VERSION ""

NS_ :

BS_:

BU_: ILC4 ILC3 ILC2 ILC1 C1 C0 ACU ECAS2 CCU TPMS ACC AEBS Door4 Door3 Door2 Door1 WWCU HVAC HVAC_HMI EPHS LDWS SCSM EVCC ECAS1 BMS SWS EBS VCU2 PCi_ECM DCU EPH VFC VCU1 Tachograph EPIC

BO_ 2566834735 DM1_ECAS1: 22 ECAS1
 SG_ FailureModeIdentifier5 : 160|5@1+ (1,0) [0|0] "" Vector__XXX
 SG_ FailureModeIdentifier4 : 128|5@1+ (1,0) [0|0] "" Vector__XXX
 SG_ FailureModeIdentifier3 : 96|5@1+ (1,0) [0|0] "" Vector__XXX
 SG_ FailureModeIdentifier2 : 64|5@1+ (1,0) [0|0] "" Vector__XXX
 SG_ OccurenceCount5 : 168|7@1+ (1,0) [0|126] "" Vector__XXX
 SG_ OccurenceCount4 : 136|7@1+ (1,0) [0|126] "" Vector__XXX
 SG_ OccurenceCount3 : 104|7@1+ (1,0) [0|126] "" Vector__XXX
 SG_ OccurenceCount2 : 72|7@1+ (1,0) [0|126] "" Vector__XXX
 SG_ SPNConversionMethod5 : 175|1@1+ (1,0) [0|1] "" Vector__XXX
 SG_ SPNConversionMethod4 : 143|1@1+ (1,0) [0|1] "" Vector__XXX
 SG_ SPNConversionMethod3 : 111|1@1+ (1,0) [0|1] "" Vector__XXX
 SG_ SPNConversionMethod2 : 79|1@1+ (1,0) [0|1] "" Vector__XXX
 SG_ SPN5High : 165|3@1+ (1,0) [0|7] "" Vector__XXX
 SG_ SPN5 : 144|16@1+ (1,0) [0|65536] "" Vector__XXX
 SG_ SPN4High : 133|3@1+ (1,0) [0|7] "" Vector__XXX
 SG_ SPN4 : 112|16@1+ (1,0) [0|65536] "" Vector__XXX
 SG_ SPN3High : 101|3@1+ (1,0) [0|7] "" Vector__XXX
 SG_ SPN3 : 80|16@1+ (1,0) [0|65536] "" Vector__XXX
 SG_ SPN2High : 69|3@1+ (1,0) [0|7] "" Vector__XXX
 SG_ SPN2 : 48|16@1+ (1,0) [0|65536] "" Vector__XXX
 SG_ SPN1 : 16|16@1+ (1,0) [0|65536] "" Vector__XXX
 SG_ SPNConversionMethod1 : 47|1@1+ (1,0) [0|1] "" Vector__XXX
 SG_ OccurenceCount1 : 40|7@1+ (1,0) [0|126] "" Vector__XXX
 SG_ SPN1High : 37|3@1+ (1,0) [0|7] "" Vector__XXX
 SG_ FailureModeIdentifier1 : 32|5@1+ (1,0) [0|0] "" Vector__XXX
 SG_ FlashMalfuncIndicatorLamp : 14|2@1+ (1,0) [0|3] "" Vector__XXX
 SG_ FlashRedStopLamp : 12|2@1+ (1,0) [0|3] "" Vector__XXX
 SG_ FlashAmberWarningLamp : 10|2@1+ (1,0) [0|3] "" Vector__XXX
 SG_ FlashProtectLamp : 8|2@1+ (1,0) [0|3] "" Vector__XXX
 SG_ MalfunctionIndicatorLampStatus : 6|2@1+ (1,0) [0|3] "" Vector__XXX
 SG_ RedStopLampState : 4|2@1+ (1,0) [0|3] "" Vector__XXX
 SG_ AmberWarningLampStatus : 2|2@1+ (1,0) [0|3] "" Vector__XXX
 SG_ ProtectLampStatus : 0|2@1+ (1,0) [0|3] "" Vector__XXX

BO_ 2566834699 DM1_EBS: 22 EBS
 SG_ FailureModeIdentifier5 : 160|5@1+ (1,0) [0|0] "" Vector__XXX
 SG_ FailureModeIdentifier4 : 128|5@1+ (1,0) [0|0] "" Vector__XXX
 SG_ FailureModeIdentifier3 : 96|5@1+ (1,0) [0|0] "" Vector__XXX
 SG_ FailureModeIdentifier2 : 64|5@1+ (1,0) [0|0] "" Vector__XXX
 SG_ OccurenceCount5 : 168|7@1+ (1,0) [0|126] "" Vector__XXX
 SG_ OccurenceCount4 : 136|7@1+ (1,0) [0|126] "" Vector__XXX
 SG_ OccurenceCount3 : 104|7@1+ (1,0) [0|126] "" Vector__XXX
 SG_ OccurenceCount2 : 72|7@1+ (1,0) [0|126] "" Vector__XXX
 SG_ SPNConversionMethod5 : 175|1@1+ (1,0) [0|1] "" Vector__XXX
 SG_ SPNConversionMethod4 : 143|1@1+ (1,0) [0|1] "" Vector__XXX
 SG_ SPNConversionMethod3 : 111|1@1+ (1,0) [0|1] "" Vector__XXX
 SG_ SPNConversionMethod2 : 79|1@1+ (1,0) [0|1] "" Vector__XXX
 SG_ SPN5High : 165|3@1+ (1,0) [0|7] "" Vector__XXX
 SG_ SPN5 : 144|16@1+ (1,0) [0|65536] "" Vector__XXX
 SG_ SPN4High : 133|3@1+ (1,0) [0|7] "" Vector__XXX
 SG_ SPN4 : 112|16@1+ (1,0) [0|65536] "" Vector__XXX
 SG_ SPN3High : 101|3@1+ (1,0) [0|7] "" Vector__XXX
 SG_ SPN3 : 80|16@1+ (1,0) [0|65536] "" Vector__XXX
 SG_ SPN2High : 69|3@1+ (1,0) [0|7] "" Vector__XXX
 SG_ SPN2 : 48|16@1+ (1,0) [0|65536] "" Vector__XXX
 SG_ SPN1 : 16|16@1+ (1,0) [0|65536] "" Vector__XXX
 SG_ SPNConversionMethod1 : 47|1@1+ (1,0) [0|1] "" Vector__XXX
 SG_ OccurenceCount1 : 40|7@1+ (1,0) [0|126] "" Vector__XXX
 SG_ SPN1High : 37|3@1+ (1,0) [0|7] "" Vector__XXX
 SG_ FailureModeIdentifier1 : 32|5@1+ (1,0) [0|0] "" Vector__XXX
 SG_ FlashMalfuncIndicatorLamp : 14|2@1+ (1,0) [0|3] "" Vector__XXX
 SG_ FlashRedStopLamp : 12|2@1+ (1,0) [0|3] "" Vector__XXX
 SG_ FlashAmberWarningLamp : 10|2@1+ (1,0) [0|3] "" Vector__XXX
 SG_ FlashProtectLamp : 8|2@1+ (1,0) [0|3] "" Vector__XXX
 SG_ MalfunctionIndicatorLampStatus : 6|2@1+ (1,0) [0|3] "" Vector__XXX
 SG_ RedStopLampState : 4|2@1+ (1,0) [0|3] "" Vector__XXX
 SG_ AmberWarningLampStatus : 2|2@1+ (1,0) [0|3] "" Vector__XXX
 SG_ ProtectLampStatus : 0|2@1+ (1,0) [0|3] "" Vector__XXX

BO_ 2566834816 DM1_EVCC: 22 EVCC
 SG_ FailureModeIdentifier5 : 160|5@1+ (1,0) [0|0] "" Vector__XXX
 SG_ FailureModeIdentifier4 : 128|5@1+ (1,0) [0|0] "" Vector__XXX
 SG_ FailureModeIdentifier3 : 96|5@1+ (1,0) [0|0] "" Vector__XXX
 SG_ FailureModeIdentifier2 : 64|5@1+ (1,0) [0|0] "" Vector__XXX
 SG_ OccurenceCount5 : 168|7@1+ (1,0) [0|126] "" Vector__XXX
 SG_ OccurenceCount4 : 136|7@1+ (1,0) [0|126] "" Vector__XXX
 SG_ OccurenceCount3 : 104|7@1+ (1,0) [0|126] "" Vector__XXX
 SG_ OccurenceCount2 : 72|7@1+ (1,0) [0|126] "" Vector__XXX
 SG_ SPNConversionMethod5 : 175|1@1+ (1,0) [0|1] "" Vector__XXX
 SG_ SPNConversionMethod4 : 143|1@1+ (1,0) [0|1] "" Vector__XXX
 SG_ SPNConversionMethod3 : 111|1@1+ (1,0) [0|1] "" Vector__XXX
 SG_ SPNConversionMethod2 : 79|1@1+ (1,0) [0|1] "" Vector__XXX
 SG_ SPN5High : 165|3@1+ (1,0) [0|7] "" Vector__XXX
 SG_ SPN5 : 144|16@1+ (1,0) [0|65536] "" Vector__XXX
 SG_ SPN4High : 133|3@1+ (1,0) [0|7] "" Vector__XXX
 SG_ SPN4 : 112|16@1+ (1,0) [0|65536] "" Vector__XXX
 SG_ SPN3High : 101|3@1+ (1,0) [0|7] "" Vector__XXX
 SG_ SPN3 : 80|16@1+ (1,0) [0|65536] "" Vector__XXX
 SG_ SPN2High : 69|3@1+ (1,0) [0|7] "" Vector__XXX
 SG_ SPN2 : 48|16@1+ (1,0) [0|65536] "" Vector__XXX
 SG_ SPN1 : 16|16@1+ (1,0) [0|65536] "" Vector__XXX
 SG_ SPNConversionMethod1 : 47|1@1+ (1,0) [0|1] "" Vector__XXX
 SG_ OccurenceCount1 : 40|7@1+ (1,0) [0|126] "" Vector__XXX
 SG_ SPN1High : 37|3@1+ (1,0) [0|7] "" Vector__XXX
 SG_ FailureModeIdentifier1 : 32|5@1+ (1,0) [0|0] "" Vector__XXX
 SG_ FlashMalfuncIndicatorLamp : 14|2@1+ (1,0) [0|3] "" Vector__XXX
 SG_ FlashRedStopLamp : 12|2@1+ (1,0) [0|3] "" Vector__XXX
 SG_ FlashAmberWarningLamp : 10|2@1+ (1,0) [0|3] "" Vector__XXX
 SG_ FlashProtectLamp : 8|2@1+ (1,0) [0|3] "" Vector__XXX
 SG_ MalfunctionIndicatorLampStatus : 6|2@1+ (1,0) [0|3] "" Vector__XXX
 SG_ RedStopLampState : 4|2@1+ (1,0) [0|3] "" Vector__XXX
 SG_ AmberWarningLampStatus : 2|2@1+ (1,0) [0|3] "" Vector__XXX
 SG_ ProtectLampStatus : 0|2@1+ (1,0) [0|3] "" Vector__XXX

BO_ 2566834688 DM1_ECM: 22 PCi_ECM
 SG_ FailureModeIdentifier5 : 160|5@1+ (1,0) [0|0] "" Vector__XXX
 SG_ FailureModeIdentifier4 : 128|5@1+ (1,0) [0|0] "" Vector__XXX
 SG_ FailureModeIdentifier3 : 96|5@1+ (1,0) [0|0] "" Vector__XXX
 SG_ FailureModeIdentifier2 : 64|5@1+ (1,0) [0|0] "" Vector__XXX
 SG_ OccurenceCount5 : 168|7@1+ (1,0) [0|126] "" Vector__XXX
 SG_ OccurenceCount4 : 136|7@1+ (1,0) [0|126] "" Vector__XXX
 SG_ OccurenceCount3 : 104|7@1+ (1,0) [0|126] "" Vector__XXX
 SG_ OccurenceCount2 : 72|7@1+ (1,0) [0|126] "" Vector__XXX
 SG_ SPNConversionMethod5 : 175|1@1+ (1,0) [0|1] "" Vector__XXX
 SG_ SPNConversionMethod4 : 143|1@1+ (1,0) [0|1] "" Vector__XXX
 SG_ SPNConversionMethod3 : 111|1@1+ (1,0) [0|1] "" Vector__XXX
 SG_ SPNConversionMethod2 : 79|1@1+ (1,0) [0|1] "" Vector__XXX
 SG_ SPN5High : 165|3@1+ (1,0) [0|7] "" Vector__XXX
 SG_ SPN5 : 144|16@1+ (1,0) [0|65536] "" Vector__XXX
 SG_ SPN4High : 133|3@1+ (1,0) [0|7] "" Vector__XXX
 SG_ SPN4 : 112|16@1+ (1,0) [0|65536] "" Vector__XXX
 SG_ SPN3High : 101|3@1+ (1,0) [0|7] "" Vector__XXX
 SG_ SPN3 : 80|16@1+ (1,0) [0|65536] "" Vector__XXX
 SG_ SPN2High : 69|3@1+ (1,0) [0|7] "" Vector__XXX
 SG_ SPN2 : 48|16@1+ (1,0) [0|65536] "" Vector__XXX
 SG_ SPN1 : 16|16@1+ (1,0) [0|65536] "" Vector__XXX
 SG_ SPNConversionMethod1 : 47|1@1+ (1,0) [0|1] "" Vector__XXX
 SG_ OccurenceCount1 : 40|7@1+ (1,0) [0|126] "" Vector__XXX
 SG_ SPN1High : 37|3@1+ (1,0) [0|7] "" Vector__XXX
 SG_ FailureModeIdentifier1 : 32|5@1+ (1,0) [0|0] "" Vector__XXX
 SG_ FlashMalfuncIndicatorLamp : 14|2@1+ (1,0) [0|3] "" Vector__XXX
 SG_ FlashRedStopLamp : 12|2@1+ (1,0) [0|3] "" Vector__XXX
 SG_ FlashAmberWarningLamp : 10|2@1+ (1,0) [0|3] "" Vector__XXX
 SG_ FlashProtectLamp : 8|2@1+ (1,0) [0|3] "" Vector__XXX
 SG_ MalfunctionIndicatorLampStatus : 6|2@1+ (1,0) [0|3] "" Vector__XXX
 SG_ RedStopLampState : 4|2@1+ (1,0) [0|3] "" Vector__XXX
 SG_ AmberWarningLampStatus : 2|2@1+ (1,0) [0|3] "" Vector__XXX
 SG_ ProtectLampStatus : 0|2@1+ (1,0) [0|3] "" Vector__XXX

BO_ 2566834927 DM1_DCU: 22 DCU
 SG_ FailureModeIdentifier5 : 160|5@1+ (1,0) [0|0] "" Vector__XXX
 SG_ FailureModeIdentifier4 : 128|5@1+ (1,0) [0|0] "" Vector__XXX
 SG_ FailureModeIdentifier3 : 96|5@1+ (1,0) [0|0] "" Vector__XXX
 SG_ FailureModeIdentifier2 : 64|5@1+ (1,0) [0|0] "" Vector__XXX
 SG_ OccurenceCount5 : 168|7@1+ (1,0) [0|126] "" Vector__XXX
 SG_ OccurenceCount4 : 136|7@1+ (1,0) [0|126] "" Vector__XXX
 SG_ OccurenceCount3 : 104|7@1+ (1,0) [0|126] "" Vector__XXX
 SG_ OccurenceCount2 : 72|7@1+ (1,0) [0|126] "" Vector__XXX
 SG_ SPNConversionMethod5 : 175|1@1+ (1,0) [0|1] "" Vector__XXX
 SG_ SPNConversionMethod4 : 143|1@1+ (1,0) [0|1] "" Vector__XXX
 SG_ SPNConversionMethod3 : 111|1@1+ (1,0) [0|1] "" Vector__XXX
 SG_ SPNConversionMethod2 : 79|1@1+ (1,0) [0|1] "" Vector__XXX
 SG_ SPN5High : 165|3@1+ (1,0) [0|7] "" Vector__XXX
 SG_ SPN5 : 144|16@1+ (1,0) [0|65536] "" Vector__XXX
 SG_ SPN4High : 133|3@1+ (1,0) [0|7] "" Vector__XXX
 SG_ SPN4 : 112|16@1+ (1,0) [0|65536] "" Vector__XXX
 SG_ SPN3High : 101|3@1+ (1,0) [0|7] "" Vector__XXX
 SG_ SPN3 : 80|16@1+ (1,0) [0|65536] "" Vector__XXX
 SG_ SPN2High : 69|3@1+ (1,0) [0|7] "" Vector__XXX
 SG_ SPN2 : 48|16@1+ (1,0) [0|65536] "" Vector__XXX
 SG_ SPN1 : 16|16@1+ (1,0) [0|65536] "" Vector__XXX
 SG_ SPNConversionMethod1 : 47|1@1+ (1,0) [0|1] "" Vector__XXX
 SG_ OccurenceCount1 : 40|7@1+ (1,0) [0|126] "" Vector__XXX
 SG_ SPN1High : 37|3@1+ (1,0) [0|7] "" Vector__XXX
 SG_ FailureModeIdentifier1 : 32|5@1+ (1,0) [0|0] "" Vector__XXX
 SG_ FlashMalfuncIndicatorLamp : 14|2@1+ (1,0) [0|3] "" Vector__XXX
 SG_ FlashRedStopLamp : 12|2@1+ (1,0) [0|3] "" Vector__XXX
 SG_ FlashAmberWarningLamp : 10|2@1+ (1,0) [0|3] "" Vector__XXX
 SG_ FlashProtectLamp : 8|2@1+ (1,0) [0|3] "" Vector__XXX
 SG_ MalfunctionIndicatorLampStatus : 6|2@1+ (1,0) [0|3] "" Vector__XXX
 SG_ RedStopLampState : 4|2@1+ (1,0) [0|3] "" Vector__XXX
 SG_ AmberWarningLampStatus : 2|2@1+ (1,0) [0|3] "" Vector__XXX
 SG_ ProtectLampStatus : 0|2@1+ (1,0) [0|3] "" Vector__XXX

BO_ 2566834737 DM1_VFC: 22 VFC
 SG_ FailureModeIdentifier5 : 160|5@1+ (1,0) [0|0] "" Vector__XXX
 SG_ FailureModeIdentifier4 : 128|5@1+ (1,0) [0|0] "" Vector__XXX
 SG_ FailureModeIdentifier3 : 96|5@1+ (1,0) [0|0] "" Vector__XXX
 SG_ FailureModeIdentifier2 : 64|5@1+ (1,0) [0|0] "" Vector__XXX
 SG_ OccurenceCount5 : 168|7@1+ (1,0) [0|126] "" Vector__XXX
 SG_ OccurenceCount4 : 136|7@1+ (1,0) [0|126] "" Vector__XXX
 SG_ OccurenceCount3 : 104|7@1+ (1,0) [0|126] "" Vector__XXX
 SG_ OccurenceCount2 : 72|7@1+ (1,0) [0|126] "" Vector__XXX
 SG_ SPNConversionMethod5 : 175|1@1+ (1,0) [0|1] "" Vector__XXX
 SG_ SPNConversionMethod4 : 143|1@1+ (1,0) [0|1] "" Vector__XXX
 SG_ SPNConversionMethod3 : 111|1@1+ (1,0) [0|1] "" Vector__XXX
 SG_ SPNConversionMethod2 : 79|1@1+ (1,0) [0|1] "" Vector__XXX
 SG_ SPN5High : 165|3@1+ (1,0) [0|7] "" Vector__XXX
 SG_ SPN5 : 144|16@1+ (1,0) [0|65536] "" Vector__XXX
 SG_ SPN4High : 133|3@1+ (1,0) [0|7] "" Vector__XXX
 SG_ SPN4 : 112|16@1+ (1,0) [0|65536] "" Vector__XXX
 SG_ SPN3High : 101|3@1+ (1,0) [0|7] "" Vector__XXX
 SG_ SPN3 : 80|16@1+ (1,0) [0|65536] "" Vector__XXX
 SG_ SPN2High : 69|3@1+ (1,0) [0|7] "" Vector__XXX
 SG_ SPN2 : 48|16@1+ (1,0) [0|65536] "" Vector__XXX
 SG_ SPN1 : 16|16@1+ (1,0) [0|65536] "" Vector__XXX
 SG_ SPNConversionMethod1 : 47|1@1+ (1,0) [0|1] "" Vector__XXX
 SG_ OccurenceCount1 : 40|7@1+ (1,0) [0|126] "" Vector__XXX
 SG_ SPN1High : 37|3@1+ (1,0) [0|7] "" Vector__XXX
 SG_ FailureModeIdentifier1 : 32|5@1+ (1,0) [0|0] "" Vector__XXX
 SG_ FlashMalfuncIndicatorLamp : 14|2@1+ (1,0) [0|3] "" Vector__XXX
 SG_ FlashRedStopLamp : 12|2@1+ (1,0) [0|3] "" Vector__XXX
 SG_ FlashAmberWarningLamp : 10|2@1+ (1,0) [0|3] "" Vector__XXX
 SG_ FlashProtectLamp : 8|2@1+ (1,0) [0|3] "" Vector__XXX
 SG_ MalfunctionIndicatorLampStatus : 6|2@1+ (1,0) [0|3] "" Vector__XXX
 SG_ RedStopLampState : 4|2@1+ (1,0) [0|3] "" Vector__XXX
 SG_ AmberWarningLampStatus : 2|2@1+ (1,0) [0|3] "" Vector__XXX
 SG_ ProtectLampStatus : 0|2@1+ (1,0) [0|3] "" Vector__XXX

BO_ 2566834760 DM1_VCU2: 22 VCU2
 SG_ FailureModeIdentifier5 : 160|5@1+ (1,0) [0|0] "" Vector__XXX
 SG_ FailureModeIdentifier4 : 128|5@1+ (1,0) [0|0] "" Vector__XXX
 SG_ FailureModeIdentifier3 : 96|5@1+ (1,0) [0|0] "" Vector__XXX
 SG_ FailureModeIdentifier2 : 64|5@1+ (1,0) [0|0] "" Vector__XXX
 SG_ OccurenceCount5 : 168|7@1+ (1,0) [0|126] "" Vector__XXX
 SG_ OccurenceCount4 : 136|7@1+ (1,0) [0|126] "" Vector__XXX
 SG_ OccurenceCount3 : 104|7@1+ (1,0) [0|126] "" Vector__XXX
 SG_ OccurenceCount2 : 72|7@1+ (1,0) [0|126] "" Vector__XXX
 SG_ SPNConversionMethod5 : 175|1@1+ (1,0) [0|1] "" Vector__XXX
 SG_ SPNConversionMethod4 : 143|1@1+ (1,0) [0|1] "" Vector__XXX
 SG_ SPNConversionMethod3 : 111|1@1+ (1,0) [0|1] "" Vector__XXX
 SG_ SPNConversionMethod2 : 79|1@1+ (1,0) [0|1] "" Vector__XXX
 SG_ SPN5High : 165|3@1+ (1,0) [0|7] "" Vector__XXX
 SG_ SPN5 : 144|16@1+ (1,0) [0|65536] "" Vector__XXX
 SG_ SPN4High : 133|3@1+ (1,0) [0|7] "" Vector__XXX
 SG_ SPN4 : 112|16@1+ (1,0) [0|65536] "" Vector__XXX
 SG_ SPN3High : 101|3@1+ (1,0) [0|7] "" Vector__XXX
 SG_ SPN3 : 80|16@1+ (1,0) [0|65536] "" Vector__XXX
 SG_ SPN2High : 69|3@1+ (1,0) [0|7] "" Vector__XXX
 SG_ SPN2 : 48|16@1+ (1,0) [0|65536] "" Vector__XXX
 SG_ SPN1 : 16|16@1+ (1,0) [0|65536] "" Vector__XXX
 SG_ SPNConversionMethod1 : 47|1@1+ (1,0) [0|1] "" Vector__XXX
 SG_ OccurenceCount1 : 40|7@1+ (1,0) [0|126] "" Vector__XXX
 SG_ SPN1High : 37|3@1+ (1,0) [0|7] "" Vector__XXX
 SG_ FailureModeIdentifier1 : 32|5@1+ (1,0) [0|0] "" Vector__XXX
 SG_ FlashMalfuncIndicatorLamp : 14|2@1+ (1,0) [0|3] "" Vector__XXX
 SG_ FlashRedStopLamp : 12|2@1+ (1,0) [0|3] "" Vector__XXX
 SG_ FlashAmberWarningLamp : 10|2@1+ (1,0) [0|3] "" Vector__XXX
 SG_ FlashProtectLamp : 8|2@1+ (1,0) [0|3] "" Vector__XXX
 SG_ MalfunctionIndicatorLampStatus : 6|2@1+ (1,0) [0|3] "" Vector__XXX
 SG_ RedStopLampState : 4|2@1+ (1,0) [0|3] "" Vector__XXX
 SG_ AmberWarningLampStatus : 2|2@1+ (1,0) [0|3] "" Vector__XXX
 SG_ ProtectLampStatus : 0|2@1+ (1,0) [0|3] "" Vector__XXX

BO_ 2566834727 DM1_VCU1: 22 VCU1
 SG_ FailureModeIdentifier5 : 160|5@1+ (1,0) [0|0] "" Vector__XXX
 SG_ FailureModeIdentifier4 : 128|5@1+ (1,0) [0|0] "" Vector__XXX
 SG_ FailureModeIdentifier3 : 96|5@1+ (1,0) [0|0] "" Vector__XXX
 SG_ FailureModeIdentifier2 : 64|5@1+ (1,0) [0|0] "" Vector__XXX
 SG_ OccurenceCount5 : 168|7@1+ (1,0) [0|126] "" Vector__XXX
 SG_ OccurenceCount4 : 136|7@1+ (1,0) [0|126] "" Vector__XXX
 SG_ OccurenceCount3 : 104|7@1+ (1,0) [0|126] "" Vector__XXX
 SG_ OccurenceCount2 : 72|7@1+ (1,0) [0|126] "" Vector__XXX
 SG_ SPNConversionMethod5 : 175|1@1+ (1,0) [0|1] "" Vector__XXX
 SG_ SPNConversionMethod4 : 143|1@1+ (1,0) [0|1] "" Vector__XXX
 SG_ SPNConversionMethod3 : 111|1@1+ (1,0) [0|1] "" Vector__XXX
 SG_ SPNConversionMethod2 : 79|1@1+ (1,0) [0|1] "" Vector__XXX
 SG_ SPN5High : 165|3@1+ (1,0) [0|7] "" Vector__XXX
 SG_ SPN5 : 144|16@1+ (1,0) [0|65536] "" Vector__XXX
 SG_ SPN4High : 133|3@1+ (1,0) [0|7] "" Vector__XXX
 SG_ SPN4 : 112|16@1+ (1,0) [0|65536] "" Vector__XXX
 SG_ SPN3High : 101|3@1+ (1,0) [0|7] "" Vector__XXX
 SG_ SPN3 : 80|16@1+ (1,0) [0|65536] "" Vector__XXX
 SG_ SPN2High : 69|3@1+ (1,0) [0|7] "" Vector__XXX
 SG_ SPN2 : 48|16@1+ (1,0) [0|65536] "" Vector__XXX
 SG_ SPN1 : 16|16@1+ (1,0) [0|65536] "" Vector__XXX
 SG_ SPNConversionMethod1 : 47|1@1+ (1,0) [0|1] "" Vector__XXX
 SG_ OccurenceCount1 : 40|7@1+ (1,0) [0|126] "" Vector__XXX
 SG_ SPN1High : 37|3@1+ (1,0) [0|7] "" Vector__XXX
 SG_ FailureModeIdentifier1 : 32|5@1+ (1,0) [0|0] "" Vector__XXX
 SG_ FlashMalfuncIndicatorLamp : 14|2@1+ (1,0) [0|3] "" Vector__XXX
 SG_ FlashRedStopLamp : 12|2@1+ (1,0) [0|3] "" Vector__XXX
 SG_ FlashAmberWarningLamp : 10|2@1+ (1,0) [0|3] "" Vector__XXX
 SG_ FlashProtectLamp : 8|2@1+ (1,0) [0|3] "" Vector__XXX
 SG_ MalfunctionIndicatorLampStatus : 6|2@1+ (1,0) [0|3] "" Vector__XXX
 SG_ RedStopLampState : 4|2@1+ (1,0) [0|3] "" Vector__XXX
 SG_ AmberWarningLampStatus : 2|2@1+ (1,0) [0|3] "" Vector__XXX
 SG_ ProtectLampStatus : 0|2@1+ (1,0) [0|3] "" Vector__XXX

BO_ 2566834926 DM1_TCO: 22 Tachograph
 SG_ FailureModeIdentifier5 : 160|5@1+ (1,0) [0|0] "" Vector__XXX
 SG_ FailureModeIdentifier4 : 128|5@1+ (1,0) [0|0] "" Vector__XXX
 SG_ FailureModeIdentifier3 : 96|5@1+ (1,0) [0|0] "" Vector__XXX
 SG_ FailureModeIdentifier2 : 64|5@1+ (1,0) [0|0] "" Vector__XXX
 SG_ OccurenceCount5 : 168|7@1+ (1,0) [0|126] "" Vector__XXX
 SG_ OccurenceCount4 : 136|7@1+ (1,0) [0|126] "" Vector__XXX
 SG_ OccurenceCount3 : 104|7@1+ (1,0) [0|126] "" Vector__XXX
 SG_ OccurenceCount2 : 72|7@1+ (1,0) [0|126] "" Vector__XXX
 SG_ SPNConversionMethod5 : 175|1@1+ (1,0) [0|1] "" Vector__XXX
 SG_ SPNConversionMethod4 : 143|1@1+ (1,0) [0|1] "" Vector__XXX
 SG_ SPNConversionMethod3 : 111|1@1+ (1,0) [0|1] "" Vector__XXX
 SG_ SPNConversionMethod2 : 79|1@1+ (1,0) [0|1] "" Vector__XXX
 SG_ SPN5High : 165|3@1+ (1,0) [0|7] "" Vector__XXX
 SG_ SPN5 : 144|16@1+ (1,0) [0|65536] "" Vector__XXX
 SG_ SPN4High : 133|3@1+ (1,0) [0|7] "" Vector__XXX
 SG_ SPN4 : 112|16@1+ (1,0) [0|65536] "" Vector__XXX
 SG_ SPN3High : 101|3@1+ (1,0) [0|7] "" Vector__XXX
 SG_ SPN3 : 80|16@1+ (1,0) [0|65536] "" Vector__XXX
 SG_ SPN2High : 69|3@1+ (1,0) [0|7] "" Vector__XXX
 SG_ SPN2 : 48|16@1+ (1,0) [0|65536] "" Vector__XXX
 SG_ SPN1 : 16|16@1+ (1,0) [0|65536] "" Vector__XXX
 SG_ SPNConversionMethod1 : 47|1@1+ (1,0) [0|1] "" Vector__XXX
 SG_ OccurenceCount1 : 40|7@1+ (1,0) [0|126] "" Vector__XXX
 SG_ SPN1High : 37|3@1+ (1,0) [0|7] "" Vector__XXX
 SG_ FailureModeIdentifier1 : 32|5@1+ (1,0) [0|0] "" Vector__XXX
 SG_ FlashMalfuncIndicatorLamp : 14|2@1+ (1,0) [0|3] "" Vector__XXX
 SG_ FlashRedStopLamp : 12|2@1+ (1,0) [0|3] "" Vector__XXX
 SG_ FlashAmberWarningLamp : 10|2@1+ (1,0) [0|3] "" Vector__XXX
 SG_ FlashProtectLamp : 8|2@1+ (1,0) [0|3] "" Vector__XXX
 SG_ MalfunctionIndicatorLampStatus : 6|2@1+ (1,0) [0|3] "" Vector__XXX
 SG_ RedStopLampState : 4|2@1+ (1,0) [0|3] "" Vector__XXX
 SG_ AmberWarningLampStatus : 2|2@1+ (1,0) [0|3] "" Vector__XXX
 SG_ ProtectLampStatus : 0|2@1+ (1,0) [0|3] "" Vector__XXX

BO_ 2566834768 DM1_EPH: 22 EPH
 SG_ FailureModeIdentifier5 : 160|5@1+ (1,0) [0|0] "" Vector__XXX
 SG_ FailureModeIdentifier4 : 128|5@1+ (1,0) [0|0] "" Vector__XXX
 SG_ FailureModeIdentifier3 : 96|5@1+ (1,0) [0|0] "" Vector__XXX
 SG_ FailureModeIdentifier2 : 64|5@1+ (1,0) [0|0] "" Vector__XXX
 SG_ OccurenceCount5 : 168|7@1+ (1,0) [0|126] "" Vector__XXX
 SG_ OccurenceCount4 : 136|7@1+ (1,0) [0|126] "" Vector__XXX
 SG_ OccurenceCount3 : 104|7@1+ (1,0) [0|126] "" Vector__XXX
 SG_ OccurenceCount2 : 72|7@1+ (1,0) [0|126] "" Vector__XXX
 SG_ SPNConversionMethod5 : 175|1@1+ (1,0) [0|1] "" Vector__XXX
 SG_ SPNConversionMethod4 : 143|1@1+ (1,0) [0|1] "" Vector__XXX
 SG_ SPNConversionMethod3 : 111|1@1+ (1,0) [0|1] "" Vector__XXX
 SG_ SPNConversionMethod2 : 79|1@1+ (1,0) [0|1] "" Vector__XXX
 SG_ SPN5High : 165|3@1+ (1,0) [0|7] "" Vector__XXX
 SG_ SPN5 : 144|16@1+ (1,0) [0|65536] "" Vector__XXX
 SG_ SPN4High : 133|3@1+ (1,0) [0|7] "" Vector__XXX
 SG_ SPN4 : 112|16@1+ (1,0) [0|65536] "" Vector__XXX
 SG_ SPN3High : 101|3@1+ (1,0) [0|7] "" Vector__XXX
 SG_ SPN3 : 80|16@1+ (1,0) [0|65536] "" Vector__XXX
 SG_ SPN2High : 69|3@1+ (1,0) [0|7] "" Vector__XXX
 SG_ SPN2 : 48|16@1+ (1,0) [0|65536] "" Vector__XXX
 SG_ SPN1 : 16|16@1+ (1,0) [0|65536] "" Vector__XXX
 SG_ SPNConversionMethod1 : 47|1@1+ (1,0) [0|1] "" Vector__XXX
 SG_ OccurenceCount1 : 40|7@1+ (1,0) [0|126] "" Vector__XXX
 SG_ SPN1High : 37|3@1+ (1,0) [0|7] "" Vector__XXX
 SG_ FailureModeIdentifier1 : 32|5@1+ (1,0) [0|0] "" Vector__XXX
 SG_ FlashMalfuncIndicatorLamp : 14|2@1+ (1,0) [0|3] "" Vector__XXX
 SG_ FlashRedStopLamp : 12|2@1+ (1,0) [0|3] "" Vector__XXX
 SG_ FlashAmberWarningLamp : 10|2@1+ (1,0) [0|3] "" Vector__XXX
 SG_ FlashProtectLamp : 8|2@1+ (1,0) [0|3] "" Vector__XXX
 SG_ MalfunctionIndicatorLampStatus : 6|2@1+ (1,0) [0|3] "" Vector__XXX
 SG_ RedStopLampState : 4|2@1+ (1,0) [0|3] "" Vector__XXX
 SG_ AmberWarningLampStatus : 2|2@1+ (1,0) [0|3] "" Vector__XXX
 SG_ ProtectLampStatus : 0|2@1+ (1,0) [0|3] "" Vector__XXX

BO_ 2566834931 DM1_BMS: 22 BMS
 SG_ FailureModeIdentifier5 : 160|5@1+ (1,0) [0|0] "" Vector__XXX
 SG_ FailureModeIdentifier4 : 128|5@1+ (1,0) [0|0] "" Vector__XXX
 SG_ FailureModeIdentifier3 : 96|5@1+ (1,0) [0|0] "" Vector__XXX
 SG_ FailureModeIdentifier2 : 64|5@1+ (1,0) [0|0] "" Vector__XXX
 SG_ OccurenceCount5 : 168|7@1+ (1,0) [0|126] "" Vector__XXX
 SG_ OccurenceCount4 : 136|7@1+ (1,0) [0|126] "" Vector__XXX
 SG_ OccurenceCount3 : 104|7@1+ (1,0) [0|126] "" Vector__XXX
 SG_ OccurenceCount2 : 72|7@1+ (1,0) [0|126] "" Vector__XXX
 SG_ SPNConversionMethod5 : 175|1@1+ (1,0) [0|1] "" Vector__XXX
 SG_ SPNConversionMethod4 : 143|1@1+ (1,0) [0|1] "" Vector__XXX
 SG_ SPNConversionMethod3 : 111|1@1+ (1,0) [0|1] "" Vector__XXX
 SG_ SPNConversionMethod2 : 79|1@1+ (1,0) [0|1] "" Vector__XXX
 SG_ SPN5High : 165|3@1+ (1,0) [0|7] "" Vector__XXX
 SG_ SPN5 : 144|16@1+ (1,0) [0|65536] "" Vector__XXX
 SG_ SPN4High : 133|3@1+ (1,0) [0|7] "" Vector__XXX
 SG_ SPN4 : 112|16@1+ (1,0) [0|65536] "" Vector__XXX
 SG_ SPN3High : 101|3@1+ (1,0) [0|7] "" Vector__XXX
 SG_ SPN3 : 80|16@1+ (1,0) [0|65536] "" Vector__XXX
 SG_ SPN2High : 69|3@1+ (1,0) [0|7] "" Vector__XXX
 SG_ SPN2 : 48|16@1+ (1,0) [0|65536] "" Vector__XXX
 SG_ SPN1 : 16|16@1+ (1,0) [0|65536] "" Vector__XXX
 SG_ SPNConversionMethod1 : 47|1@1+ (1,0) [0|1] "" Vector__XXX
 SG_ OccurenceCount1 : 40|7@1+ (1,0) [0|126] "" Vector__XXX
 SG_ SPN1High : 37|3@1+ (1,0) [0|7] "" Vector__XXX
 SG_ FailureModeIdentifier1 : 32|5@1+ (1,0) [0|0] "" Vector__XXX
 SG_ FlashMalfuncIndicatorLamp : 14|2@1+ (1,0) [0|3] "" Vector__XXX
 SG_ FlashRedStopLamp : 12|2@1+ (1,0) [0|3] "" Vector__XXX
 SG_ FlashAmberWarningLamp : 10|2@1+ (1,0) [0|3] "" Vector__XXX
 SG_ FlashProtectLamp : 8|2@1+ (1,0) [0|3] "" Vector__XXX
 SG_ MalfunctionIndicatorLampStatus : 6|2@1+ (1,0) [0|3] "" Vector__XXX
 SG_ RedStopLampState : 4|2@1+ (1,0) [0|3] "" Vector__XXX
 SG_ AmberWarningLampStatus : 2|2@1+ (1,0) [0|3] "" Vector__XXX
 SG_ ProtectLampStatus : 0|2@1+ (1,0) [0|3] "" Vector__XXX

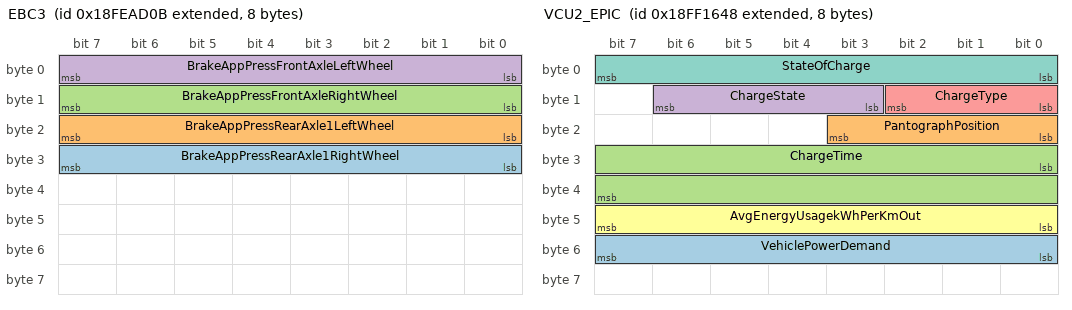
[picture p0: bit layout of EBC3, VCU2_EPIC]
BO_ 2566827275 EBC3: 8 EBS
 SG_ BrakeAppPressRearAxle1RightWheel : 24|8@1+ (5,0) [0|1275] "kPa" Vector__XXX
 SG_ BrakeAppPressRearAxle1LeftWheel : 16|8@1+ (5,0) [0|1275] "kPa" Vector__XXX
 SG_ BrakeAppPressFrontAxleRightWheel : 8|8@1+ (5,0) [0|1275] "kPa" Vector__XXX
 SG_ BrakeAppPressFrontAxleLeftWheel : 0|8@1+ (5,0) [0|1275] "kPa" Vector__XXX

BO_ 2364539904 EEC1: 8 PCi_ECM
 SG_ EngSpeed : 24|16@1+ (0.125,0) [0|8031.875] "rpm" Vector__XXX

BO_ 2566719232 DLCC1: 8 PCi_ECM
 SG_ MalFncIndLmpCmd : 6|2@1- (1,0) [0|0] "" Vector__XXX

BO_ 2566854216 VCU2_EPIC: 8 VCU2
 SG_ VehiclePowerDemand : 48|8@1+ (1,-125) [0|0] "%" Vector__XXX
 SG_ PantographPosition : 16|4@1+ (1,0) [0|16] "" Vector__XXX
 SG_ ChargeTime : 24|16@1+ (1,0) [0|0] "min" Vector__XXX
 SG_ ChargeState : 11|4@1+ (1,0) [0|14] "" Vector__XXX
 SG_ ChargeType : 8|3@1+ (1,0) [0|7] "" Vector__XXX
 SG_ AvgEnergyUsagekWhPerKmOut : 40|8@1+ (1,0) [0|5000] "kWh/100km" Vector__XXX
 SG_ StateOfCharge : 0|8@1+ (0.4,0) [0|0] "%" Vector__XXX

BO_ 2566803211 VDC1: 8 EBS
 SG_ VDCFullyOperational : 2|2@1+ (1,0) [0|3] "" Vector__XXX
 SG_ VDCInformationSignal : 0|2@1+ (1,0) [0|3] "" Vector__XXX

BO_ 2566804992 AT1Tl1: 8 PCi_ECM
 SG_ CatalystTankLevel : 0|8@1+ (0.4,0) [0|100] "%" Vector__XXX

BO_ 2566701807 HSS1: 8 DCU
 SG_ PropulsionSystemActive : 8|2@1+ (1,0) [0|0] "" Vector__XXX

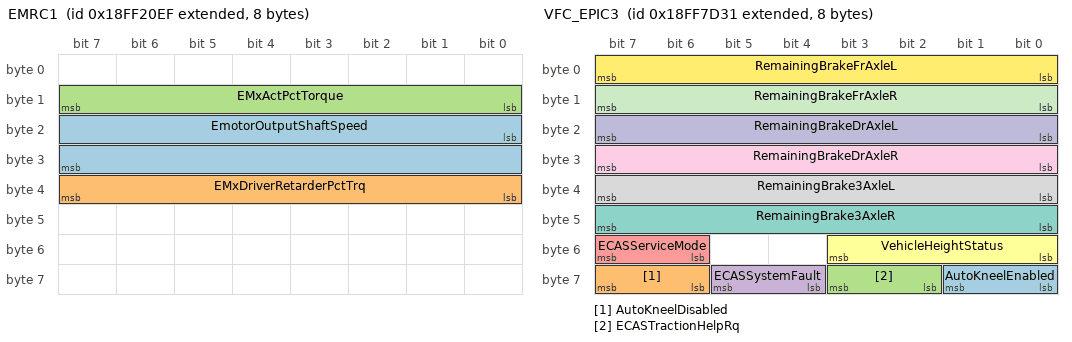
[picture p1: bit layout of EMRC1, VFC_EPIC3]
BO_ 2566856943 EMRC1: 8 DCU
 SG_ EmotorOutputShaftSpeed : 16|16@1+ (0.25,0) [0|0] "rpm" Vector__XXX
 SG_ EMxDriverRetarderPctTrq : 32|8@1+ (1,-125) [0|0] "%" Vector__XXX
 SG_ EMxActPctTorque : 8|8@1+ (1,-125) [0|0] "%" Vector__XXX

BO_ 2565866991 ETC2: 8 DCU
 SG_ TransCurrentGear : 24|8@1+ (1,-125) [-125|125] "" Vector__XXX

BO_ 2566896720 EPH1: 8 EPH
 SG_ ParkBrakeStateLamp : 6|2@1+ (1,0) [0|0] "" Vector__XXX

BO_ 2566834942 DM1: 22 Vector__XXX
 SG_ FailureModeIdentifier5 : 160|5@1+ (1,0) [0|0] "" Vector__XXX
 SG_ FailureModeIdentifier4 : 128|5@1+ (1,0) [0|0] "" Vector__XXX
 SG_ FailureModeIdentifier3 : 96|5@1+ (1,0) [0|0] "" Vector__XXX
 SG_ FailureModeIdentifier2 : 64|5@1+ (1,0) [0|0] "" Vector__XXX
 SG_ OccurenceCount5 : 168|7@1+ (1,0) [0|126] "" Vector__XXX
 SG_ OccurenceCount4 : 136|7@1+ (1,0) [0|126] "" Vector__XXX
 SG_ OccurenceCount3 : 104|7@1+ (1,0) [0|126] "" Vector__XXX
 SG_ OccurenceCount2 : 72|7@1+ (1,0) [0|126] "" Vector__XXX
 SG_ SPNConversionMethod5 : 175|1@1+ (1,0) [0|1] "" Vector__XXX
 SG_ SPNConversionMethod4 : 143|1@1+ (1,0) [0|1] "" Vector__XXX
 SG_ SPNConversionMethod3 : 111|1@1+ (1,0) [0|1] "" Vector__XXX
 SG_ SPNConversionMethod2 : 79|1@1+ (1,0) [0|1] "" Vector__XXX
 SG_ SPN5High : 165|3@1+ (1,0) [0|7] "" Vector__XXX
 SG_ SPN5 : 144|16@1+ (1,0) [0|65536] "" Vector__XXX
 SG_ SPN4High : 133|3@1+ (1,0) [0|7] "" Vector__XXX
 SG_ SPN4 : 112|16@1+ (1,0) [0|65536] "" Vector__XXX
 SG_ SPN3High : 101|3@1+ (1,0) [0|7] "" Vector__XXX
 SG_ SPN3 : 80|16@1+ (1,0) [0|65536] "" Vector__XXX
 SG_ SPN2High : 69|3@1+ (1,0) [0|7] "" Vector__XXX
 SG_ SPN2 : 48|16@1+ (1,0) [0|65536] "" Vector__XXX
 SG_ SPN1 : 16|16@1+ (1,0) [0|65536] "" Vector__XXX
 SG_ SPNConversionMethod1 : 47|1@1+ (1,0) [0|1] "" Vector__XXX
 SG_ OccurenceCount1 : 40|7@1+ (1,0) [0|126] "" Vector__XXX
 SG_ SPN1High : 37|3@1+ (1,0) [0|7] "" Vector__XXX
 SG_ FailureModeIdentifier1 : 32|5@1+ (1,0) [0|0] "" Vector__XXX
 SG_ FlashMalfuncIndicatorLamp : 14|2@1+ (1,0) [0|3] "" Vector__XXX
 SG_ FlashRedStopLamp : 12|2@1+ (1,0) [0|3] "" Vector__XXX
 SG_ FlashAmberWarningLamp : 10|2@1+ (1,0) [0|3] "" Vector__XXX
 SG_ FlashProtectLamp : 8|2@1+ (1,0) [0|3] "" Vector__XXX
 SG_ MalfunctionIndicatorLampStatus : 6|2@1+ (1,0) [0|3] "" Vector__XXX
 SG_ RedStopLampState : 4|2@1+ (1,0) [0|3] "" Vector__XXX
 SG_ AmberWarningLampStatus : 2|2@1+ (1,0) [0|3] "" Vector__XXX
 SG_ ProtectLampStatus : 0|2@1+ (1,0) [0|3] "" Vector__XXX

BO_ 2566880561 VFC_EPIC3: 8 VFC
 SG_ AutoKneelEnabled : 56|2@1+ (1,0) [0|0] "" Vector__XXX
 SG_ AutoKneelDisabled : 62|2@1+ (1,0) [0|0] "" Vector__XXX
 SG_ ECASTractionHelpRq : 58|2@1+ (1,0) [0|0] "" Vector__XXX
 SG_ ECASSystemFault : 60|2@1+ (1,0) [0|0] "" Vector__XXX
 SG_ ECASServiceMode : 54|2@1+ (1,0) [0|0] "" Vector__XXX
 SG_ VehicleHeightStatus : 48|4@1+ (1,0) [0|0] "" Vector__XXX
 SG_ RemainingBrake3AxleR : 40|8@1+ (1,0) [0|255] "%" Vector__XXX
 SG_ RemainingBrake3AxleL : 32|8@1+ (1,0) [0|255] "%" Vector__XXX
 SG_ RemainingBrakeDrAxleR : 24|8@1+ (1,0) [0|255] "%" Vector__XXX
 SG_ RemainingBrakeDrAxleL : 16|8@1+ (1,0) [0|255] "%" Vector__XXX
 SG_ RemainingBrakeFrAxleR : 8|8@1+ (1,0) [0|255] "%" Vector__XXX
 SG_ RemainingBrakeFrAxleL : 0|8@1+ (1,0) [0|255] "%" Vector__XXX

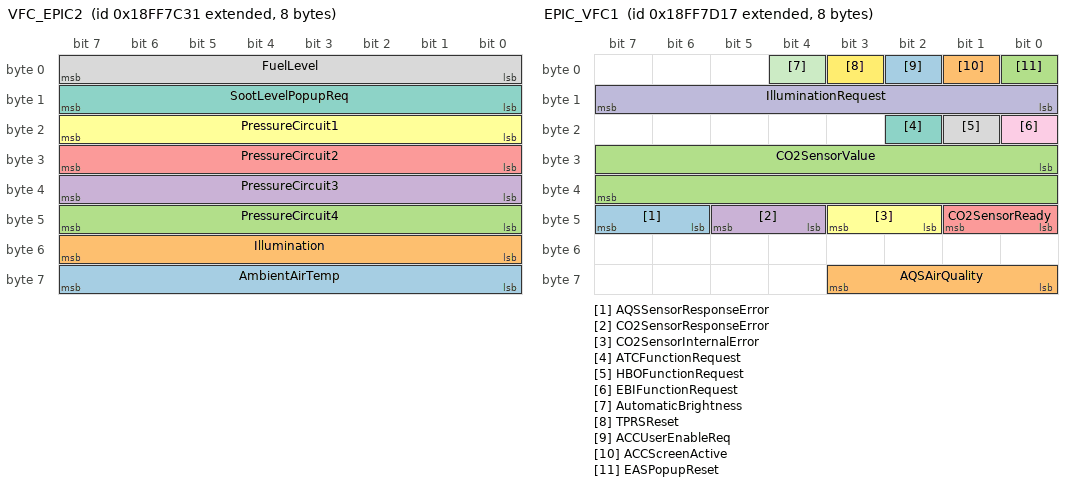
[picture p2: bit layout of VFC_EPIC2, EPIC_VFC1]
BO_ 2566880305 VFC_EPIC2: 8 VFC
 SG_ AmbientAirTemp : 56|8@1+ (0.4,-40) [-40|60] "°C" Vector__XXX
 SG_ Illumination : 48|8@1+ (1,0) [0|0] "%" Vector__XXX
 SG_ PressureCircuit4 : 40|8@1+ (8,0) [0|2000] "kPa" Vector__XXX
 SG_ PressureCircuit3 : 32|8@1+ (8,0) [0|2000] "kPa" Vector__XXX
 SG_ PressureCircuit2 : 24|8@1+ (8,0) [0|2000] "kPa" Vector__XXX
 SG_ PressureCircuit1 : 16|8@1+ (8,0) [0|2000] "kPa" Vector__XXX
 SG_ SootLevelPopupReq : 8|8@1+ (1,0) [0|255] "" Vector__XXX
 SG_ FuelLevel : 0|8@1+ (0.4,0) [0|255] "%" Vector__XXX

BO_ 2566880049 VFC_EPIC1: 8 VFC
 SG_ ExternalAirConnect : 53|1@1+ (1,0) [0|0] "" Vector__XXX
 SG_ OilFillerFlapOpen : 61|1@1+ (1,0) [0|0] "" Vector__XXX
 SG_ FuelFlapOpen : 55|1@1+ (1,0) [0|0] "" Vector__XXX
 SG_ RampDoor2Out : 49|1@1+ (1,0) [0|0] "" Vector__XXX
 SG_ Ramp_Door2_Override : 50|1@1+ (1,0) [0|0] "" Vector__XXX
 SG_ On_boardComputerWarning_ITxPT : 11|1@1+ (1,0) [0|0] "" Vector__XXX
 SG_ HaltBrakeBuzzerRequest : 60|1@1+ (1,0) [0|0] "" Vector__XXX
 SG_ ChargeplugFlapOpen : 57|1@1+ (1,0) [0|0] "" Vector__XXX
 SG_ RearFlapOpen : 56|1@1+ (1,0) [0|0] "" Vector__XXX
 SG_ BatteryFlapOpen : 54|1@1+ (1,0) [0|0] "" Vector__XXX
 SG_ ForwardCollisonWarning : 51|1@1+ (1,0) [0|0] "" Vector__XXX
 SG_ DoorSystemBuzzerRequest : 10|1@1+ (1,0) [0|0] "" Vector__XXX
 SG_ ReverseGearBuzzerOff : 38|1@1+ (1,0) [0|0] "" Vector__XXX
 SG_ HBOConfirmRequest : 63|1@1+ (1,0) [0|0] "" Vector__XXX
 SG_ StopRequestDisabledPass : 41|1@1+ (1,0) [0|0] "" Vector__XXX
 SG_ StopRequest : 40|1@1+ (1,0) [0|0] "" Vector__XXX
 SG_ FrostWarning : 46|1@1+ (1,0) [0|0] "" Vector__XXX
 SG_ EmergencyHammers : 47|1@1+ (1,0) [0|0] "" Vector__XXX
 SG_ ASRSwitchActive : 36|1@1+ (1,0) [0|0] "" Vector__XXX
 SG_ EBISwitchOff : 37|1@1+ (1,0) [0|0] "" Vector__XXX
 SG_ HaltbrakeOverrule : 34|1@1+ (1,0) [0|0] "" Vector__XXX
 SG_ HaltbrakeActive : 33|1@1+ (1,0) [0|0] "" Vector__XXX
 SG_ HVHeaterActive : 7|1@1+ (1,0) [0|0] "" Vector__XXX
 SG_ HillHolderState : 6|1@1+ (1,0) [0|0] "" Vector__XXX
 SG_ AuxHeaterActive : 5|1@1+ (1,0) [0|0] "" Vector__XXX
 SG_ AlarmPassengers : 2|1@1+ (1,0) [0|0] "" Vector__XXX
 SG_ AEBSSwitchedOff : 4|1@1+ (1,0) [0|0] "" Vector__XXX
 SG_ AutoWipersActive : 35|1@1+ (1,0) [0|0] "" Vector__XXX
 SG_ DirectionIndicatorTrailer : 31|1@1+ (1,0) [0|0] "" Vector__XXX
 SG_ DirectionIndicatorRe : 30|1@1+ (1,0) [0|0] "" Vector__XXX
 SG_ DirectionIndicatorLe : 29|1@1+ (1,0) [0|0] "" Vector__XXX
 SG_ FrontFogLight : 28|1@1+ (1,0) [0|0] "" Vector__XXX
 SG_ RearFogLight : 27|1@1+ (1,0) [0|0] "" Vector__XXX
 SG_ HighBeam : 26|1@1+ (1,0) [0|0] "" Vector__XXX
 SG_ LowBeam : 25|1@1+ (1,0) [0|0] "" Vector__XXX
 SG_ PositionLight : 24|1@1+ (1,0) [0|0] "" Vector__XXX
 SG_ PressureCircuit3_4Low : 22|1@1+ (1,0) [0|0] "" Vector__XXX
 SG_ PressureCircuit1_2Low : 21|1@1+ (1,0) [0|0] "" Vector__XXX
 SG_ FuelLevelLow : 20|1@1+ (1,0) [0|0] "" Vector__XXX
 SG_ ECASDisabled : 19|1@1+ (1,0) [0|0] "" Vector__XXX
 SG_ SeatbeltBuzzerWarning : 18|1@1+ (1,0) [0|0] "" Vector__XXX
 SG_ SeatBeltWarning : 17|1@1+ (1,0) [0|0] "" Vector__XXX
 SG_ WiperFluidLevelLow : 16|1@1+ (1,0) [0|0] "" Vector__XXX
 SG_ EASNotification : 12|1@1+ (1,0) [0|0] "" Vector__XXX
 SG_ RegenerationImpossible : 9|1@1+ (1,0) [0|0] "" Vector__XXX
 SG_ RegenerationInhibited : 8|1@1+ (1,0) [0|0] "" Vector__XXX
 SG_ EmergencyDoorOpen : 3|1@1+ (1,0) [0|0] "" Vector__XXX
 SG_ CoolantLevelToLow : 1|1@1+ (1,0) [0|0] "" Vector__XXX
 SG_ CoolantLevelLow : 0|1@1+ (1,0) [0|0] "" Vector__XXX

BO_ 2566851111 VCU_VFC1: 8 VCU1
 SG_ RearFlapOpen : 62|1@1+ (1,0) [0|0] "" Vector__XXX
 SG_ ThermalRunawayAlertState : 60|2@1+ (1,0) [0|0] "" Vector__XXX
 SG_ BlindSpotDetectionIndication : 58|2@1+ (1,0) [0|0] "" Vector__XXX
 SG_ HazardLightsRequest : 56|2@1+ (1,0) [0|0] "" Vector__XXX
 SG_ VoltageLow : 54|2@1+ (1,0) [0|0] "" Vector__XXX
 SG_ PantographRaised : 52|2@1+ (1,0) [0|0] "" Vector__XXX
 SG_ TractionHelpRequest : 50|2@1+ (1,0) [0|0] "" Vector__XXX
 SG_ Axle3Present : 48|2@1+ (1,0) [0|0] "" Vector__XXX
 SG_ EngineCoolantTemp : 40|8@1+ (1,-40) [0|0] "degC" Vector__XXX
 SG_ PowerLimitation : 32|8@1+ (1,0) [0|0] "" Vector__XXX
 SG_ WakeUpVFCPreHeaterClock : 25|1@1+ (1,0) [0|0] "" Vector__XXX
 SG_ WakeUpVCU2 : 24|1@1+ (1,0) [0|0] "" Vector__XXX
 SG_ WakeUpVCUCCURequest : 23|1@1+ (1,0) [0|0] "" Vector__XXX
 SG_ WakeUpVCUChargeButton : 22|1@1+ (1,0) [0|0] "" Vector__XXX
 SG_ WakeUpVCUMainSwitch : 21|1@1+ (1,0) [0|0] "" Vector__XXX
 SG_ WakeUpVCUHazardSwitch : 20|1@1+ (1,0) [0|0] "" Vector__XXX
 SG_ WakeUpVCURemoteUsed : 19|1@1+ (1,0) [0|0] "" Vector__XXX
 SG_ WakeUpVFCCleaningButton : 18|1@1+ (1,0) [0|0] "" Vector__XXX
 SG_ WakeUpVFCDoor2Button : 17|1@1+ (1,0) [0|0] "" Vector__XXX
 SG_ WakeUpVFCDoor1Button : 16|1@1+ (1,0) [0|0] "" Vector__XXX
 SG_ VehicleState : 8|8@1+ (1,0) [0|0] "" Vector__XXX
 SG_ PowerSupplyState : 0|8@1+ (1,0) [0|0] "" Vector__XXX

BO_ 2566880535 EPIC_VFC1: 8 EPIC
 SG_ AQSSensorResponseError : 46|2@1+ (1,0) [0|0] "" Vector__XXX
 SG_ AQSAirQuality : 56|4@1+ (1,0) [0|0] "" Vector__XXX
 SG_ CO2SensorValue : 24|16@1+ (1,0) [0|0] "ppm" Vector__XXX
 SG_ CO2SensorResponseError : 44|2@1+ (1,0) [0|0] "" Vector__XXX
 SG_ CO2SensorReady : 40|2@1+ (1,0) [0|0] "" Vector__XXX
 SG_ CO2SensorInternalError : 42|2@1+ (1,0) [0|0] "" Vector__XXX
 SG_ ATCFunctionRequest : 18|1@1+ (1,0) [0|0] "" Vector__XXX
 SG_ HBOFunctionRequest : 17|1@1+ (1,0) [0|0] "" Vector__XXX
 SG_ EBIFunctionRequest : 16|1@1+ (1,0) [0|0] "" Vector__XXX
 SG_ IlluminationRequest : 8|8@1+ (1,0) [0|0] "" Vector__XXX
 SG_ AutomaticBrightness : 4|1@1+ (1,0) [0|0] "" Vector__XXX
 SG_ TPRSReset : 3|1@1+ (1,0) [0|0] "" Vector__XXX
 SG_ ACCUserEnableReq : 2|1@1+ (1,0) [0|0] "" Vector__XXX
 SG_ ACCScreenActive : 1|1@1+ (1,0) [0|0] "" Vector__XXX
 SG_ EASPopupReset : 0|1@1+ (1,0) [0|0] "" Vector__XXX

BO_ 2566832622 VDHR: 8 Tachograph
 SG_ HighResolutionTripDistance : 32|32@1+ (0.005,0) [0|21055406] "km" Vector__XXX
 SG_ HghReslutionTotalVehicleDistance : 0|32@1+ (0.005,0) [0|21055406] "km" Vector__XXX

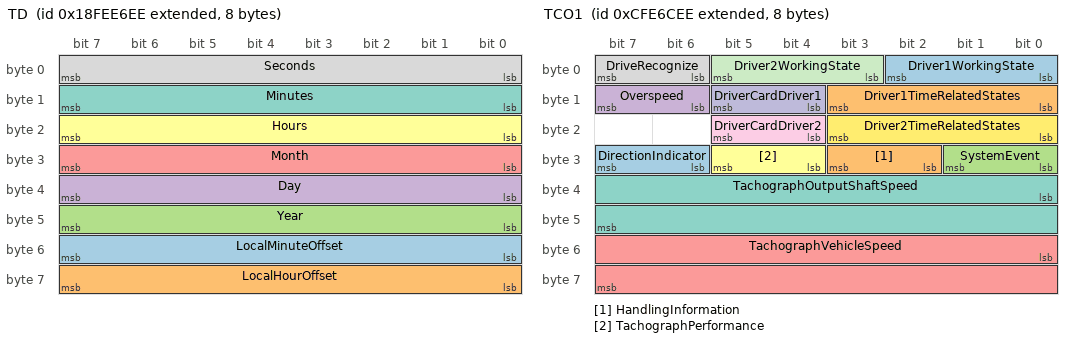
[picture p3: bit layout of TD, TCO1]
BO_ 2566842094 TD: 8 Tachograph
 SG_ LocalMinuteOffset : 48|8@1+ (1,-125) [-125|125] "mins" Vector__XXX
 SG_ LocalHourOffset : 56|8@1+ (1,-125) [-125|125] "hr" Vector__XXX
 SG_ Year : 40|8@1+ (1,1985) [1985|2235] "years" Vector__XXX
 SG_ Day : 32|8@1+ (0.25,0) [0|62.5] "days" Vector__XXX
 SG_ Month : 24|8@1+ (1,0) [0|250] "months" Vector__XXX
 SG_ Hours : 16|8@1+ (1,0) [0|250] "hr" Vector__XXX
 SG_ Minutes : 8|8@1+ (1,0) [0|250] "min" Vector__XXX
 SG_ Seconds : 0|8@1+ (0.25,0) [0|62.5] "s" Vector__XXX

BO_ 2365484270 TCO1: 8 Tachograph
 SG_ DirectionIndicator : 30|2@1+ (1,0) [0|3] "" Vector__XXX
 SG_ HandlingInformation : 26|2@1+ (1,0) [0|3] "" Vector__XXX
 SG_ SystemEvent : 24|2@1+ (1,0) [0|3] "" Vector__XXX
 SG_ Overspeed : 14|2@1+ (1,0) [0|3] "" Vector__XXX
 SG_ TachographVehicleSpeed : 48|16@1+ (0.00390625,0) [0|250.996] "km/h" Vector__XXX
 SG_ TachographPerformance : 28|2@1+ (1,0) [0|3] "" Vector__XXX
 SG_ TachographOutputShaftSpeed : 32|16@1+ (0.125,0) [0|8031.875] "rpm" Vector__XXX
 SG_ DriveRecognize : 6|2@1+ (1,0) [0|3] "" Vector__XXX
 SG_ DriverCardDriver2 : 20|2@1+ (1,0) [0|3] "" Vector__XXX
 SG_ DriverCardDriver1 : 12|2@1+ (1,0) [0|3] "" Vector__XXX
 SG_ Driver2WorkingState : 3|3@1+ (1,0) [0|7] "" Vector__XXX
 SG_ Driver2TimeRelatedStates : 16|4@1+ (1,0) [0|15] "" Vector__XXX
 SG_ Driver1WorkingState : 0|3@1+ (1,0) [0|7] "" Vector__XXX
 SG_ Driver1TimeRelatedStates : 8|4@1+ (1,0) [0|15] "" Vector__XXX

BO_ 2566876209 VFC_EPIC4: 8 VFC
 SG_ SoundVolume : 56|8@1+ (1,0) [0|0] "" Vector__XXX
 SG_ SoundType : 48|8@1+ (1,0) [0|0] "" Vector__XXX
 SG_ DigitalOut19 : 46|1@1+ (1,0) [0|0] "" Vector__XXX
 SG_ DigitalOut18 : 45|1@1+ (1,0) [0|0] "" Vector__XXX
 SG_ DigitalOut17 : 44|1@1+ (1,0) [0|0] "" Vector__XXX
 SG_ DigitalOut16 : 43|1@1+ (1,0) [0|0] "" Vector__XXX
 SG_ DigitalOut15 : 42|1@1+ (1,0) [0|0] "" Vector__XXX
 SG_ DigitalOut14 : 41|1@1+ (1,0) [0|0] "" Vector__XXX
 SG_ DigitalOut13 : 40|1@1+ (1,0) [0|0] "" Vector__XXX
 SG_ DigitalOut12 : 39|1@1+ (1,0) [0|0] "" Vector__XXX
 SG_ DigitalOut11 : 38|1@1+ (1,0) [0|0] "" Vector__XXX
 SG_ DigitalOut10 : 37|1@1+ (1,0) [0|0] "" Vector__XXX
 SG_ DigitalOut09 : 36|1@1+ (1,0) [0|0] "" Vector__XXX
 SG_ DigitalOut08 : 35|1@1+ (1,0) [0|0] "" Vector__XXX
 SG_ DigitalOut07 : 34|1@1+ (1,0) [0|0] "" Vector__XXX
 SG_ DigitalOut06 : 33|1@1+ (1,0) [0|0] "" Vector__XXX
 SG_ DigitalOut05 : 32|1@1+ (1,0) [0|0] "" Vector__XXX
 SG_ DoorStatus4 : 24|8@1+ (1,0) [0|0] "" Vector__XXX
 SG_ DoorStatus3 : 16|8@1+ (1,0) [0|0] "" Vector__XXX
 SG_ DoorStatus2 : 8|8@1+ (1,0) [0|0] "" Vector__XXX
 SG_ DoorStatus1 : 0|8@1+ (1,0) [0|0] "" Vector__XXX

BO_ 2566875927 EDI2: 8 EPIC
 SG_ InStatus60 : 58|2@1+ (1,0) [0|0] "" Vector__XXX
 SG_ InStatus59 : 56|2@1+ (1,0) [0|0] "" Vector__XXX
 SG_ InStatus58 : 54|2@1+ (1,0) [0|0] "" Vector__XXX
 SG_ InStatus57 : 52|2@1+ (1,0) [0|0] "" Vector__XXX
 SG_ InStatus56 : 50|2@1+ (1,0) [0|0] "" Vector__XXX
 SG_ InStatus55 : 48|2@1+ (1,0) [0|0] "" Vector__XXX
 SG_ InStatus54 : 46|2@1+ (1,0) [0|0] "" Vector__XXX
 SG_ InStatus53 : 44|2@1+ (1,0) [0|0] "" Vector__XXX
 SG_ InStatus52 : 42|2@1+ (1,0) [0|0] "" Vector__XXX
 SG_ InStatus51 : 40|2@1+ (1,0) [0|0] "" Vector__XXX
 SG_ InStatus50 : 38|2@1+ (1,0) [0|0] "" Vector__XXX
 SG_ InStatus49 : 36|2@1+ (1,0) [0|0] "" Vector__XXX
 SG_ InStatus48 : 34|2@1+ (1,0) [0|0] "" Vector__XXX
 SG_ InStatus47 : 32|2@1+ (1,0) [0|0] "" Vector__XXX
 SG_ InStatus46 : 30|2@1+ (1,0) [0|0] "" Vector__XXX
 SG_ InStatus45 : 28|2@1+ (1,0) [0|0] "" Vector__XXX
 SG_ InStatus44 : 26|2@1+ (1,0) [0|0] "" Vector__XXX
 SG_ InStatus43 : 24|2@1+ (1,0) [0|0] "" Vector__XXX
 SG_ InStatus42 : 22|2@1+ (1,0) [0|0] "" Vector__XXX
 SG_ InStatus41 : 20|2@1+ (1,0) [0|0] "" Vector__XXX
 SG_ InStatus40 : 18|2@1+ (1,0) [0|0] "" Vector__XXX
 SG_ InStatus39 : 16|2@1+ (1,0) [0|0] "" Vector__XXX
 SG_ InStatus38 : 14|2@1+ (1,0) [0|0] "" Vector__XXX
 SG_ InStatus37 : 12|2@1+ (1,0) [0|0] "" Vector__XXX
 SG_ InStatus36 : 10|2@1+ (1,0) [0|0] "" Vector__XXX
 SG_ InStatus35 : 8|2@1+ (1,0) [0|0] "" Vector__XXX
 SG_ InStatus34 : 6|2@1+ (1,0) [0|0] "" Vector__XXX
 SG_ InStatus33 : 4|2@1+ (1,0) [0|0] "" Vector__XXX
 SG_ InStatus32 : 2|2@1+ (1,0) [0|0] "" Vector__XXX
 SG_ InStatus31 : 0|2@1+ (1,0) [0|0] "" Vector__XXX

BO_ 2566875671 EDI1: 8 EPIC
 SG_ InStatus30 : 58|2@1+ (1,0) [0|0] "" Vector__XXX
 SG_ InStatus29 : 56|2@1+ (1,0) [0|0] "" Vector__XXX
 SG_ InStatus28 : 54|2@1+ (1,0) [0|0] "" Vector__XXX
 SG_ InStatus27 : 52|2@1+ (1,0) [0|0] "" Vector__XXX
 SG_ InStatus26 : 50|2@1+ (1,0) [0|0] "" Vector__XXX
 SG_ InStatus25 : 48|2@1+ (1,0) [0|0] "" Vector__XXX
 SG_ InStatus24 : 46|2@1+ (1,0) [0|0] "" Vector__XXX
 SG_ InStatus23 : 44|2@1+ (1,0) [0|0] "" Vector__XXX
 SG_ InStatus22 : 42|2@1+ (1,0) [0|0] "" Vector__XXX
 SG_ InStatus21 : 40|2@1+ (1,0) [0|0] "" Vector__XXX
 SG_ InStatus20 : 38|2@1+ (1,0) [0|0] "" Vector__XXX
 SG_ InStatus19 : 36|2@1+ (1,0) [0|0] "" Vector__XXX
 SG_ InStatus18 : 34|2@1+ (1,0) [0|0] "" Vector__XXX
 SG_ InStatus17 : 32|2@1+ (1,0) [0|0] "" Vector__XXX
 SG_ InStatus16 : 30|2@1+ (1,0) [0|0] "" Vector__XXX
 SG_ InStatus15 : 28|2@1+ (1,0) [0|0] "" Vector__XXX
 SG_ InStatus14 : 26|2@1+ (1,0) [0|0] "" Vector__XXX
 SG_ InStatus13 : 24|2@1+ (1,0) [0|0] "" Vector__XXX
 SG_ InStatus12 : 22|2@1+ (1,0) [0|0] "" Vector__XXX
 SG_ InStatus11 : 20|2@1+ (1,0) [0|0] "" Vector__XXX
 SG_ InStatus10 : 18|2@1+ (1,0) [0|0] "" Vector__XXX
 SG_ InStatus09 : 16|2@1+ (1,0) [0|0] "" Vector__XXX
 SG_ InStatus08 : 14|2@1+ (1,0) [0|0] "" Vector__XXX
 SG_ InStatus07 : 12|2@1+ (1,0) [0|0] "" Vector__XXX
 SG_ InStatus06 : 10|2@1+ (1,0) [0|0] "" Vector__XXX
 SG_ InStatus05 : 8|2@1+ (1,0) [0|0] "" Vector__XXX
 SG_ InStatus04 : 6|2@1+ (1,0) [0|0] "" Vector__XXX
 SG_ InStatus03 : 4|2@1+ (1,0) [0|0] "" Vector__XXX
 SG_ InStatus02 : 2|2@1+ (1,0) [0|0] "" Vector__XXX
 SG_ InStatus01 : 0|2@1+ (1,0) [0|0] "" Vector__XXX

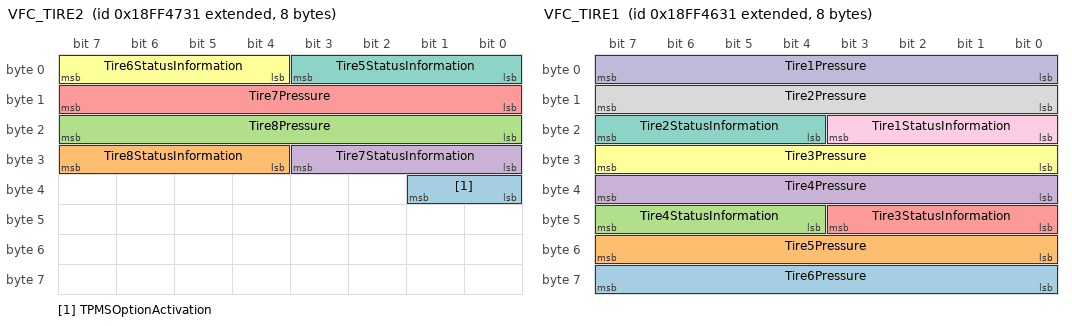
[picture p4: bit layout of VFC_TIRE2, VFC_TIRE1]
BO_ 2566866737 VFC_TIRE2: 8 VFC
 SG_ TPMSOptionActivation : 32|2@1+ (1,0) [0|0] "" Vector__XXX
 SG_ Tire8StatusInformation : 28|4@1+ (1,0) [0|15] "" Vector__XXX
 SG_ Tire8Pressure : 16|8@1+ (1,0) [0|2040] "dbar" Vector__XXX
 SG_ Tire7StatusInformation : 24|4@1+ (1,0) [0|15] "" Vector__XXX
 SG_ Tire7Pressure : 8|8@1+ (1,0) [0|2040] "dbar" Vector__XXX
 SG_ Tire6StatusInformation : 4|4@1+ (1,0) [0|15] "" Vector__XXX
 SG_ Tire5StatusInformation : 0|4@1+ (1,0) [0|15] "" Vector__XXX

BO_ 2566866481 VFC_TIRE1: 8 VFC
 SG_ Tire6Pressure : 56|8@1+ (1,0) [0|2040] "dbar" Vector__XXX
 SG_ Tire5Pressure : 48|8@1+ (1,0) [0|2040] "dbar" Vector__XXX
 SG_ Tire4StatusInformation : 44|4@1+ (1,0) [0|15] "" Vector__XXX
 SG_ Tire4Pressure : 32|8@1+ (1,0) [0|2040] "dbar" Vector__XXX
 SG_ Tire3StatusInformation : 40|4@1+ (1,0) [0|15] "" Vector__XXX
 SG_ Tire3Pressure : 24|8@1+ (1,0) [0|2040] "dbar" Vector__XXX
 SG_ Tire2StatusInformation : 20|4@1+ (1,0) [0|15] "" Vector__XXX
 SG_ Tire2Pressure : 8|8@1+ (1,0) [0|2040] "dbar" Vector__XXX
 SG_ Tire1StatusInformation : 16|4@1+ (1,0) [0|15] "" Vector__XXX
 SG_ Tire1Pressure : 0|8@1+ (1,0) [0|2040] "dbar" Vector__XXX

CM_ BO_ 2566834735 "Active diagnostic trouble codes";
CM_ SG_ 2566834735 FailureModeIdentifier5 "The FMI defines the type of failure detected in the subsystem identified by an SPN.";
CM_ SG_ 2566834735 FailureModeIdentifier4 "The FMI defines the type of failure detected in the subsystem identified by an SPN.";
CM_ SG_ 2566834735 FailureModeIdentifier3 "The FMI defines the type of failure detected in the subsystem identified by an SPN.";
CM_ SG_ 2566834735 FailureModeIdentifier2 "The FMI defines the type of failure detected in the subsystem identified by an SPN.";
CM_ SG_ 2566834735 OccurenceCount5 "The 7 bit occurence count field contains the number of times a fault has gone from active to previously active.";
CM_ SG_ 2566834735 OccurenceCount4 "The 7 bit occurence count field contains the number of times a fault has gone from active to previously active.";
CM_ SG_ 2566834735 OccurenceCount3 "The 7 bit occurence count field contains the number of times a fault has gone from active to previously active.";
CM_ SG_ 2566834735 OccurenceCount2 "The 7 bit occurence count field contains the number of times a fault has gone from active to previously active.";
CM_ SG_ 2566834735 SPN5High "SPN #5 (Conversion Version 4)";
CM_ SG_ 2566834735 SPN5 "SPN #5 (Conversion Version 4)";
CM_ SG_ 2566834735 SPN4High "SPN #4 (Conversion Version 4)";
CM_ SG_ 2566834735 SPN4 "SPN #4 (Conversion Version 4)";
CM_ SG_ 2566834735 SPN3High "SPN #3 (Conversion Version 4)";
CM_ SG_ 2566834735 SPN3 "SPN #3 (Conversion Version 4)";
CM_ SG_ 2566834735 SPN2High "SPN #2 (Conversion Version 4)";
CM_ SG_ 2566834735 SPN2 "SPN #2 (Conversion Version 4)";
CM_ SG_ 2566834735 SPN1 "SPN #1 (Conversion Version 4)";
CM_ SG_ 2566834735 OccurenceCount1 "The 7 bit occurence count field contains the number of times a fault has gone from active to previously active.";
CM_ SG_ 2566834735 SPN1High "SPN #1 (Conversion Version 4)";
CM_ SG_ 2566834735 FailureModeIdentifier1 "The FMI defines the type of failure detected in the subsystem identified by an SPN.";
CM_ SG_ 2566834735 FlashMalfuncIndicatorLamp "This parameter provides the capability to flash the MIL (SPN 3038).";
CM_ SG_ 2566834735 FlashRedStopLamp "This parameter provides the capability to flash the RSL (SPN 3039).";
CM_ SG_ 2566834735 FlashAmberWarningLamp "This parameter provides the capability to flash the AWL (SPN 3040). ";
CM_ SG_ 2566834735 FlashProtectLamp "This parameter provides the capability to flash the engine protect lamp (SPN 3041).";
CM_ SG_ 2566834735 MalfunctionIndicatorLampStatus "A lamp used to relay only emissions-related trouble code information.";
CM_ SG_ 2566834735 RedStopLampState "This lamp is uesed to relay trouble code information that is of a severe enought condition that it warrants stopping the vehicle.";
CM_ SG_ 2566834735 AmberWarningLampStatus "This lamp is used to relay trouble code information that is reporting a problem with the vehicle system but the vehicle need
not be immediately stopped.";
CM_ SG_ 2566834735 ProtectLampStatus "This lamp is used to relay trouble code informatio that is reporting a problem with a vehicle system that is most
probably not electronic subsystem related.";
CM_ BO_ 2566834699 "Active diagnostic trouble codes";
CM_ SG_ 2566834699 FailureModeIdentifier5 "The FMI defines the type of failure detected in the subsystem identified by an SPN.";
CM_ SG_ 2566834699 FailureModeIdentifier4 "The FMI defines the type of failure detected in the subsystem identified by an SPN.";
CM_ SG_ 2566834699 FailureModeIdentifier3 "The FMI defines the type of failure detected in the subsystem identified by an SPN.";
CM_ SG_ 2566834699 FailureModeIdentifier2 "The FMI defines the type of failure detected in the subsystem identified by an SPN.";
CM_ SG_ 2566834699 OccurenceCount5 "The 7 bit occurence count field contains the number of times a fault has gone from active to previously active.";
CM_ SG_ 2566834699 OccurenceCount4 "The 7 bit occurence count field contains the number of times a fault has gone from active to previously active.";
CM_ SG_ 2566834699 OccurenceCount3 "The 7 bit occurence count field contains the number of times a fault has gone from active to previously active.";
CM_ SG_ 2566834699 OccurenceCount2 "The 7 bit occurence count field contains the number of times a fault has gone from active to previously active.";
CM_ SG_ 2566834699 SPN5High "SPN #5 (Conversion Version 4)";
CM_ SG_ 2566834699 SPN5 "SPN #5 (Conversion Version 4)";
CM_ SG_ 2566834699 SPN4High "SPN #4 (Conversion Version 4)";
CM_ SG_ 2566834699 SPN4 "SPN #4 (Conversion Version 4)";
CM_ SG_ 2566834699 SPN3High "SPN #3 (Conversion Version 4)";
CM_ SG_ 2566834699 SPN3 "SPN #3 (Conversion Version 4)";
CM_ SG_ 2566834699 SPN2High "SPN #2 (Conversion Version 4)";
CM_ SG_ 2566834699 SPN2 "SPN #2 (Conversion Version 4)";
CM_ SG_ 2566834699 SPN1 "SPN #1 (Conversion Version 4)";
CM_ SG_ 2566834699 OccurenceCount1 "The 7 bit occurence count field contains the number of times a fault has gone from active to previously active.";
CM_ SG_ 2566834699 SPN1High "SPN #1 (Conversion Version 4)";
CM_ SG_ 2566834699 FailureModeIdentifier1 "The FMI defines the type of failure detected in the subsystem identified by an SPN.";
CM_ SG_ 2566834699 FlashMalfuncIndicatorLamp "This parameter provides the capability to flash the MIL (SPN 3038).";
CM_ SG_ 2566834699 FlashRedStopLamp "This parameter provides the capability to flash the RSL (SPN 3039).";
CM_ SG_ 2566834699 FlashAmberWarningLamp "This parameter provides the capability to flash the AWL (SPN 3040). ";
CM_ SG_ 2566834699 FlashProtectLamp "This parameter provides the capability to flash the engine protect lamp (SPN 3041).";
CM_ SG_ 2566834699 MalfunctionIndicatorLampStatus "A lamp used to relay only emissions-related trouble code information.";
CM_ SG_ 2566834699 RedStopLampState "This lamp is uesed to relay trouble code information that is of a severe enought condition that it warrants stopping the vehicle.";
CM_ SG_ 2566834699 AmberWarningLampStatus "This lamp is used to relay trouble code information that is reporting a problem with the vehicle system but the vehicle need
not be immediately stopped.";
CM_ SG_ 2566834699 ProtectLampStatus "This lamp is used to relay trouble code informatio that is reporting a problem with a vehicle system that is most
probably not electronic subsystem related.";
CM_ BO_ 2566834816 "Active diagnostic trouble codes";
CM_ SG_ 2566834816 FailureModeIdentifier5 "The FMI defines the type of failure detected in the subsystem identified by an SPN.";
CM_ SG_ 2566834816 FailureModeIdentifier4 "The FMI defines the type of failure detected in the subsystem identified by an SPN.";
CM_ SG_ 2566834816 FailureModeIdentifier3 "The FMI defines the type of failure detected in the subsystem identified by an SPN.";
CM_ SG_ 2566834816 FailureModeIdentifier2 "The FMI defines the type of failure detected in the subsystem identified by an SPN.";
CM_ SG_ 2566834816 OccurenceCount5 "The 7 bit occurence count field contains the number of times a fault has gone from active to previously active.";
CM_ SG_ 2566834816 OccurenceCount4 "The 7 bit occurence count field contains the number of times a fault has gone from active to previously active.";
CM_ SG_ 2566834816 OccurenceCount3 "The 7 bit occurence count field contains the number of times a fault has gone from active to previously active.";
CM_ SG_ 2566834816 OccurenceCount2 "The 7 bit occurence count field contains the number of times a fault has gone from active to previously active.";
CM_ SG_ 2566834816 SPN5High "SPN #5 (Conversion Version 4)";
CM_ SG_ 2566834816 SPN5 "SPN #5 (Conversion Version 4)";
CM_ SG_ 2566834816 SPN4High "SPN #4 (Conversion Version 4)";
CM_ SG_ 2566834816 SPN4 "SPN #4 (Conversion Version 4)";
CM_ SG_ 2566834816 SPN3High "SPN #3 (Conversion Version 4)";
CM_ SG_ 2566834816 SPN3 "SPN #3 (Conversion Version 4)";
CM_ SG_ 2566834816 SPN2High "SPN #2 (Conversion Version 4)";
CM_ SG_ 2566834816 SPN2 "SPN #2 (Conversion Version 4)";
CM_ SG_ 2566834816 SPN1 "SPN #1 (Conversion Version 4)";
CM_ SG_ 2566834816 OccurenceCount1 "The 7 bit occurence count field contains the number of times a fault has gone from active to previously active.";
CM_ SG_ 2566834816 SPN1High "SPN #1 (Conversion Version 4)";
CM_ SG_ 2566834816 FailureModeIdentifier1 "The FMI defines the type of failure detected in the subsystem identified by an SPN.";
CM_ SG_ 2566834816 FlashMalfuncIndicatorLamp "This parameter provides the capability to flash the MIL (SPN 3038).";
CM_ SG_ 2566834816 FlashRedStopLamp "This parameter provides the capability to flash the RSL (SPN 3039).";
CM_ SG_ 2566834816 FlashAmberWarningLamp "This parameter provides the capability to flash the AWL (SPN 3040). ";
CM_ SG_ 2566834816 FlashProtectLamp "This parameter provides the capability to flash the engine protect lamp (SPN 3041).";
CM_ SG_ 2566834816 MalfunctionIndicatorLampStatus "A lamp used to relay only emissions-related trouble code information.";
CM_ SG_ 2566834816 RedStopLampState "This lamp is uesed to relay trouble code information that is of a severe enought condition that it warrants stopping the vehicle.";
CM_ SG_ 2566834816 AmberWarningLampStatus "This lamp is used to relay trouble code information that is reporting a problem with the vehicle system but the vehicle need
not be immediately stopped.";
CM_ SG_ 2566834816 ProtectLampStatus "This lamp is used to relay trouble code informatio that is reporting a problem with a vehicle system that is most
probably not electronic subsystem related.";
CM_ BO_ 2566834688 "Active diagnostic trouble codes";
CM_ SG_ 2566834688 FailureModeIdentifier5 "The FMI defines the type of failure detected in the subsystem identified by an SPN.";
CM_ SG_ 2566834688 FailureModeIdentifier4 "The FMI defines the type of failure detected in the subsystem identified by an SPN.";
CM_ SG_ 2566834688 FailureModeIdentifier3 "The FMI defines the type of failure detected in the subsystem identified by an SPN.";
CM_ SG_ 2566834688 FailureModeIdentifier2 "The FMI defines the type of failure detected in the subsystem identified by an SPN.";
CM_ SG_ 2566834688 OccurenceCount5 "The 7 bit occurence count field contains the number of times a fault has gone from active to previously active.";
CM_ SG_ 2566834688 OccurenceCount4 "The 7 bit occurence count field contains the number of times a fault has gone from active to previously active.";
CM_ SG_ 2566834688 OccurenceCount3 "The 7 bit occurence count field contains the number of times a fault has gone from active to previously active.";
CM_ SG_ 2566834688 OccurenceCount2 "The 7 bit occurence count field contains the number of times a fault has gone from active to previously active.";
CM_ SG_ 2566834688 SPN5High "SPN #5 (Conversion Version 4)";
CM_ SG_ 2566834688 SPN5 "SPN #5 (Conversion Version 4)";
CM_ SG_ 2566834688 SPN4High "SPN #4 (Conversion Version 4)";
CM_ SG_ 2566834688 SPN4 "SPN #4 (Conversion Version 4)";
CM_ SG_ 2566834688 SPN3High "SPN #3 (Conversion Version 4)";
CM_ SG_ 2566834688 SPN3 "SPN #3 (Conversion Version 4)";
CM_ SG_ 2566834688 SPN2High "SPN #2 (Conversion Version 4)";
CM_ SG_ 2566834688 SPN2 "SPN #2 (Conversion Version 4)";
CM_ SG_ 2566834688 SPN1 "SPN #1 (Conversion Version 4)";
CM_ SG_ 2566834688 OccurenceCount1 "The 7 bit occurence count field contains the number of times a fault has gone from active to previously active.";
CM_ SG_ 2566834688 SPN1High "SPN #1 (Conversion Version 4)";
CM_ SG_ 2566834688 FailureModeIdentifier1 "The FMI defines the type of failure detected in the subsystem identified by an SPN.";
CM_ SG_ 2566834688 FlashMalfuncIndicatorLamp "This parameter provides the capability to flash the MIL (SPN 3038).";
CM_ SG_ 2566834688 FlashRedStopLamp "This parameter provides the capability to flash the RSL (SPN 3039).";
CM_ SG_ 2566834688 FlashAmberWarningLamp "This parameter provides the capability to flash the AWL (SPN 3040). ";
CM_ SG_ 2566834688 FlashProtectLamp "This parameter provides the capability to flash the engine protect lamp (SPN 3041).";
CM_ SG_ 2566834688 MalfunctionIndicatorLampStatus "A lamp used to relay only emissions-related trouble code information.";
CM_ SG_ 2566834688 RedStopLampState "This lamp is uesed to relay trouble code information that is of a severe enought condition that it warrants stopping the vehicle.";
CM_ SG_ 2566834688 AmberWarningLampStatus "This lamp is used to relay trouble code information that is reporting a problem with the vehicle system but the vehicle need
not be immediately stopped.";
CM_ SG_ 2566834688 ProtectLampStatus "This lamp is used to relay trouble code informatio that is reporting a problem with a vehicle system that is most
probably not electronic subsystem related.";
CM_ BO_ 2566834927 "Active diagnostic trouble codes";
CM_ SG_ 2566834927 FailureModeIdentifier5 "The FMI defines the type of failure detected in the subsystem identified by an SPN.";
CM_ SG_ 2566834927 FailureModeIdentifier4 "The FMI defines the type of failure detected in the subsystem identified by an SPN.";
CM_ SG_ 2566834927 FailureModeIdentifier3 "The FMI defines the type of failure detected in the subsystem identified by an SPN.";
CM_ SG_ 2566834927 FailureModeIdentifier2 "The FMI defines the type of failure detected in the subsystem identified by an SPN.";
CM_ SG_ 2566834927 OccurenceCount5 "The 7 bit occurence count field contains the number of times a fault has gone from active to previously active.";
CM_ SG_ 2566834927 OccurenceCount4 "The 7 bit occurence count field contains the number of times a fault has gone from active to previously active.";
CM_ SG_ 2566834927 OccurenceCount3 "The 7 bit occurence count field contains the number of times a fault has gone from active to previously active.";
CM_ SG_ 2566834927 OccurenceCount2 "The 7 bit occurence count field contains the number of times a fault has gone from active to previously active.";
CM_ SG_ 2566834927 SPN5High "SPN #5 (Conversion Version 4)";
CM_ SG_ 2566834927 SPN5 "SPN #5 (Conversion Version 4)";
CM_ SG_ 2566834927 SPN4High "SPN #4 (Conversion Version 4)";
CM_ SG_ 2566834927 SPN4 "SPN #4 (Conversion Version 4)";
CM_ SG_ 2566834927 SPN3High "SPN #3 (Conversion Version 4)";
CM_ SG_ 2566834927 SPN3 "SPN #3 (Conversion Version 4)";
CM_ SG_ 2566834927 SPN2High "SPN #2 (Conversion Version 4)";
CM_ SG_ 2566834927 SPN2 "SPN #2 (Conversion Version 4)";
CM_ SG_ 2566834927 SPN1 "SPN #1 (Conversion Version 4)";
CM_ SG_ 2566834927 OccurenceCount1 "The 7 bit occurence count field contains the number of times a fault has gone from active to previously active.";
CM_ SG_ 2566834927 SPN1High "SPN #1 (Conversion Version 4)";
CM_ SG_ 2566834927 FailureModeIdentifier1 "The FMI defines the type of failure detected in the subsystem identified by an SPN.";
CM_ SG_ 2566834927 FlashMalfuncIndicatorLamp "This parameter provides the capability to flash the MIL (SPN 3038).";
CM_ SG_ 2566834927 FlashRedStopLamp "This parameter provides the capability to flash the RSL (SPN 3039).";
CM_ SG_ 2566834927 FlashAmberWarningLamp "This parameter provides the capability to flash the AWL (SPN 3040). ";
CM_ SG_ 2566834927 FlashProtectLamp "This parameter provides the capability to flash the engine protect lamp (SPN 3041).";
CM_ SG_ 2566834927 MalfunctionIndicatorLampStatus "A lamp used to relay only emissions-related trouble code information.";
CM_ SG_ 2566834927 RedStopLampState "This lamp is uesed to relay trouble code information that is of a severe enought condition that it warrants stopping the vehicle.";
CM_ SG_ 2566834927 AmberWarningLampStatus "This lamp is used to relay trouble code information that is reporting a problem with the vehicle system but the vehicle need
not be immediately stopped.";
CM_ SG_ 2566834927 ProtectLampStatus "This lamp is used to relay trouble code informatio that is reporting a problem with a vehicle system that is most
probably not electronic subsystem related.";
CM_ BO_ 2566834737 "Active diagnostic trouble codes";
CM_ SG_ 2566834737 FailureModeIdentifier5 "The FMI defines the type of failure detected in the subsystem identified by an SPN.";
CM_ SG_ 2566834737 FailureModeIdentifier4 "The FMI defines the type of failure detected in the subsystem identified by an SPN.";
CM_ SG_ 2566834737 FailureModeIdentifier3 "The FMI defines the type of failure detected in the subsystem identified by an SPN.";
CM_ SG_ 2566834737 FailureModeIdentifier2 "The FMI defines the type of failure detected in the subsystem identified by an SPN.";
CM_ SG_ 2566834737 OccurenceCount5 "The 7 bit occurence count field contains the number of times a fault has gone from active to previously active.";
CM_ SG_ 2566834737 OccurenceCount4 "The 7 bit occurence count field contains the number of times a fault has gone from active to previously active.";
CM_ SG_ 2566834737 OccurenceCount3 "The 7 bit occurence count field contains the number of times a fault has gone from active to previously active.";
CM_ SG_ 2566834737 OccurenceCount2 "The 7 bit occurence count field contains the number of times a fault has gone from active to previously active.";
CM_ SG_ 2566834737 SPN5High "SPN #5 (Conversion Version 4)";
CM_ SG_ 2566834737 SPN5 "SPN #5 (Conversion Version 4)";
CM_ SG_ 2566834737 SPN4High "SPN #4 (Conversion Version 4)";
CM_ SG_ 2566834737 SPN4 "SPN #4 (Conversion Version 4)";
CM_ SG_ 2566834737 SPN3High "SPN #3 (Conversion Version 4)";
CM_ SG_ 2566834737 SPN3 "SPN #3 (Conversion Version 4)";
CM_ SG_ 2566834737 SPN2High "SPN #2 (Conversion Version 4)";
CM_ SG_ 2566834737 SPN2 "SPN #2 (Conversion Version 4)";
CM_ SG_ 2566834737 SPN1 "SPN #1 (Conversion Version 4)";
CM_ SG_ 2566834737 OccurenceCount1 "The 7 bit occurence count field contains the number of times a fault has gone from active to previously active.";
CM_ SG_ 2566834737 SPN1High "SPN #1 (Conversion Version 4)";
CM_ SG_ 2566834737 FailureModeIdentifier1 "The FMI defines the type of failure detected in the subsystem identified by an SPN.";
CM_ SG_ 2566834737 FlashMalfuncIndicatorLamp "This parameter provides the capability to flash the MIL (SPN 3038).";
CM_ SG_ 2566834737 FlashRedStopLamp "This parameter provides the capability to flash the RSL (SPN 3039).";
CM_ SG_ 2566834737 FlashAmberWarningLamp "This parameter provides the capability to flash the AWL (SPN 3040). ";
CM_ SG_ 2566834737 FlashProtectLamp "This parameter provides the capability to flash the engine protect lamp (SPN 3041).";
CM_ SG_ 2566834737 MalfunctionIndicatorLampStatus "A lamp used to relay only emissions-related trouble code information.";
CM_ SG_ 2566834737 RedStopLampState "This lamp is uesed to relay trouble code information that is of a severe enought condition that it warrants stopping the vehicle.";
CM_ SG_ 2566834737 AmberWarningLampStatus "This lamp is used to relay trouble code information that is reporting a problem with the vehicle system but the vehicle need
not be immediately stopped.";
CM_ SG_ 2566834737 ProtectLampStatus "This lamp is used to relay trouble code informatio that is reporting a problem with a vehicle system that is most
probably not electronic subsystem related.";
CM_ BO_ 2566834760 "Active diagnostic trouble codes";
CM_ SG_ 2566834760 FailureModeIdentifier5 "The FMI defines the type of failure detected in the subsystem identified by an SPN.";
CM_ SG_ 2566834760 FailureModeIdentifier4 "The FMI defines the type of failure detected in the subsystem identified by an SPN.";
CM_ SG_ 2566834760 FailureModeIdentifier3 "The FMI defines the type of failure detected in the subsystem identified by an SPN.";
CM_ SG_ 2566834760 FailureModeIdentifier2 "The FMI defines the type of failure detected in the subsystem identified by an SPN.";
CM_ SG_ 2566834760 OccurenceCount5 "The 7 bit occurence count field contains the number of times a fault has gone from active to previously active.";
CM_ SG_ 2566834760 OccurenceCount4 "The 7 bit occurence count field contains the number of times a fault has gone from active to previously active.";
CM_ SG_ 2566834760 OccurenceCount3 "The 7 bit occurence count field contains the number of times a fault has gone from active to previously active.";
CM_ SG_ 2566834760 OccurenceCount2 "The 7 bit occurence count field contains the number of times a fault has gone from active to previously active.";
CM_ SG_ 2566834760 SPN5High "SPN #5 (Conversion Version 4)";
CM_ SG_ 2566834760 SPN5 "SPN #5 (Conversion Version 4)";
CM_ SG_ 2566834760 SPN4High "SPN #4 (Conversion Version 4)";
CM_ SG_ 2566834760 SPN4 "SPN #4 (Conversion Version 4)";
CM_ SG_ 2566834760 SPN3High "SPN #3 (Conversion Version 4)";
CM_ SG_ 2566834760 SPN3 "SPN #3 (Conversion Version 4)";
CM_ SG_ 2566834760 SPN2High "SPN #2 (Conversion Version 4)";
CM_ SG_ 2566834760 SPN2 "SPN #2 (Conversion Version 4)";
CM_ SG_ 2566834760 SPN1 "SPN #1 (Conversion Version 4)";
CM_ SG_ 2566834760 OccurenceCount1 "The 7 bit occurence count field contains the number of times a fault has gone from active to previously active.";
CM_ SG_ 2566834760 SPN1High "SPN #1 (Conversion Version 4)";
CM_ SG_ 2566834760 FailureModeIdentifier1 "The FMI defines the type of failure detected in the subsystem identified by an SPN.";
CM_ SG_ 2566834760 FlashMalfuncIndicatorLamp "This parameter provides the capability to flash the MIL (SPN 3038).";
CM_ SG_ 2566834760 FlashRedStopLamp "This parameter provides the capability to flash the RSL (SPN 3039).";
CM_ SG_ 2566834760 FlashAmberWarningLamp "This parameter provides the capability to flash the AWL (SPN 3040). ";
CM_ SG_ 2566834760 FlashProtectLamp "This parameter provides the capability to flash the engine protect lamp (SPN 3041).";
CM_ SG_ 2566834760 MalfunctionIndicatorLampStatus "A lamp used to relay only emissions-related trouble code information.";
CM_ SG_ 2566834760 RedStopLampState "This lamp is uesed to relay trouble code information that is of a severe enought condition that it warrants stopping the vehicle.";
CM_ SG_ 2566834760 AmberWarningLampStatus "This lamp is used to relay trouble code information that is reporting a problem with the vehicle system but the vehicle need
not be immediately stopped.";
CM_ SG_ 2566834760 ProtectLampStatus "This lamp is used to relay trouble code informatio that is reporting a problem with a vehicle system that is most
probably not electronic subsystem related.";
CM_ BO_ 2566834727 "Active diagnostic trouble codes";
CM_ SG_ 2566834727 FailureModeIdentifier5 "The FMI defines the type of failure detected in the subsystem identified by an SPN.";
CM_ SG_ 2566834727 FailureModeIdentifier4 "The FMI defines the type of failure detected in the subsystem identified by an SPN.";
CM_ SG_ 2566834727 FailureModeIdentifier3 "The FMI defines the type of failure detected in the subsystem identified by an SPN.";
CM_ SG_ 2566834727 FailureModeIdentifier2 "The FMI defines the type of failure detected in the subsystem identified by an SPN.";
CM_ SG_ 2566834727 OccurenceCount5 "The 7 bit occurence count field contains the number of times a fault has gone from active to previously active.";
CM_ SG_ 2566834727 OccurenceCount4 "The 7 bit occurence count field contains the number of times a fault has gone from active to previously active.";
CM_ SG_ 2566834727 OccurenceCount3 "The 7 bit occurence count field contains the number of times a fault has gone from active to previously active.";
CM_ SG_ 2566834727 OccurenceCount2 "The 7 bit occurence count field contains the number of times a fault has gone from active to previously active.";
CM_ SG_ 2566834727 SPN5High "SPN #5 (Conversion Version 4)";
CM_ SG_ 2566834727 SPN5 "SPN #5 (Conversion Version 4)";
CM_ SG_ 2566834727 SPN4High "SPN #4 (Conversion Version 4)";
CM_ SG_ 2566834727 SPN4 "SPN #4 (Conversion Version 4)";
CM_ SG_ 2566834727 SPN3High "SPN #3 (Conversion Version 4)";
CM_ SG_ 2566834727 SPN3 "SPN #3 (Conversion Version 4)";
CM_ SG_ 2566834727 SPN2High "SPN #2 (Conversion Version 4)";
CM_ SG_ 2566834727 SPN2 "SPN #2 (Conversion Version 4)";
CM_ SG_ 2566834727 SPN1 "SPN #1 (Conversion Version 4)";
CM_ SG_ 2566834727 OccurenceCount1 "The 7 bit occurence count field contains the number of times a fault has gone from active to previously active.";
CM_ SG_ 2566834727 SPN1High "SPN #1 (Conversion Version 4)";
CM_ SG_ 2566834727 FailureModeIdentifier1 "The FMI defines the type of failure detected in the subsystem identified by an SPN.";
CM_ SG_ 2566834727 FlashMalfuncIndicatorLamp "This parameter provides the capability to flash the MIL (SPN 3038).";
CM_ SG_ 2566834727 FlashRedStopLamp "This parameter provides the capability to flash the RSL (SPN 3039).";
CM_ SG_ 2566834727 FlashAmberWarningLamp "This parameter provides the capability to flash the AWL (SPN 3040). ";
CM_ SG_ 2566834727 FlashProtectLamp "This parameter provides the capability to flash the engine protect lamp (SPN 3041).";
CM_ SG_ 2566834727 MalfunctionIndicatorLampStatus "A lamp used to relay only emissions-related trouble code information.";
CM_ SG_ 2566834727 RedStopLampState "This lamp is uesed to relay trouble code information that is of a severe enought condition that it warrants stopping the vehicle.";
CM_ SG_ 2566834727 AmberWarningLampStatus "This lamp is used to relay trouble code information that is reporting a problem with the vehicle system but the vehicle need
not be immediately stopped.";
CM_ SG_ 2566834727 ProtectLampStatus "This lamp is used to relay trouble code informatio that is reporting a problem with a vehicle system that is most
probably not electronic subsystem related.";
CM_ BO_ 2566834926 "Active diagnostic trouble codes";
CM_ SG_ 2566834926 FailureModeIdentifier5 "The FMI defines the type of failure detected in the subsystem identified by an SPN.";
CM_ SG_ 2566834926 FailureModeIdentifier4 "The FMI defines the type of failure detected in the subsystem identified by an SPN.";
CM_ SG_ 2566834926 FailureModeIdentifier3 "The FMI defines the type of failure detected in the subsystem identified by an SPN.";
CM_ SG_ 2566834926 FailureModeIdentifier2 "The FMI defines the type of failure detected in the subsystem identified by an SPN.";
CM_ SG_ 2566834926 OccurenceCount5 "The 7 bit occurence count field contains the number of times a fault has gone from active to previously active.";
CM_ SG_ 2566834926 OccurenceCount4 "The 7 bit occurence count field contains the number of times a fault has gone from active to previously active.";
CM_ SG_ 2566834926 OccurenceCount3 "The 7 bit occurence count field contains the number of times a fault has gone from active to previously active.";
CM_ SG_ 2566834926 OccurenceCount2 "The 7 bit occurence count field contains the number of times a fault has gone from active to previously active.";
CM_ SG_ 2566834926 SPN5High "SPN #5 (Conversion Version 4)";
CM_ SG_ 2566834926 SPN5 "SPN #5 (Conversion Version 4)";
CM_ SG_ 2566834926 SPN4High "SPN #4 (Conversion Version 4)";
CM_ SG_ 2566834926 SPN4 "SPN #4 (Conversion Version 4)";
CM_ SG_ 2566834926 SPN3High "SPN #3 (Conversion Version 4)";
CM_ SG_ 2566834926 SPN3 "SPN #3 (Conversion Version 4)";
CM_ SG_ 2566834926 SPN2High "SPN #2 (Conversion Version 4)";
CM_ SG_ 2566834926 SPN2 "SPN #2 (Conversion Version 4)";
CM_ SG_ 2566834926 SPN1 "SPN #1 (Conversion Version 4)";
CM_ SG_ 2566834926 OccurenceCount1 "The 7 bit occurence count field contains the number of times a fault has gone from active to previously active.";
CM_ SG_ 2566834926 SPN1High "SPN #1 (Conversion Version 4)";
CM_ SG_ 2566834926 FailureModeIdentifier1 "The FMI defines the type of failure detected in the subsystem identified by an SPN.";
CM_ SG_ 2566834926 FlashMalfuncIndicatorLamp "This parameter provides the capability to flash the MIL (SPN 3038).";
CM_ SG_ 2566834926 FlashRedStopLamp "This parameter provides the capability to flash the RSL (SPN 3039).";
CM_ SG_ 2566834926 FlashAmberWarningLamp "This parameter provides the capability to flash the AWL (SPN 3040). ";
CM_ SG_ 2566834926 FlashProtectLamp "This parameter provides the capability to flash the engine protect lamp (SPN 3041).";
CM_ SG_ 2566834926 MalfunctionIndicatorLampStatus "A lamp used to relay only emissions-related trouble code information.";
CM_ SG_ 2566834926 RedStopLampState "This lamp is uesed to relay trouble code information that is of a severe enought condition that it warrants stopping the vehicle.";
CM_ SG_ 2566834926 AmberWarningLampStatus "This lamp is used to relay trouble code information that is reporting a problem with the vehicle system but the vehicle need
not be immediately stopped.";
CM_ SG_ 2566834926 ProtectLampStatus "This lamp is used to relay trouble code informatio that is reporting a problem with a vehicle system that is most
probably not electronic subsystem related.";
CM_ BO_ 2566834768 "Active diagnostic trouble codes";
CM_ SG_ 2566834768 FailureModeIdentifier5 "The FMI defines the type of failure detected in the subsystem identified by an SPN.";
CM_ SG_ 2566834768 FailureModeIdentifier4 "The FMI defines the type of failure detected in the subsystem identified by an SPN.";
CM_ SG_ 2566834768 FailureModeIdentifier3 "The FMI defines the type of failure detected in the subsystem identified by an SPN.";
CM_ SG_ 2566834768 FailureModeIdentifier2 "The FMI defines the type of failure detected in the subsystem identified by an SPN.";
CM_ SG_ 2566834768 OccurenceCount5 "The 7 bit occurence count field contains the number of times a fault has gone from active to previously active.";
CM_ SG_ 2566834768 OccurenceCount4 "The 7 bit occurence count field contains the number of times a fault has gone from active to previously active.";
CM_ SG_ 2566834768 OccurenceCount3 "The 7 bit occurence count field contains the number of times a fault has gone from active to previously active.";
CM_ SG_ 2566834768 OccurenceCount2 "The 7 bit occurence count field contains the number of times a fault has gone from active to previously active.";
CM_ SG_ 2566834768 SPN5High "SPN #5 (Conversion Version 4)";
CM_ SG_ 2566834768 SPN5 "SPN #5 (Conversion Version 4)";
CM_ SG_ 2566834768 SPN4High "SPN #4 (Conversion Version 4)";
CM_ SG_ 2566834768 SPN4 "SPN #4 (Conversion Version 4)";
CM_ SG_ 2566834768 SPN3High "SPN #3 (Conversion Version 4)";
CM_ SG_ 2566834768 SPN3 "SPN #3 (Conversion Version 4)";
CM_ SG_ 2566834768 SPN2High "SPN #2 (Conversion Version 4)";
CM_ SG_ 2566834768 SPN2 "SPN #2 (Conversion Version 4)";
CM_ SG_ 2566834768 SPN1 "SPN #1 (Conversion Version 4)";
CM_ SG_ 2566834768 OccurenceCount1 "The 7 bit occurence count field contains the number of times a fault has gone from active to previously active.";
CM_ SG_ 2566834768 SPN1High "SPN #1 (Conversion Version 4)";
CM_ SG_ 2566834768 FailureModeIdentifier1 "The FMI defines the type of failure detected in the subsystem identified by an SPN.";
CM_ SG_ 2566834768 FlashMalfuncIndicatorLamp "This parameter provides the capability to flash the MIL (SPN 3038).";
CM_ SG_ 2566834768 FlashRedStopLamp "This parameter provides the capability to flash the RSL (SPN 3039).";
CM_ SG_ 2566834768 FlashAmberWarningLamp "This parameter provides the capability to flash the AWL (SPN 3040). ";
CM_ SG_ 2566834768 FlashProtectLamp "This parameter provides the capability to flash the engine protect lamp (SPN 3041).";
CM_ SG_ 2566834768 MalfunctionIndicatorLampStatus "A lamp used to relay only emissions-related trouble code information.";
CM_ SG_ 2566834768 RedStopLampState "This lamp is uesed to relay trouble code information that is of a severe enought condition that it warrants stopping the vehicle.";
CM_ SG_ 2566834768 AmberWarningLampStatus "This lamp is used to relay trouble code information that is reporting a problem with the vehicle system but the vehicle need
not be immediately stopped.";
CM_ SG_ 2566834768 ProtectLampStatus "This lamp is used to relay trouble code informatio that is reporting a problem with a vehicle system that is most
probably not electronic subsystem related.";
CM_ BO_ 2566834931 "Active diagnostic trouble codes";
CM_ SG_ 2566834931 FailureModeIdentifier5 "The FMI defines the type of failure detected in the subsystem identified by an SPN.";
CM_ SG_ 2566834931 FailureModeIdentifier4 "The FMI defines the type of failure detected in the subsystem identified by an SPN.";
CM_ SG_ 2566834931 FailureModeIdentifier3 "The FMI defines the type of failure detected in the subsystem identified by an SPN.";
CM_ SG_ 2566834931 FailureModeIdentifier2 "The FMI defines the type of failure detected in the subsystem identified by an SPN.";
CM_ SG_ 2566834931 OccurenceCount5 "The 7 bit occurence count field contains the number of times a fault has gone from active to previously active.";
CM_ SG_ 2566834931 OccurenceCount4 "The 7 bit occurence count field contains the number of times a fault has gone from active to previously active.";
CM_ SG_ 2566834931 OccurenceCount3 "The 7 bit occurence count field contains the number of times a fault has gone from active to previously active.";
CM_ SG_ 2566834931 OccurenceCount2 "The 7 bit occurence count field contains the number of times a fault has gone from active to previously active.";
CM_ SG_ 2566834931 SPN5High "SPN #5 (Conversion Version 4)";
CM_ SG_ 2566834931 SPN5 "SPN #5 (Conversion Version 4)";
CM_ SG_ 2566834931 SPN4High "SPN #4 (Conversion Version 4)";
CM_ SG_ 2566834931 SPN4 "SPN #4 (Conversion Version 4)";
CM_ SG_ 2566834931 SPN3High "SPN #3 (Conversion Version 4)";
CM_ SG_ 2566834931 SPN3 "SPN #3 (Conversion Version 4)";
CM_ SG_ 2566834931 SPN2High "SPN #2 (Conversion Version 4)";
CM_ SG_ 2566834931 SPN2 "SPN #2 (Conversion Version 4)";
CM_ SG_ 2566834931 SPN1 "SPN #1 (Conversion Version 4)";
CM_ SG_ 2566834931 OccurenceCount1 "The 7 bit occurence count field contains the number of times a fault has gone from active to previously active.";
CM_ SG_ 2566834931 SPN1High "SPN #1 (Conversion Version 4)";
CM_ SG_ 2566834931 FailureModeIdentifier1 "The FMI defines the type of failure detected in the subsystem identified by an SPN.";
CM_ SG_ 2566834931 FlashMalfuncIndicatorLamp "This parameter provides the capability to flash the MIL (SPN 3038).";
CM_ SG_ 2566834931 FlashRedStopLamp "This parameter provides the capability to flash the RSL (SPN 3039).";
CM_ SG_ 2566834931 FlashAmberWarningLamp "This parameter provides the capability to flash the AWL (SPN 3040). ";
CM_ SG_ 2566834931 FlashProtectLamp "This parameter provides the capability to flash the engine protect lamp (SPN 3041).";
CM_ SG_ 2566834931 MalfunctionIndicatorLampStatus "A lamp used to relay only emissions-related trouble code information.";
CM_ SG_ 2566834931 RedStopLampState "This lamp is uesed to relay trouble code information that is of a severe enought condition that it warrants stopping the vehicle.";
CM_ SG_ 2566834931 AmberWarningLampStatus "This lamp is used to relay trouble code information that is reporting a problem with the vehicle system but the vehicle need
not be immediately stopped.";
CM_ SG_ 2566834931 ProtectLampStatus "This lamp is used to relay trouble code informatio that is reporting a problem with a vehicle system that is most
probably not electronic subsystem related.";
CM_ SG_ 2364539904 EngSpeed "Actual engine speed which is calculated over a minimum crankshaft angle of 720 degrees divided by the number of cylinders.";
CM_ SG_ 2566803211 VDCFullyOperational "Signal that indicates whether VDC is fully operational or whether its functionality is reduced by a permanent or temporary (e.";
CM_ SG_ 2566804992 CatalystTankLevel "A special catalyst uses chemical substance to reach legal requirement for NOX emissions.";
CM_ BO_ 2566834942 "Active diagnostic trouble codes";
CM_ SG_ 2566834942 FailureModeIdentifier5 "The FMI defines the type of failure detected in the subsystem identified by an SPN.";
CM_ SG_ 2566834942 FailureModeIdentifier4 "The FMI defines the type of failure detected in the subsystem identified by an SPN.";
CM_ SG_ 2566834942 FailureModeIdentifier3 "The FMI defines the type of failure detected in the subsystem identified by an SPN.";
CM_ SG_ 2566834942 FailureModeIdentifier2 "The FMI defines the type of failure detected in the subsystem identified by an SPN.";
CM_ SG_ 2566834942 OccurenceCount5 "The 7 bit occurence count field contains the number of times a fault has gone from active to previously active.";
CM_ SG_ 2566834942 OccurenceCount4 "The 7 bit occurence count field contains the number of times a fault has gone from active to previously active.";
CM_ SG_ 2566834942 OccurenceCount3 "The 7 bit occurence count field contains the number of times a fault has gone from active to previously active.";
CM_ SG_ 2566834942 OccurenceCount2 "The 7 bit occurence count field contains the number of times a fault has gone from active to previously active.";
CM_ SG_ 2566834942 SPN5High "SPN #5 (Conversion Version 4)";
CM_ SG_ 2566834942 SPN5 "SPN #5 (Conversion Version 4)";
CM_ SG_ 2566834942 SPN4High "SPN #4 (Conversion Version 4)";
CM_ SG_ 2566834942 SPN4 "SPN #4 (Conversion Version 4)";
CM_ SG_ 2566834942 SPN3High "SPN #3 (Conversion Version 4)";
CM_ SG_ 2566834942 SPN3 "SPN #3 (Conversion Version 4)";
CM_ SG_ 2566834942 SPN2High "SPN #2 (Conversion Version 4)";
CM_ SG_ 2566834942 SPN2 "SPN #2 (Conversion Version 4)";
CM_ SG_ 2566834942 SPN1 "SPN #1 (Conversion Version 4)";
CM_ SG_ 2566834942 OccurenceCount1 "The 7 bit occurence count field contains the number of times a fault has gone from active to previously active.";
CM_ SG_ 2566834942 SPN1High "SPN #1 (Conversion Version 4)";
CM_ SG_ 2566834942 FailureModeIdentifier1 "The FMI defines the type of failure detected in the subsystem identified by an SPN.";
CM_ SG_ 2566834942 FlashMalfuncIndicatorLamp "This parameter provides the capability to flash the MIL (SPN 3038).";
CM_ SG_ 2566834942 FlashRedStopLamp "This parameter provides the capability to flash the RSL (SPN 3039).";
CM_ SG_ 2566834942 FlashAmberWarningLamp "This parameter provides the capability to flash the AWL (SPN 3040). ";
CM_ SG_ 2566834942 FlashProtectLamp "This parameter provides the capability to flash the engine protect lamp (SPN 3041).";
CM_ SG_ 2566834942 MalfunctionIndicatorLampStatus "A lamp used to relay only emissions-related trouble code information.";
CM_ SG_ 2566834942 RedStopLampState "This lamp is uesed to relay trouble code information that is of a severe enought condition that it warrants stopping the vehicle.";
CM_ SG_ 2566834942 AmberWarningLampStatus "This lamp is used to relay trouble code information that is reporting a problem with the vehicle system but the vehicle need
not be immediately stopped.";
CM_ SG_ 2566834942 ProtectLampStatus "This lamp is used to relay trouble code informatio that is reporting a problem with a vehicle system that is most
probably not electronic subsystem related.";
CM_ BO_ 2566832622 "High Resolution Vehicle Distance";
CM_ SG_ 2566832622 HighResolutionTripDistance "Distance traveled during all or part of a journey.";
CM_ SG_ 2566832622 HghReslutionTotalVehicleDistance "Accumulated distance traveled by the vehicle during its operation.";
CM_ BO_ 2566842094 "Time/Date";
CM_ SG_ 2566842094 LocalMinuteOffset "Local offset in minutes from a reference time.";
CM_ SG_ 2566842094 Year "Part of a parameter used to represent a calendar date.";
CM_ SG_ 2566842094 Day "Part of a parameter used to represent a calendar date.";
CM_ SG_ 2566842094 Month "Part of a parameter used to represent a calendar date.";
CM_ SG_ 2566842094 Hours "Part of a parameter used to represent time.";
CM_ SG_ 2566842094 Minutes "Part of a parameter used to represent time.";
CM_ SG_ 2566842094 Seconds "Part of a parameter used to represent time.";
CM_ SG_ 2365484270 DirectionIndicator "Indicates the direction of the vehicle.";
CM_ SG_ 2365484270 HandlingInformation "Indicates that handling information is present.";
CM_ SG_ 2365484270 SystemEvent "Indicates that a tachograph event has occurred.";
CM_ SG_ 2365484270 Overspeed "Indicates whether the vehicle is exceeding the legal speed limit set in the tachograph.";
CM_ SG_ 2365484270 TachographVehicleSpeed "Speed of the vehicle registered by the tachograph.";
CM_ SG_ 2365484270 TachographOutputShaftSpeed "Calculated speed of the transmission output shaft.";
CM_ SG_ 2365484270 DriveRecognize "Indicates whether motion of the vehicle is detected or not.";
CM_ SG_ 2365484270 Driver2WorkingState "State of work of the driver.";
CM_ SG_ 2365484270 Driver2TimeRelatedStates "Indicates if the driver approaches or exceeds working time limits (or other limits).";
CM_ SG_ 2365484270 Driver1WorkingState "State of work of the driver";
CM_ SG_ 2365484270 Driver1TimeRelatedStates "Indicates if the driver approaches or exceeds working time limits (or other limits).";
BA_DEF_ BO_  "SingleFrame" INT 0 1;
BA_DEF_ SG_  "SigType" ENUM  "Default","Range","RangeSigned","ASCII","Discrete","Control","ReferencePGN","DTC","StringDelimiter","StringLength","StringLengthControl","MessageCounter","MessageChecksum";
BA_DEF_ SG_  "GenSigEVName" STRING ;
BA_DEF_ SG_  "GenSigILSupport" ENUM  "No","Yes";
BA_DEF_ SG_  "GenSigSendType" ENUM  "Cyclic","OnWrite","OnWriteWithRepetition","OnChange","OnChangeWithRepetition","IfActive","IfActiveWithRepetition","NoSigSendType";
BA_DEF_ SG_  "GenSigStartValue" INT 0 10000;
BA_DEF_ BO_  "GenMsgILSupport" ENUM  "No","Yes";
BA_DEF_ BO_  "GenMsgSendType" ENUM  "cyclic","NotUsed","IfActive","NotUsed","NotUsed","NotUsed","NotUsed","NotUsed","noMsgSendType";
BA_DEF_ BO_  "GenMsgRequestable" INT 0 1;
BA_DEF_ BO_  "GenMsgCycleTime" INT 0 3600000;
BA_DEF_ SG_  "SPN" INT 0 524287;
BA_DEF_ BO_  "VFrameFormat" ENUM  "StandardCAN","ExtendedCAN","reserved","J1939PG";
BA_DEF_DEF_  "SingleFrame" 1;
BA_DEF_DEF_  "SigType" "Default";
BA_DEF_DEF_  "GenSigEVName" "Env@Nodename_@Signame";
BA_DEF_DEF_  "GenSigILSupport" "Yes";
BA_DEF_DEF_  "GenSigSendType" "NoSigSendType";
BA_DEF_DEF_  "GenSigStartValue" 0;
BA_DEF_DEF_  "GenMsgILSupport" "Yes";
BA_DEF_DEF_  "GenMsgSendType" "noMsgSendType";
BA_DEF_DEF_  "GenMsgRequestable" 1;
BA_DEF_DEF_  "GenMsgCycleTime" 0;
BA_DEF_DEF_  "SPN" 0;
BA_DEF_DEF_  "VFrameFormat" "J1939PG";
BA_ "GenMsgSendType" BO_ 2566827275 0;
BA_ "GenMsgCycleTime" BO_ 2566827275 100;
BA_ "GenMsgCycleTime" BO_ 2364539904 10;
BA_ "GenMsgSendType" BO_ 2364539904 0;
BA_ "GenMsgCycleTime" BO_ 2566719232 1000;
BA_ "GenMsgSendType" BO_ 2566719232 0;
BA_ "GenMsgCycleTime" BO_ 2566854216 100;
BA_ "GenMsgSendType" BO_ 2566854216 0;
BA_ "GenMsgCycleTime" BO_ 2566803211 100;
BA_ "GenMsgSendType" BO_ 2566803211 0;
BA_ "GenMsgCycleTime" BO_ 2566804992 1000;
BA_ "GenMsgSendType" BO_ 2566804992 0;
BA_ "GenMsgCycleTime" BO_ 2566701807 100;
BA_ "GenMsgSendType" BO_ 2566701807 0;
BA_ "GenMsgCycleTime" BO_ 2566856943 10;
BA_ "GenMsgSendType" BO_ 2566856943 0;
BA_ "GenMsgCycleTime" BO_ 2565866991 100;
BA_ "GenMsgSendType" BO_ 2565866991 0;
BA_ "GenMsgCycleTime" BO_ 2566896720 50;
BA_ "GenMsgSendType" BO_ 2566896720 0;
BA_ "GenMsgCycleTime" BO_ 2566880561 100;
BA_ "GenMsgSendType" BO_ 2566880561 0;
BA_ "GenMsgCycleTime" BO_ 2566880305 100;
BA_ "GenMsgSendType" BO_ 2566880305 0;
BA_ "GenMsgCycleTime" BO_ 2566880049 100;
BA_ "GenMsgSendType" BO_ 2566880049 0;
BA_ "GenMsgCycleTime" BO_ 2566851111 100;
BA_ "GenMsgSendType" BO_ 2566851111 0;
BA_ "GenMsgCycleTime" BO_ 2566880535 100;
BA_ "GenMsgSendType" BO_ 2566880535 0;
BA_ "GenMsgCycleTime" BO_ 2566832622 1000;
BA_ "GenMsgSendType" BO_ 2566832622 0;
BA_ "GenMsgCycleTime" BO_ 2566842094 1000;
BA_ "GenMsgSendType" BO_ 2566842094 0;
BA_ "GenMsgCycleTime" BO_ 2365484270 50;
BA_ "GenMsgSendType" BO_ 2365484270 0;
BA_ "GenMsgCycleTime" BO_ 2566876209 100;
BA_ "GenMsgSendType" BO_ 2566876209 0;
BA_ "GenMsgCycleTime" BO_ 2566875927 50;
BA_ "GenMsgSendType" BO_ 2566875927 0;
BA_ "GenMsgCycleTime" BO_ 2566875671 50;
BA_ "GenMsgSendType" BO_ 2566875671 0;
BA_ "GenMsgSendType" BO_ 2566866737 0;
BA_ "GenMsgCycleTime" BO_ 2566866737 500;
BA_ "GenMsgSendType" BO_ 2566866481 0;
BA_ "GenMsgCycleTime" BO_ 2566866481 500;
BA_ "SPN" SG_ 2566834735 FailureModeIdentifier5 1215;
BA_ "SPN" SG_ 2566834735 FailureModeIdentifier4 1215;
BA_ "SPN" SG_ 2566834735 FailureModeIdentifier3 1215;
BA_ "SPN" SG_ 2566834735 FailureModeIdentifier2 1215;
BA_ "SPN" SG_ 2566834735 OccurenceCount5 1216;
BA_ "SPN" SG_ 2566834735 OccurenceCount4 1216;
BA_ "SPN" SG_ 2566834735 OccurenceCount3 1216;
BA_ "SPN" SG_ 2566834735 OccurenceCount2 1216;
BA_ "SPN" SG_ 2566834735 SPNConversionMethod5 1706;
BA_ "SPN" SG_ 2566834735 SPNConversionMethod4 1706;
BA_ "SPN" SG_ 2566834735 SPNConversionMethod3 1706;
BA_ "SPN" SG_ 2566834735 SPNConversionMethod2 1706;
BA_ "SPN" SG_ 2566834735 SPN5High 1214;
BA_ "SPN" SG_ 2566834735 SPN5 1214;
BA_ "SPN" SG_ 2566834735 SPN4High 1214;
BA_ "SPN" SG_ 2566834735 SPN4 1214;
BA_ "SPN" SG_ 2566834735 SPN3High 1214;
BA_ "SPN" SG_ 2566834735 SPN3 1214;
BA_ "SPN" SG_ 2566834735 SPN2High 1214;
BA_ "SPN" SG_ 2566834735 SPN2 1214;
BA_ "SPN" SG_ 2566834735 SPN1 1214;
BA_ "SPN" SG_ 2566834735 SPNConversionMethod1 1706;
BA_ "SPN" SG_ 2566834735 OccurenceCount1 1216;
BA_ "SPN" SG_ 2566834735 SPN1High 1214;
BA_ "SPN" SG_ 2566834735 FailureModeIdentifier1 1215;
BA_ "SPN" SG_ 2566834735 FlashMalfuncIndicatorLamp 3038;
BA_ "SPN" SG_ 2566834735 FlashRedStopLamp 3039;
BA_ "SPN" SG_ 2566834735 FlashAmberWarningLamp 3040;
BA_ "SPN" SG_ 2566834735 FlashProtectLamp 3041;
BA_ "SPN" SG_ 2566834735 MalfunctionIndicatorLampStatus 1213;
BA_ "SPN" SG_ 2566834735 RedStopLampState 623;
BA_ "SPN" SG_ 2566834735 AmberWarningLampStatus 624;
BA_ "SPN" SG_ 2566834735 ProtectLampStatus 987;
BA_ "SPN" SG_ 2566834699 FailureModeIdentifier5 1215;
BA_ "SPN" SG_ 2566834699 FailureModeIdentifier4 1215;
BA_ "SPN" SG_ 2566834699 FailureModeIdentifier3 1215;
BA_ "SPN" SG_ 2566834699 FailureModeIdentifier2 1215;
BA_ "SPN" SG_ 2566834699 OccurenceCount5 1216;
BA_ "SPN" SG_ 2566834699 OccurenceCount4 1216;
BA_ "SPN" SG_ 2566834699 OccurenceCount3 1216;
BA_ "SPN" SG_ 2566834699 OccurenceCount2 1216;
BA_ "SPN" SG_ 2566834699 SPNConversionMethod5 1706;
BA_ "SPN" SG_ 2566834699 SPNConversionMethod4 1706;
BA_ "SPN" SG_ 2566834699 SPNConversionMethod3 1706;
BA_ "SPN" SG_ 2566834699 SPNConversionMethod2 1706;
BA_ "SPN" SG_ 2566834699 SPN5High 1214;
BA_ "SPN" SG_ 2566834699 SPN5 1214;
BA_ "SPN" SG_ 2566834699 SPN4High 1214;
BA_ "SPN" SG_ 2566834699 SPN4 1214;
BA_ "SPN" SG_ 2566834699 SPN3High 1214;
BA_ "SPN" SG_ 2566834699 SPN3 1214;
BA_ "SPN" SG_ 2566834699 SPN2High 1214;
BA_ "SPN" SG_ 2566834699 SPN2 1214;
BA_ "SPN" SG_ 2566834699 SPN1 1214;
BA_ "SPN" SG_ 2566834699 SPNConversionMethod1 1706;
BA_ "SPN" SG_ 2566834699 OccurenceCount1 1216;
BA_ "SPN" SG_ 2566834699 SPN1High 1214;
BA_ "SPN" SG_ 2566834699 FailureModeIdentifier1 1215;
BA_ "SPN" SG_ 2566834699 FlashMalfuncIndicatorLamp 3038;
BA_ "SPN" SG_ 2566834699 FlashRedStopLamp 3039;
BA_ "SPN" SG_ 2566834699 FlashAmberWarningLamp 3040;
BA_ "SPN" SG_ 2566834699 FlashProtectLamp 3041;
BA_ "SPN" SG_ 2566834699 MalfunctionIndicatorLampStatus 1213;
BA_ "SPN" SG_ 2566834699 RedStopLampState 623;
BA_ "SPN" SG_ 2566834699 AmberWarningLampStatus 624;
BA_ "SPN" SG_ 2566834699 ProtectLampStatus 987;
BA_ "SPN" SG_ 2566834816 FailureModeIdentifier5 1215;
BA_ "SPN" SG_ 2566834816 FailureModeIdentifier4 1215;
BA_ "SPN" SG_ 2566834816 FailureModeIdentifier3 1215;
BA_ "SPN" SG_ 2566834816 FailureModeIdentifier2 1215;
BA_ "SPN" SG_ 2566834816 OccurenceCount5 1216;
BA_ "SPN" SG_ 2566834816 OccurenceCount4 1216;
BA_ "SPN" SG_ 2566834816 OccurenceCount3 1216;
BA_ "SPN" SG_ 2566834816 OccurenceCount2 1216;
BA_ "SPN" SG_ 2566834816 SPNConversionMethod5 1706;
BA_ "SPN" SG_ 2566834816 SPNConversionMethod4 1706;
BA_ "SPN" SG_ 2566834816 SPNConversionMethod3 1706;
BA_ "SPN" SG_ 2566834816 SPNConversionMethod2 1706;
BA_ "SPN" SG_ 2566834816 SPN5High 1214;
BA_ "SPN" SG_ 2566834816 SPN5 1214;
BA_ "SPN" SG_ 2566834816 SPN4High 1214;
BA_ "SPN" SG_ 2566834816 SPN4 1214;
BA_ "SPN" SG_ 2566834816 SPN3High 1214;
BA_ "SPN" SG_ 2566834816 SPN3 1214;
BA_ "SPN" SG_ 2566834816 SPN2High 1214;
BA_ "SPN" SG_ 2566834816 SPN2 1214;
BA_ "SPN" SG_ 2566834816 SPN1 1214;
BA_ "SPN" SG_ 2566834816 SPNConversionMethod1 1706;
BA_ "SPN" SG_ 2566834816 OccurenceCount1 1216;
BA_ "SPN" SG_ 2566834816 SPN1High 1214;
BA_ "SPN" SG_ 2566834816 FailureModeIdentifier1 1215;
BA_ "SPN" SG_ 2566834816 FlashMalfuncIndicatorLamp 3038;
BA_ "SPN" SG_ 2566834816 FlashRedStopLamp 3039;
BA_ "SPN" SG_ 2566834816 FlashAmberWarningLamp 3040;
BA_ "SPN" SG_ 2566834816 FlashProtectLamp 3041;
BA_ "SPN" SG_ 2566834816 MalfunctionIndicatorLampStatus 1213;
BA_ "SPN" SG_ 2566834816 RedStopLampState 623;
BA_ "SPN" SG_ 2566834816 AmberWarningLampStatus 624;
BA_ "SPN" SG_ 2566834816 ProtectLampStatus 987;
BA_ "SPN" SG_ 2566834688 FailureModeIdentifier5 1215;
BA_ "SPN" SG_ 2566834688 FailureModeIdentifier4 1215;
BA_ "SPN" SG_ 2566834688 FailureModeIdentifier3 1215;
BA_ "SPN" SG_ 2566834688 FailureModeIdentifier2 1215;
BA_ "SPN" SG_ 2566834688 OccurenceCount5 1216;
BA_ "SPN" SG_ 2566834688 OccurenceCount4 1216;
BA_ "SPN" SG_ 2566834688 OccurenceCount3 1216;
BA_ "SPN" SG_ 2566834688 OccurenceCount2 1216;
BA_ "SPN" SG_ 2566834688 SPNConversionMethod5 1706;
BA_ "SPN" SG_ 2566834688 SPNConversionMethod4 1706;
BA_ "SPN" SG_ 2566834688 SPNConversionMethod3 1706;
BA_ "SPN" SG_ 2566834688 SPNConversionMethod2 1706;
BA_ "SPN" SG_ 2566834688 SPN5High 1214;
BA_ "SPN" SG_ 2566834688 SPN5 1214;
BA_ "SPN" SG_ 2566834688 SPN4High 1214;
BA_ "SPN" SG_ 2566834688 SPN4 1214;
BA_ "SPN" SG_ 2566834688 SPN3High 1214;
BA_ "SPN" SG_ 2566834688 SPN3 1214;
BA_ "SPN" SG_ 2566834688 SPN2High 1214;
BA_ "SPN" SG_ 2566834688 SPN2 1214;
BA_ "SPN" SG_ 2566834688 SPN1 1214;
BA_ "SPN" SG_ 2566834688 SPNConversionMethod1 1706;
BA_ "SPN" SG_ 2566834688 OccurenceCount1 1216;
BA_ "SPN" SG_ 2566834688 SPN1High 1214;
BA_ "SPN" SG_ 2566834688 FailureModeIdentifier1 1215;
BA_ "SPN" SG_ 2566834688 FlashMalfuncIndicatorLamp 3038;
BA_ "SPN" SG_ 2566834688 FlashRedStopLamp 3039;
BA_ "SPN" SG_ 2566834688 FlashAmberWarningLamp 3040;
BA_ "SPN" SG_ 2566834688 FlashProtectLamp 3041;
BA_ "SPN" SG_ 2566834688 MalfunctionIndicatorLampStatus 1213;
BA_ "SPN" SG_ 2566834688 RedStopLampState 623;
BA_ "SPN" SG_ 2566834688 AmberWarningLampStatus 624;
BA_ "SPN" SG_ 2566834688 ProtectLampStatus 987;
BA_ "SPN" SG_ 2566834927 FailureModeIdentifier5 1215;
BA_ "SPN" SG_ 2566834927 FailureModeIdentifier4 1215;
BA_ "SPN" SG_ 2566834927 FailureModeIdentifier3 1215;
BA_ "SPN" SG_ 2566834927 FailureModeIdentifier2 1215;
BA_ "SPN" SG_ 2566834927 OccurenceCount5 1216;
BA_ "SPN" SG_ 2566834927 OccurenceCount4 1216;
BA_ "SPN" SG_ 2566834927 OccurenceCount3 1216;
BA_ "SPN" SG_ 2566834927 OccurenceCount2 1216;
BA_ "SPN" SG_ 2566834927 SPNConversionMethod5 1706;
BA_ "SPN" SG_ 2566834927 SPNConversionMethod4 1706;
BA_ "SPN" SG_ 2566834927 SPNConversionMethod3 1706;
BA_ "SPN" SG_ 2566834927 SPNConversionMethod2 1706;
BA_ "SPN" SG_ 2566834927 SPN5High 1214;
BA_ "SPN" SG_ 2566834927 SPN5 1214;
BA_ "SPN" SG_ 2566834927 SPN4High 1214;
BA_ "SPN" SG_ 2566834927 SPN4 1214;
BA_ "SPN" SG_ 2566834927 SPN3High 1214;
BA_ "SPN" SG_ 2566834927 SPN3 1214;
BA_ "SPN" SG_ 2566834927 SPN2High 1214;
BA_ "SPN" SG_ 2566834927 SPN2 1214;
BA_ "SPN" SG_ 2566834927 SPN1 1214;
BA_ "SPN" SG_ 2566834927 SPNConversionMethod1 1706;
BA_ "SPN" SG_ 2566834927 OccurenceCount1 1216;
BA_ "SPN" SG_ 2566834927 SPN1High 1214;
BA_ "SPN" SG_ 2566834927 FailureModeIdentifier1 1215;
BA_ "SPN" SG_ 2566834927 FlashMalfuncIndicatorLamp 3038;
BA_ "SPN" SG_ 2566834927 FlashRedStopLamp 3039;
BA_ "SPN" SG_ 2566834927 FlashAmberWarningLamp 3040;
BA_ "SPN" SG_ 2566834927 FlashProtectLamp 3041;
BA_ "SPN" SG_ 2566834927 MalfunctionIndicatorLampStatus 1213;
BA_ "SPN" SG_ 2566834927 RedStopLampState 623;
BA_ "SPN" SG_ 2566834927 AmberWarningLampStatus 624;
BA_ "SPN" SG_ 2566834927 ProtectLampStatus 987;
BA_ "SPN" SG_ 2566834737 FailureModeIdentifier5 1215;
BA_ "SPN" SG_ 2566834737 FailureModeIdentifier4 1215;
BA_ "SPN" SG_ 2566834737 FailureModeIdentifier3 1215;
BA_ "SPN" SG_ 2566834737 FailureModeIdentifier2 1215;
BA_ "SPN" SG_ 2566834737 OccurenceCount5 1216;
BA_ "SPN" SG_ 2566834737 OccurenceCount4 1216;
BA_ "SPN" SG_ 2566834737 OccurenceCount3 1216;
BA_ "SPN" SG_ 2566834737 OccurenceCount2 1216;
BA_ "SPN" SG_ 2566834737 SPNConversionMethod5 1706;
BA_ "SPN" SG_ 2566834737 SPNConversionMethod4 1706;
BA_ "SPN" SG_ 2566834737 SPNConversionMethod3 1706;
BA_ "SPN" SG_ 2566834737 SPNConversionMethod2 1706;
BA_ "SPN" SG_ 2566834737 SPN5High 1214;
BA_ "SPN" SG_ 2566834737 SPN5 1214;
BA_ "SPN" SG_ 2566834737 SPN4High 1214;
BA_ "SPN" SG_ 2566834737 SPN4 1214;
BA_ "SPN" SG_ 2566834737 SPN3High 1214;
BA_ "SPN" SG_ 2566834737 SPN3 1214;
BA_ "SPN" SG_ 2566834737 SPN2High 1214;
BA_ "SPN" SG_ 2566834737 SPN2 1214;
BA_ "SPN" SG_ 2566834737 SPN1 1214;
BA_ "SPN" SG_ 2566834737 SPNConversionMethod1 1706;
BA_ "SPN" SG_ 2566834737 OccurenceCount1 1216;
BA_ "SPN" SG_ 2566834737 SPN1High 1214;
BA_ "SPN" SG_ 2566834737 FailureModeIdentifier1 1215;
BA_ "SPN" SG_ 2566834737 FlashMalfuncIndicatorLamp 3038;
BA_ "SPN" SG_ 2566834737 FlashRedStopLamp 3039;
BA_ "SPN" SG_ 2566834737 FlashAmberWarningLamp 3040;
BA_ "SPN" SG_ 2566834737 FlashProtectLamp 3041;
BA_ "SPN" SG_ 2566834737 MalfunctionIndicatorLampStatus 1213;
BA_ "SPN" SG_ 2566834737 RedStopLampState 623;
BA_ "SPN" SG_ 2566834737 AmberWarningLampStatus 624;
BA_ "SPN" SG_ 2566834737 ProtectLampStatus 987;
BA_ "SPN" SG_ 2566834760 FailureModeIdentifier5 1215;
BA_ "SPN" SG_ 2566834760 FailureModeIdentifier4 1215;
BA_ "SPN" SG_ 2566834760 FailureModeIdentifier3 1215;
BA_ "SPN" SG_ 2566834760 FailureModeIdentifier2 1215;
BA_ "SPN" SG_ 2566834760 OccurenceCount5 1216;
BA_ "SPN" SG_ 2566834760 OccurenceCount4 1216;
BA_ "SPN" SG_ 2566834760 OccurenceCount3 1216;
BA_ "SPN" SG_ 2566834760 OccurenceCount2 1216;
BA_ "SPN" SG_ 2566834760 SPNConversionMethod5 1706;
BA_ "SPN" SG_ 2566834760 SPNConversionMethod4 1706;
BA_ "SPN" SG_ 2566834760 SPNConversionMethod3 1706;
BA_ "SPN" SG_ 2566834760 SPNConversionMethod2 1706;
BA_ "SPN" SG_ 2566834760 SPN5High 1214;
BA_ "SPN" SG_ 2566834760 SPN5 1214;
BA_ "SPN" SG_ 2566834760 SPN4High 1214;
BA_ "SPN" SG_ 2566834760 SPN4 1214;
BA_ "SPN" SG_ 2566834760 SPN3High 1214;
BA_ "SPN" SG_ 2566834760 SPN3 1214;
BA_ "SPN" SG_ 2566834760 SPN2High 1214;
BA_ "SPN" SG_ 2566834760 SPN2 1214;
BA_ "SPN" SG_ 2566834760 SPN1 1214;
BA_ "SPN" SG_ 2566834760 SPNConversionMethod1 1706;
BA_ "SPN" SG_ 2566834760 OccurenceCount1 1216;
BA_ "SPN" SG_ 2566834760 SPN1High 1214;
BA_ "SPN" SG_ 2566834760 FailureModeIdentifier1 1215;
BA_ "SPN" SG_ 2566834760 FlashMalfuncIndicatorLamp 3038;
BA_ "SPN" SG_ 2566834760 FlashRedStopLamp 3039;
BA_ "SPN" SG_ 2566834760 FlashAmberWarningLamp 3040;
BA_ "SPN" SG_ 2566834760 FlashProtectLamp 3041;
BA_ "SPN" SG_ 2566834760 MalfunctionIndicatorLampStatus 1213;
BA_ "SPN" SG_ 2566834760 RedStopLampState 623;
BA_ "SPN" SG_ 2566834760 AmberWarningLampStatus 624;
BA_ "SPN" SG_ 2566834760 ProtectLampStatus 987;
BA_ "SPN" SG_ 2566834727 FailureModeIdentifier5 1215;
BA_ "SPN" SG_ 2566834727 FailureModeIdentifier4 1215;
BA_ "SPN" SG_ 2566834727 FailureModeIdentifier3 1215;
BA_ "SPN" SG_ 2566834727 FailureModeIdentifier2 1215;
BA_ "SPN" SG_ 2566834727 OccurenceCount5 1216;
BA_ "SPN" SG_ 2566834727 OccurenceCount4 1216;
BA_ "SPN" SG_ 2566834727 OccurenceCount3 1216;
BA_ "SPN" SG_ 2566834727 OccurenceCount2 1216;
BA_ "SPN" SG_ 2566834727 SPNConversionMethod5 1706;
BA_ "SPN" SG_ 2566834727 SPNConversionMethod4 1706;
BA_ "SPN" SG_ 2566834727 SPNConversionMethod3 1706;
BA_ "SPN" SG_ 2566834727 SPNConversionMethod2 1706;
BA_ "SPN" SG_ 2566834727 SPN5High 1214;
BA_ "SPN" SG_ 2566834727 SPN5 1214;
BA_ "SPN" SG_ 2566834727 SPN4High 1214;
BA_ "SPN" SG_ 2566834727 SPN4 1214;
BA_ "SPN" SG_ 2566834727 SPN3High 1214;
BA_ "SPN" SG_ 2566834727 SPN3 1214;
BA_ "SPN" SG_ 2566834727 SPN2High 1214;
BA_ "SPN" SG_ 2566834727 SPN2 1214;
BA_ "SPN" SG_ 2566834727 SPN1 1214;
BA_ "SPN" SG_ 2566834727 SPNConversionMethod1 1706;
BA_ "SPN" SG_ 2566834727 OccurenceCount1 1216;
BA_ "SPN" SG_ 2566834727 SPN1High 1214;
BA_ "SPN" SG_ 2566834727 FailureModeIdentifier1 1215;
BA_ "SPN" SG_ 2566834727 FlashMalfuncIndicatorLamp 3038;
BA_ "SPN" SG_ 2566834727 FlashRedStopLamp 3039;
BA_ "SPN" SG_ 2566834727 FlashAmberWarningLamp 3040;
BA_ "SPN" SG_ 2566834727 FlashProtectLamp 3041;
BA_ "SPN" SG_ 2566834727 MalfunctionIndicatorLampStatus 1213;
BA_ "SPN" SG_ 2566834727 RedStopLampState 623;
BA_ "SPN" SG_ 2566834727 AmberWarningLampStatus 624;
BA_ "SPN" SG_ 2566834727 ProtectLampStatus 987;
BA_ "SPN" SG_ 2566834926 FailureModeIdentifier5 1215;
BA_ "SPN" SG_ 2566834926 FailureModeIdentifier4 1215;
BA_ "SPN" SG_ 2566834926 FailureModeIdentifier3 1215;
BA_ "SPN" SG_ 2566834926 FailureModeIdentifier2 1215;
BA_ "SPN" SG_ 2566834926 OccurenceCount5 1216;
BA_ "SPN" SG_ 2566834926 OccurenceCount4 1216;
BA_ "SPN" SG_ 2566834926 OccurenceCount3 1216;
BA_ "SPN" SG_ 2566834926 OccurenceCount2 1216;
BA_ "SPN" SG_ 2566834926 SPNConversionMethod5 1706;
BA_ "SPN" SG_ 2566834926 SPNConversionMethod4 1706;
BA_ "SPN" SG_ 2566834926 SPNConversionMethod3 1706;
BA_ "SPN" SG_ 2566834926 SPNConversionMethod2 1706;
BA_ "SPN" SG_ 2566834926 SPN5High 1214;
BA_ "SPN" SG_ 2566834926 SPN5 1214;
BA_ "SPN" SG_ 2566834926 SPN4High 1214;
BA_ "SPN" SG_ 2566834926 SPN4 1214;
BA_ "SPN" SG_ 2566834926 SPN3High 1214;
BA_ "SPN" SG_ 2566834926 SPN3 1214;
BA_ "SPN" SG_ 2566834926 SPN2High 1214;
BA_ "SPN" SG_ 2566834926 SPN2 1214;
BA_ "SPN" SG_ 2566834926 SPN1 1214;
BA_ "SPN" SG_ 2566834926 SPNConversionMethod1 1706;
BA_ "SPN" SG_ 2566834926 OccurenceCount1 1216;
BA_ "SPN" SG_ 2566834926 SPN1High 1214;
BA_ "SPN" SG_ 2566834926 FailureModeIdentifier1 1215;
BA_ "SPN" SG_ 2566834926 FlashMalfuncIndicatorLamp 3038;
BA_ "SPN" SG_ 2566834926 FlashRedStopLamp 3039;
BA_ "SPN" SG_ 2566834926 FlashAmberWarningLamp 3040;
BA_ "SPN" SG_ 2566834926 FlashProtectLamp 3041;
BA_ "SPN" SG_ 2566834926 MalfunctionIndicatorLampStatus 1213;
BA_ "SPN" SG_ 2566834926 RedStopLampState 623;
BA_ "SPN" SG_ 2566834926 AmberWarningLampStatus 624;
BA_ "SPN" SG_ 2566834926 ProtectLampStatus 987;
BA_ "SPN" SG_ 2566834768 FailureModeIdentifier5 1215;
BA_ "SPN" SG_ 2566834768 FailureModeIdentifier4 1215;
BA_ "SPN" SG_ 2566834768 FailureModeIdentifier3 1215;
BA_ "SPN" SG_ 2566834768 FailureModeIdentifier2 1215;
BA_ "SPN" SG_ 2566834768 OccurenceCount5 1216;
BA_ "SPN" SG_ 2566834768 OccurenceCount4 1216;
BA_ "SPN" SG_ 2566834768 OccurenceCount3 1216;
BA_ "SPN" SG_ 2566834768 OccurenceCount2 1216;
BA_ "SPN" SG_ 2566834768 SPNConversionMethod5 1706;
BA_ "SPN" SG_ 2566834768 SPNConversionMethod4 1706;
BA_ "SPN" SG_ 2566834768 SPNConversionMethod3 1706;
BA_ "SPN" SG_ 2566834768 SPNConversionMethod2 1706;
BA_ "SPN" SG_ 2566834768 SPN5High 1214;
BA_ "SPN" SG_ 2566834768 SPN5 1214;
BA_ "SPN" SG_ 2566834768 SPN4High 1214;
BA_ "SPN" SG_ 2566834768 SPN4 1214;
BA_ "SPN" SG_ 2566834768 SPN3High 1214;
BA_ "SPN" SG_ 2566834768 SPN3 1214;
BA_ "SPN" SG_ 2566834768 SPN2High 1214;
BA_ "SPN" SG_ 2566834768 SPN2 1214;
BA_ "SPN" SG_ 2566834768 SPN1 1214;
BA_ "SPN" SG_ 2566834768 SPNConversionMethod1 1706;
BA_ "SPN" SG_ 2566834768 OccurenceCount1 1216;
BA_ "SPN" SG_ 2566834768 SPN1High 1214;
BA_ "SPN" SG_ 2566834768 FailureModeIdentifier1 1215;
BA_ "SPN" SG_ 2566834768 FlashMalfuncIndicatorLamp 3038;
BA_ "SPN" SG_ 2566834768 FlashRedStopLamp 3039;
BA_ "SPN" SG_ 2566834768 FlashAmberWarningLamp 3040;
BA_ "SPN" SG_ 2566834768 FlashProtectLamp 3041;
BA_ "SPN" SG_ 2566834768 MalfunctionIndicatorLampStatus 1213;
BA_ "SPN" SG_ 2566834768 RedStopLampState 623;
BA_ "SPN" SG_ 2566834768 AmberWarningLampStatus 624;
BA_ "SPN" SG_ 2566834768 ProtectLampStatus 987;
BA_ "SPN" SG_ 2566834931 FailureModeIdentifier5 1215;
BA_ "SPN" SG_ 2566834931 FailureModeIdentifier4 1215;
BA_ "SPN" SG_ 2566834931 FailureModeIdentifier3 1215;
BA_ "SPN" SG_ 2566834931 FailureModeIdentifier2 1215;
BA_ "SPN" SG_ 2566834931 OccurenceCount5 1216;
BA_ "SPN" SG_ 2566834931 OccurenceCount4 1216;
BA_ "SPN" SG_ 2566834931 OccurenceCount3 1216;
BA_ "SPN" SG_ 2566834931 OccurenceCount2 1216;
BA_ "SPN" SG_ 2566834931 SPNConversionMethod5 1706;
BA_ "SPN" SG_ 2566834931 SPNConversionMethod4 1706;
BA_ "SPN" SG_ 2566834931 SPNConversionMethod3 1706;
BA_ "SPN" SG_ 2566834931 SPNConversionMethod2 1706;
BA_ "SPN" SG_ 2566834931 SPN5High 1214;
BA_ "SPN" SG_ 2566834931 SPN5 1214;
BA_ "SPN" SG_ 2566834931 SPN4High 1214;
BA_ "SPN" SG_ 2566834931 SPN4 1214;
BA_ "SPN" SG_ 2566834931 SPN3High 1214;
BA_ "SPN" SG_ 2566834931 SPN3 1214;
BA_ "SPN" SG_ 2566834931 SPN2High 1214;
BA_ "SPN" SG_ 2566834931 SPN2 1214;
BA_ "SPN" SG_ 2566834931 SPN1 1214;
BA_ "SPN" SG_ 2566834931 SPNConversionMethod1 1706;
BA_ "SPN" SG_ 2566834931 OccurenceCount1 1216;
BA_ "SPN" SG_ 2566834931 SPN1High 1214;
BA_ "SPN" SG_ 2566834931 FailureModeIdentifier1 1215;
BA_ "SPN" SG_ 2566834931 FlashMalfuncIndicatorLamp 3038;
BA_ "SPN" SG_ 2566834931 FlashRedStopLamp 3039;
BA_ "SPN" SG_ 2566834931 FlashAmberWarningLamp 3040;
BA_ "SPN" SG_ 2566834931 FlashProtectLamp 3041;
BA_ "SPN" SG_ 2566834931 MalfunctionIndicatorLampStatus 1213;
BA_ "SPN" SG_ 2566834931 RedStopLampState 623;
BA_ "SPN" SG_ 2566834931 AmberWarningLampStatus 624;
BA_ "SPN" SG_ 2566834931 ProtectLampStatus 987;
BA_ "SPN" SG_ 2364539904 EngSpeed 190;
BA_ "GenSigStartValue" SG_ 2566854216 VehiclePowerDemand 125;
BA_ "SPN" SG_ 2566803211 VDCFullyOperational 1814;
BA_ "SPN" SG_ 2566803211 VDCInformationSignal 1813;
BA_ "SPN" SG_ 2566804992 CatalystTankLevel 1761;
BA_ "GenSigStartValue" SG_ 2566856943 EMxDriverRetarderPctTrq 125;
BA_ "GenSigStartValue" SG_ 2566856943 EMxActPctTorque 125;
BA_ "SPN" SG_ 2565866991 TransCurrentGear 523;
BA_ "SPN" SG_ 2566834942 FailureModeIdentifier5 1215;
BA_ "SPN" SG_ 2566834942 FailureModeIdentifier4 1215;
BA_ "SPN" SG_ 2566834942 FailureModeIdentifier3 1215;
BA_ "SPN" SG_ 2566834942 FailureModeIdentifier2 1215;
BA_ "SPN" SG_ 2566834942 OccurenceCount5 1216;
BA_ "SPN" SG_ 2566834942 OccurenceCount4 1216;
BA_ "SPN" SG_ 2566834942 OccurenceCount3 1216;
BA_ "SPN" SG_ 2566834942 OccurenceCount2 1216;
BA_ "SPN" SG_ 2566834942 SPNConversionMethod5 1706;
BA_ "SPN" SG_ 2566834942 SPNConversionMethod4 1706;
BA_ "SPN" SG_ 2566834942 SPNConversionMethod3 1706;
BA_ "SPN" SG_ 2566834942 SPNConversionMethod2 1706;
BA_ "SPN" SG_ 2566834942 SPN5High 1214;
BA_ "SPN" SG_ 2566834942 SPN5 1214;
BA_ "SPN" SG_ 2566834942 SPN4High 1214;
BA_ "SPN" SG_ 2566834942 SPN4 1214;
BA_ "SPN" SG_ 2566834942 SPN3High 1214;
BA_ "SPN" SG_ 2566834942 SPN3 1214;
BA_ "SPN" SG_ 2566834942 SPN2High 1214;
BA_ "SPN" SG_ 2566834942 SPN2 1214;
BA_ "SPN" SG_ 2566834942 SPN1 1214;
BA_ "SPN" SG_ 2566834942 SPNConversionMethod1 1706;
BA_ "SPN" SG_ 2566834942 OccurenceCount1 1216;
BA_ "SPN" SG_ 2566834942 SPN1High 1214;
BA_ "SPN" SG_ 2566834942 FailureModeIdentifier1 1215;
BA_ "SPN" SG_ 2566834942 FlashMalfuncIndicatorLamp 3038;
BA_ "SPN" SG_ 2566834942 FlashRedStopLamp 3039;
BA_ "SPN" SG_ 2566834942 FlashAmberWarningLamp 3040;
BA_ "SPN" SG_ 2566834942 FlashProtectLamp 3041;
BA_ "SPN" SG_ 2566834942 MalfunctionIndicatorLampStatus 1213;
BA_ "SPN" SG_ 2566834942 RedStopLampState 623;
BA_ "SPN" SG_ 2566834942 AmberWarningLampStatus 624;
BA_ "SPN" SG_ 2566834942 ProtectLampStatus 987;
BA_ "GenSigStartValue" SG_ 2566880305 AmbientAirTemp 100;
BA_ "GenSigStartValue" SG_ 2566851111 EngineCoolantTemp 40;
BA_ "SPN" SG_ 2566832622 HighResolutionTripDistance 918;
BA_ "SPN" SG_ 2566832622 HghReslutionTotalVehicleDistance 917;
BA_ "SPN" SG_ 2566842094 LocalMinuteOffset 1601;
BA_ "SPN" SG_ 2566842094 LocalHourOffset 1602;
BA_ "SPN" SG_ 2566842094 Year 964;
BA_ "SPN" SG_ 2566842094 Day 962;
BA_ "SPN" SG_ 2566842094 Month 963;
BA_ "SPN" SG_ 2566842094 Hours 961;
BA_ "SPN" SG_ 2566842094 Minutes 960;
BA_ "SPN" SG_ 2566842094 Seconds 959;
BA_ "SPN" SG_ 2365484270 DirectionIndicator 1619;
BA_ "SPN" SG_ 2365484270 HandlingInformation 1621;
BA_ "SPN" SG_ 2365484270 SystemEvent 1622;
BA_ "SPN" SG_ 2365484270 Overspeed 1614;
BA_ "SPN" SG_ 2365484270 TachographVehicleSpeed 1624;
BA_ "SPN" SG_ 2365484270 TachographPerformance 1620;
BA_ "SPN" SG_ 2365484270 TachographOutputShaftSpeed 1623;
BA_ "SPN" SG_ 2365484270 DriveRecognize 1611;
BA_ "SPN" SG_ 2365484270 DriverCardDriver2 1616;
BA_ "SPN" SG_ 2365484270 DriverCardDriver1 1615;
BA_ "SPN" SG_ 2365484270 Driver2WorkingState 1613;
BA_ "SPN" SG_ 2365484270 Driver2TimeRelatedStates 1618;
BA_ "SPN" SG_ 2365484270 Driver1WorkingState 1612;
BA_ "SPN" SG_ 2365484270 Driver1TimeRelatedStates 1617;
VAL_ 2566834735 FailureModeIdentifier5 31 "Not available" 19 "Received network data in error" 18 "Below normal (moderatels severe)" 17 "Below normal (least severe)" 16 "Above normal (moderately severe)" 15 "Above normal (least severe)" 14 "Special intstructions" 13 "Out of calibration" 12 "Bad intelligent device" 11 "Root cause not known" 10 "Abnormal rate of change" 9 "Abnormal update rate" 8 "Abnormal frequency" 7 "Mechanical system not responding" 6 "Current above normal" 5 "Current below normal" 4 "Voltage below normal" 3 "Voltage above normal" 2 "Data erratic" 1 "Below normal (most severe)" 0 "Above normal (most severe)" ;
VAL_ 2566834735 FailureModeIdentifier4 31 "Not available" 19 "Received network data in error" 18 "Below normal (moderatels severe)" 17 "Below normal (least severe)" 16 "Above normal (moderately severe)" 15 "Above normal (least severe)" 14 "Special intstructions" 13 "Out of calibration" 12 "Bad intelligent device" 11 "Root cause not known" 10 "Abnormal rate of change" 9 "Abnormal update rate" 8 "Abnormal frequency" 7 "Mechanical system not responding" 6 "Current above normal" 5 "Current below normal" 4 "Voltage below normal" 3 "Voltage above normal" 2 "Data erratic" 1 "Below normal (most severe)" 0 "Above normal (most severe)" ;
VAL_ 2566834735 FailureModeIdentifier3 31 "Not available" 19 "Received network data in error" 18 "Below normal (moderatels severe)" 17 "Below normal (least severe)" 16 "Above normal (moderately severe)" 15 "Above normal (least severe)" 14 "Special intstructions" 13 "Out of calibration" 12 "Bad intelligent device" 11 "Root cause not known" 10 "Abnormal rate of change" 9 "Abnormal update rate" 8 "Abnormal frequency" 7 "Mechanical system not responding" 6 "Current above normal" 5 "Current below normal" 4 "Voltage below normal" 3 "Voltage above normal" 2 "Data erratic" 1 "Below normal (most severe)" 0 "Above normal (most severe)" ;
VAL_ 2566834735 FailureModeIdentifier2 31 "Not available" 19 "Received network data in error" 18 "Below normal (moderatels severe)" 17 "Below normal (least severe)" 16 "Above normal (moderately severe)" 15 "Above normal (least severe)" 14 "Special intstructions" 13 "Out of calibration" 12 "Bad intelligent device" 11 "Root cause not known" 10 "Abnormal rate of change" 9 "Abnormal update rate" 8 "Abnormal frequency" 7 "Mechanical system not responding" 6 "Current above normal" 5 "Current below normal" 4 "Voltage below normal" 3 "Voltage above normal" 2 "Data erratic" 1 "Below normal (most severe)" 0 "Above normal (most severe)" ;
VAL_ 2566834735 FailureModeIdentifier1 31 "Not available" 19 "Received network data in error" 18 "Below normal (moderatels severe)" 17 "Below normal (least severe)" 16 "Above normal (moderately severe)" 15 "Above normal (least severe)" 14 "Special intstructions" 13 "Out of calibration" 12 "Bad intelligent device" 11 "Root cause not known" 10 "Abnormal rate of change" 9 "Abnormal update rate" 8 "Abnormal frequency" 7 "Mechanical system not responding" 6 "Current above normal" 5 "Current below normal" 4 "Voltage below normal" 3 "Voltage above normal" 2 "Data erratic" 1 "Below normal (most severe)" 0 "Above normal (most severe)" ;
VAL_ 2566834735 FlashMalfuncIndicatorLamp 3 "Unavailable / Do Not Flash" 2 "Reserved" 1 "Fast Flash" 0 "Slow Flash" ;
VAL_ 2566834735 FlashRedStopLamp 3 "Unavailable / Do Not Flash" 2 "Reserved" 1 "Fast Flash" 0 "Slow Flash" ;
VAL_ 2566834735 FlashAmberWarningLamp 3 "Unavailable / Do Not Flash" 2 "Reserved" 1 "Fast Flash" 0 "Slow Flash" ;
VAL_ 2566834735 FlashProtectLamp 3 "Unavailable / Do Not Flash" 2 "Reserved" 1 "Fast Flash" 0 "Slow Flash" ;
VAL_ 2566834735 MalfunctionIndicatorLampStatus 3 "Not available" 2 "Reserved" 1 "Lamp on" 0 "Lamp off" ;
VAL_ 2566834735 RedStopLampState 3 "Not available" 2 "Reserved" 1 "Lamp on" 0 "Lamp off" ;
VAL_ 2566834735 AmberWarningLampStatus 3 "Not available" 2 "Reserved" 1 "Lamp on" 0 "Lamp off" ;
VAL_ 2566834735 ProtectLampStatus 3 "Not available" 2 "Reserved" 1 "Lamp on" 0 "Lamp off" ;
VAL_ 2566834699 FailureModeIdentifier5 31 "Not available" 19 "Received network data in error" 18 "Below normal (moderatels severe)" 17 "Below normal (least severe)" 16 "Above normal (moderately severe)" 15 "Above normal (least severe)" 14 "Special intstructions" 13 "Out of calibration" 12 "Bad intelligent device" 11 "Root cause not known" 10 "Abnormal rate of change" 9 "Abnormal update rate" 8 "Abnormal frequency" 7 "Mechanical system not responding" 6 "Current above normal" 5 "Current below normal" 4 "Voltage below normal" 3 "Voltage above normal" 2 "Data erratic" 1 "Below normal (most severe)" 0 "Above normal (most severe)" ;
VAL_ 2566834699 FailureModeIdentifier4 31 "Not available" 19 "Received network data in error" 18 "Below normal (moderatels severe)" 17 "Below normal (least severe)" 16 "Above normal (moderately severe)" 15 "Above normal (least severe)" 14 "Special intstructions" 13 "Out of calibration" 12 "Bad intelligent device" 11 "Root cause not known" 10 "Abnormal rate of change" 9 "Abnormal update rate" 8 "Abnormal frequency" 7 "Mechanical system not responding" 6 "Current above normal" 5 "Current below normal" 4 "Voltage below normal" 3 "Voltage above normal" 2 "Data erratic" 1 "Below normal (most severe)" 0 "Above normal (most severe)" ;
VAL_ 2566834699 FailureModeIdentifier3 31 "Not available" 19 "Received network data in error" 18 "Below normal (moderatels severe)" 17 "Below normal (least severe)" 16 "Above normal (moderately severe)" 15 "Above normal (least severe)" 14 "Special intstructions" 13 "Out of calibration" 12 "Bad intelligent device" 11 "Root cause not known" 10 "Abnormal rate of change" 9 "Abnormal update rate" 8 "Abnormal frequency" 7 "Mechanical system not responding" 6 "Current above normal" 5 "Current below normal" 4 "Voltage below normal" 3 "Voltage above normal" 2 "Data erratic" 1 "Below normal (most severe)" 0 "Above normal (most severe)" ;
VAL_ 2566834699 FailureModeIdentifier2 31 "Not available" 19 "Received network data in error" 18 "Below normal (moderatels severe)" 17 "Below normal (least severe)" 16 "Above normal (moderately severe)" 15 "Above normal (least severe)" 14 "Special intstructions" 13 "Out of calibration" 12 "Bad intelligent device" 11 "Root cause not known" 10 "Abnormal rate of change" 9 "Abnormal update rate" 8 "Abnormal frequency" 7 "Mechanical system not responding" 6 "Current above normal" 5 "Current below normal" 4 "Voltage below normal" 3 "Voltage above normal" 2 "Data erratic" 1 "Below normal (most severe)" 0 "Above normal (most severe)" ;
VAL_ 2566834699 FailureModeIdentifier1 31 "Not available" 19 "Received network data in error" 18 "Below normal (moderatels severe)" 17 "Below normal (least severe)" 16 "Above normal (moderately severe)" 15 "Above normal (least severe)" 14 "Special intstructions" 13 "Out of calibration" 12 "Bad intelligent device" 11 "Root cause not known" 10 "Abnormal rate of change" 9 "Abnormal update rate" 8 "Abnormal frequency" 7 "Mechanical system not responding" 6 "Current above normal" 5 "Current below normal" 4 "Voltage below normal" 3 "Voltage above normal" 2 "Data erratic" 1 "Below normal (most severe)" 0 "Above normal (most severe)" ;
VAL_ 2566834699 FlashMalfuncIndicatorLamp 3 "Unavailable / Do Not Flash" 2 "Reserved" 1 "Fast Flash" 0 "Slow Flash" ;
VAL_ 2566834699 FlashRedStopLamp 3 "Unavailable / Do Not Flash" 2 "Reserved" 1 "Fast Flash" 0 "Slow Flash" ;
VAL_ 2566834699 FlashAmberWarningLamp 3 "Unavailable / Do Not Flash" 2 "Reserved" 1 "Fast Flash" 0 "Slow Flash" ;
VAL_ 2566834699 FlashProtectLamp 3 "Unavailable / Do Not Flash" 2 "Reserved" 1 "Fast Flash" 0 "Slow Flash" ;
VAL_ 2566834699 MalfunctionIndicatorLampStatus 3 "Not available" 2 "Reserved" 1 "Lamp on" 0 "Lamp off" ;
VAL_ 2566834699 RedStopLampState 3 "Not available" 2 "Reserved" 1 "Lamp on" 0 "Lamp off" ;
VAL_ 2566834699 AmberWarningLampStatus 3 "Not available" 2 "Reserved" 1 "Lamp on" 0 "Lamp off" ;
VAL_ 2566834699 ProtectLampStatus 3 "Not available" 2 "Reserved" 1 "Lamp on" 0 "Lamp off" ;
VAL_ 2566834816 FailureModeIdentifier5 31 "Not available" 19 "Received network data in error" 18 "Below normal (moderatels severe)" 17 "Below normal (least severe)" 16 "Above normal (moderately severe)" 15 "Above normal (least severe)" 14 "Special intstructions" 13 "Out of calibration" 12 "Bad intelligent device" 11 "Root cause not known" 10 "Abnormal rate of change" 9 "Abnormal update rate" 8 "Abnormal frequency" 7 "Mechanical system not responding" 6 "Current above normal" 5 "Current below normal" 4 "Voltage below normal" 3 "Voltage above normal" 2 "Data erratic" 1 "Below normal (most severe)" 0 "Above normal (most severe)" ;
VAL_ 2566834816 FailureModeIdentifier4 31 "Not available" 19 "Received network data in error" 18 "Below normal (moderatels severe)" 17 "Below normal (least severe)" 16 "Above normal (moderately severe)" 15 "Above normal (least severe)" 14 "Special intstructions" 13 "Out of calibration" 12 "Bad intelligent device" 11 "Root cause not known" 10 "Abnormal rate of change" 9 "Abnormal update rate" 8 "Abnormal frequency" 7 "Mechanical system not responding" 6 "Current above normal" 5 "Current below normal" 4 "Voltage below normal" 3 "Voltage above normal" 2 "Data erratic" 1 "Below normal (most severe)" 0 "Above normal (most severe)" ;
VAL_ 2566834816 FailureModeIdentifier3 31 "Not available" 19 "Received network data in error" 18 "Below normal (moderatels severe)" 17 "Below normal (least severe)" 16 "Above normal (moderately severe)" 15 "Above normal (least severe)" 14 "Special intstructions" 13 "Out of calibration" 12 "Bad intelligent device" 11 "Root cause not known" 10 "Abnormal rate of change" 9 "Abnormal update rate" 8 "Abnormal frequency" 7 "Mechanical system not responding" 6 "Current above normal" 5 "Current below normal" 4 "Voltage below normal" 3 "Voltage above normal" 2 "Data erratic" 1 "Below normal (most severe)" 0 "Above normal (most severe)" ;
VAL_ 2566834816 FailureModeIdentifier2 31 "Not available" 19 "Received network data in error" 18 "Below normal (moderatels severe)" 17 "Below normal (least severe)" 16 "Above normal (moderately severe)" 15 "Above normal (least severe)" 14 "Special intstructions" 13 "Out of calibration" 12 "Bad intelligent device" 11 "Root cause not known" 10 "Abnormal rate of change" 9 "Abnormal update rate" 8 "Abnormal frequency" 7 "Mechanical system not responding" 6 "Current above normal" 5 "Current below normal" 4 "Voltage below normal" 3 "Voltage above normal" 2 "Data erratic" 1 "Below normal (most severe)" 0 "Above normal (most severe)" ;
VAL_ 2566834816 FailureModeIdentifier1 31 "Not available" 19 "Received network data in error" 18 "Below normal (moderatels severe)" 17 "Below normal (least severe)" 16 "Above normal (moderately severe)" 15 "Above normal (least severe)" 14 "Special intstructions" 13 "Out of calibration" 12 "Bad intelligent device" 11 "Root cause not known" 10 "Abnormal rate of change" 9 "Abnormal update rate" 8 "Abnormal frequency" 7 "Mechanical system not responding" 6 "Current above normal" 5 "Current below normal" 4 "Voltage below normal" 3 "Voltage above normal" 2 "Data erratic" 1 "Below normal (most severe)" 0 "Above normal (most severe)" ;
VAL_ 2566834816 FlashMalfuncIndicatorLamp 3 "Unavailable / Do Not Flash" 2 "Reserved" 1 "Fast Flash" 0 "Slow Flash" ;
VAL_ 2566834816 FlashRedStopLamp 3 "Unavailable / Do Not Flash" 2 "Reserved" 1 "Fast Flash" 0 "Slow Flash" ;
VAL_ 2566834816 FlashAmberWarningLamp 3 "Unavailable / Do Not Flash" 2 "Reserved" 1 "Fast Flash" 0 "Slow Flash" ;
VAL_ 2566834816 FlashProtectLamp 3 "Unavailable / Do Not Flash" 2 "Reserved" 1 "Fast Flash" 0 "Slow Flash" ;
VAL_ 2566834816 MalfunctionIndicatorLampStatus 3 "Not available" 2 "Reserved" 1 "Lamp on" 0 "Lamp off" ;
VAL_ 2566834816 RedStopLampState 3 "Not available" 2 "Reserved" 1 "Lamp on" 0 "Lamp off" ;
VAL_ 2566834816 AmberWarningLampStatus 3 "Not available" 2 "Reserved" 1 "Lamp on" 0 "Lamp off" ;
VAL_ 2566834816 ProtectLampStatus 3 "Not available" 2 "Reserved" 1 "Lamp on" 0 "Lamp off" ;
VAL_ 2566834688 FailureModeIdentifier5 31 "Not available" 19 "Received network data in error" 18 "Below normal (moderatels severe)" 17 "Below normal (least severe)" 16 "Above normal (moderately severe)" 15 "Above normal (least severe)" 14 "Special intstructions" 13 "Out of calibration" 12 "Bad intelligent device" 11 "Root cause not known" 10 "Abnormal rate of change" 9 "Abnormal update rate" 8 "Abnormal frequency" 7 "Mechanical system not responding" 6 "Current above normal" 5 "Current below normal" 4 "Voltage below normal" 3 "Voltage above normal" 2 "Data erratic" 1 "Below normal (most severe)" 0 "Above normal (most severe)" ;
VAL_ 2566834688 FailureModeIdentifier4 31 "Not available" 19 "Received network data in error" 18 "Below normal (moderatels severe)" 17 "Below normal (least severe)" 16 "Above normal (moderately severe)" 15 "Above normal (least severe)" 14 "Special intstructions" 13 "Out of calibration" 12 "Bad intelligent device" 11 "Root cause not known" 10 "Abnormal rate of change" 9 "Abnormal update rate" 8 "Abnormal frequency" 7 "Mechanical system not responding" 6 "Current above normal" 5 "Current below normal" 4 "Voltage below normal" 3 "Voltage above normal" 2 "Data erratic" 1 "Below normal (most severe)" 0 "Above normal (most severe)" ;
VAL_ 2566834688 FailureModeIdentifier3 31 "Not available" 19 "Received network data in error" 18 "Below normal (moderatels severe)" 17 "Below normal (least severe)" 16 "Above normal (moderately severe)" 15 "Above normal (least severe)" 14 "Special intstructions" 13 "Out of calibration" 12 "Bad intelligent device" 11 "Root cause not known" 10 "Abnormal rate of change" 9 "Abnormal update rate" 8 "Abnormal frequency" 7 "Mechanical system not responding" 6 "Current above normal" 5 "Current below normal" 4 "Voltage below normal" 3 "Voltage above normal" 2 "Data erratic" 1 "Below normal (most severe)" 0 "Above normal (most severe)" ;
VAL_ 2566834688 FailureModeIdentifier2 31 "Not available" 19 "Received network data in error" 18 "Below normal (moderatels severe)" 17 "Below normal (least severe)" 16 "Above normal (moderately severe)" 15 "Above normal (least severe)" 14 "Special intstructions" 13 "Out of calibration" 12 "Bad intelligent device" 11 "Root cause not known" 10 "Abnormal rate of change" 9 "Abnormal update rate" 8 "Abnormal frequency" 7 "Mechanical system not responding" 6 "Current above normal" 5 "Current below normal" 4 "Voltage below normal" 3 "Voltage above normal" 2 "Data erratic" 1 "Below normal (most severe)" 0 "Above normal (most severe)" ;
VAL_ 2566834688 FailureModeIdentifier1 31 "Not available" 19 "Received network data in error" 18 "Below normal (moderatels severe)" 17 "Below normal (least severe)" 16 "Above normal (moderately severe)" 15 "Above normal (least severe)" 14 "Special intstructions" 13 "Out of calibration" 12 "Bad intelligent device" 11 "Root cause not known" 10 "Abnormal rate of change" 9 "Abnormal update rate" 8 "Abnormal frequency" 7 "Mechanical system not responding" 6 "Current above normal" 5 "Current below normal" 4 "Voltage below normal" 3 "Voltage above normal" 2 "Data erratic" 1 "Below normal (most severe)" 0 "Above normal (most severe)" ;
VAL_ 2566834688 FlashMalfuncIndicatorLamp 3 "Unavailable / Do Not Flash" 2 "Reserved" 1 "Fast Flash" 0 "Slow Flash" ;
VAL_ 2566834688 FlashRedStopLamp 3 "Unavailable / Do Not Flash" 2 "Reserved" 1 "Fast Flash" 0 "Slow Flash" ;
VAL_ 2566834688 FlashAmberWarningLamp 3 "Unavailable / Do Not Flash" 2 "Reserved" 1 "Fast Flash" 0 "Slow Flash" ;
VAL_ 2566834688 FlashProtectLamp 3 "Unavailable / Do Not Flash" 2 "Reserved" 1 "Fast Flash" 0 "Slow Flash" ;
VAL_ 2566834688 MalfunctionIndicatorLampStatus 3 "Not available" 2 "Reserved" 1 "Lamp on" 0 "Lamp off" ;
VAL_ 2566834688 RedStopLampState 3 "Not available" 2 "Reserved" 1 "Lamp on" 0 "Lamp off" ;
VAL_ 2566834688 AmberWarningLampStatus 3 "Not available" 2 "Reserved" 1 "Lamp on" 0 "Lamp off" ;
VAL_ 2566834688 ProtectLampStatus 3 "Not available" 2 "Reserved" 1 "Lamp on" 0 "Lamp off" ;
VAL_ 2566834927 FailureModeIdentifier5 31 "Not available" 19 "Received network data in error" 18 "Below normal (moderatels severe)" 17 "Below normal (least severe)" 16 "Above normal (moderately severe)" 15 "Above normal (least severe)" 14 "Special intstructions" 13 "Out of calibration" 12 "Bad intelligent device" 11 "Root cause not known" 10 "Abnormal rate of change" 9 "Abnormal update rate" 8 "Abnormal frequency" 7 "Mechanical system not responding" 6 "Current above normal" 5 "Current below normal" 4 "Voltage below normal" 3 "Voltage above normal" 2 "Data erratic" 1 "Below normal (most severe)" 0 "Above normal (most severe)" ;
VAL_ 2566834927 FailureModeIdentifier4 31 "Not available" 19 "Received network data in error" 18 "Below normal (moderatels severe)" 17 "Below normal (least severe)" 16 "Above normal (moderately severe)" 15 "Above normal (least severe)" 14 "Special intstructions" 13 "Out of calibration" 12 "Bad intelligent device" 11 "Root cause not known" 10 "Abnormal rate of change" 9 "Abnormal update rate" 8 "Abnormal frequency" 7 "Mechanical system not responding" 6 "Current above normal" 5 "Current below normal" 4 "Voltage below normal" 3 "Voltage above normal" 2 "Data erratic" 1 "Below normal (most severe)" 0 "Above normal (most severe)" ;
VAL_ 2566834927 FailureModeIdentifier3 31 "Not available" 19 "Received network data in error" 18 "Below normal (moderatels severe)" 17 "Below normal (least severe)" 16 "Above normal (moderately severe)" 15 "Above normal (least severe)" 14 "Special intstructions" 13 "Out of calibration" 12 "Bad intelligent device" 11 "Root cause not known" 10 "Abnormal rate of change" 9 "Abnormal update rate" 8 "Abnormal frequency" 7 "Mechanical system not responding" 6 "Current above normal" 5 "Current below normal" 4 "Voltage below normal" 3 "Voltage above normal" 2 "Data erratic" 1 "Below normal (most severe)" 0 "Above normal (most severe)" ;
VAL_ 2566834927 FailureModeIdentifier2 31 "Not available" 19 "Received network data in error" 18 "Below normal (moderatels severe)" 17 "Below normal (least severe)" 16 "Above normal (moderately severe)" 15 "Above normal (least severe)" 14 "Special intstructions" 13 "Out of calibration" 12 "Bad intelligent device" 11 "Root cause not known" 10 "Abnormal rate of change" 9 "Abnormal update rate" 8 "Abnormal frequency" 7 "Mechanical system not responding" 6 "Current above normal" 5 "Current below normal" 4 "Voltage below normal" 3 "Voltage above normal" 2 "Data erratic" 1 "Below normal (most severe)" 0 "Above normal (most severe)" ;
VAL_ 2566834927 FailureModeIdentifier1 31 "Not available" 19 "Received network data in error" 18 "Below normal (moderatels severe)" 17 "Below normal (least severe)" 16 "Above normal (moderately severe)" 15 "Above normal (least severe)" 14 "Special intstructions" 13 "Out of calibration" 12 "Bad intelligent device" 11 "Root cause not known" 10 "Abnormal rate of change" 9 "Abnormal update rate" 8 "Abnormal frequency" 7 "Mechanical system not responding" 6 "Current above normal" 5 "Current below normal" 4 "Voltage below normal" 3 "Voltage above normal" 2 "Data erratic" 1 "Below normal (most severe)" 0 "Above normal (most severe)" ;
VAL_ 2566834927 FlashMalfuncIndicatorLamp 3 "Unavailable / Do Not Flash" 2 "Reserved" 1 "Fast Flash" 0 "Slow Flash" ;
VAL_ 2566834927 FlashRedStopLamp 3 "Unavailable / Do Not Flash" 2 "Reserved" 1 "Fast Flash" 0 "Slow Flash" ;
VAL_ 2566834927 FlashAmberWarningLamp 3 "Unavailable / Do Not Flash" 2 "Reserved" 1 "Fast Flash" 0 "Slow Flash" ;
VAL_ 2566834927 FlashProtectLamp 3 "Unavailable / Do Not Flash" 2 "Reserved" 1 "Fast Flash" 0 "Slow Flash" ;
VAL_ 2566834927 MalfunctionIndicatorLampStatus 3 "Not available" 2 "Reserved" 1 "Lamp on" 0 "Lamp off" ;
VAL_ 2566834927 RedStopLampState 3 "Not available" 2 "Reserved" 1 "Lamp on" 0 "Lamp off" ;
VAL_ 2566834927 AmberWarningLampStatus 3 "Not available" 2 "Reserved" 1 "Lamp on" 0 "Lamp off" ;
VAL_ 2566834927 ProtectLampStatus 3 "Not available" 2 "Reserved" 1 "Lamp on" 0 "Lamp off" ;
VAL_ 2566834737 FailureModeIdentifier5 31 "Not available" 19 "Received network data in error" 18 "Below normal (moderatels severe)" 17 "Below normal (least severe)" 16 "Above normal (moderately severe)" 15 "Above normal (least severe)" 14 "Special intstructions" 13 "Out of calibration" 12 "Bad intelligent device" 11 "Root cause not known" 10 "Abnormal rate of change" 9 "Abnormal update rate" 8 "Abnormal frequency" 7 "Mechanical system not responding" 6 "Current above normal" 5 "Current below normal" 4 "Voltage below normal" 3 "Voltage above normal" 2 "Data erratic" 1 "Below normal (most severe)" 0 "Above normal (most severe)" ;
VAL_ 2566834737 FailureModeIdentifier4 31 "Not available" 19 "Received network data in error" 18 "Below normal (moderatels severe)" 17 "Below normal (least severe)" 16 "Above normal (moderately severe)" 15 "Above normal (least severe)" 14 "Special intstructions" 13 "Out of calibration" 12 "Bad intelligent device" 11 "Root cause not known" 10 "Abnormal rate of change" 9 "Abnormal update rate" 8 "Abnormal frequency" 7 "Mechanical system not responding" 6 "Current above normal" 5 "Current below normal" 4 "Voltage below normal" 3 "Voltage above normal" 2 "Data erratic" 1 "Below normal (most severe)" 0 "Above normal (most severe)" ;
VAL_ 2566834737 FailureModeIdentifier3 31 "Not available" 19 "Received network data in error" 18 "Below normal (moderatels severe)" 17 "Below normal (least severe)" 16 "Above normal (moderately severe)" 15 "Above normal (least severe)" 14 "Special intstructions" 13 "Out of calibration" 12 "Bad intelligent device" 11 "Root cause not known" 10 "Abnormal rate of change" 9 "Abnormal update rate" 8 "Abnormal frequency" 7 "Mechanical system not responding" 6 "Current above normal" 5 "Current below normal" 4 "Voltage below normal" 3 "Voltage above normal" 2 "Data erratic" 1 "Below normal (most severe)" 0 "Above normal (most severe)" ;
VAL_ 2566834737 FailureModeIdentifier2 31 "Not available" 19 "Received network data in error" 18 "Below normal (moderatels severe)" 17 "Below normal (least severe)" 16 "Above normal (moderately severe)" 15 "Above normal (least severe)" 14 "Special intstructions" 13 "Out of calibration" 12 "Bad intelligent device" 11 "Root cause not known" 10 "Abnormal rate of change" 9 "Abnormal update rate" 8 "Abnormal frequency" 7 "Mechanical system not responding" 6 "Current above normal" 5 "Current below normal" 4 "Voltage below normal" 3 "Voltage above normal" 2 "Data erratic" 1 "Below normal (most severe)" 0 "Above normal (most severe)" ;
VAL_ 2566834737 FailureModeIdentifier1 31 "Not available" 19 "Received network data in error" 18 "Below normal (moderatels severe)" 17 "Below normal (least severe)" 16 "Above normal (moderately severe)" 15 "Above normal (least severe)" 14 "Special intstructions" 13 "Out of calibration" 12 "Bad intelligent device" 11 "Root cause not known" 10 "Abnormal rate of change" 9 "Abnormal update rate" 8 "Abnormal frequency" 7 "Mechanical system not responding" 6 "Current above normal" 5 "Current below normal" 4 "Voltage below normal" 3 "Voltage above normal" 2 "Data erratic" 1 "Below normal (most severe)" 0 "Above normal (most severe)" ;
VAL_ 2566834737 FlashMalfuncIndicatorLamp 3 "Unavailable / Do Not Flash" 2 "Reserved" 1 "Fast Flash" 0 "Slow Flash" ;
VAL_ 2566834737 FlashRedStopLamp 3 "Unavailable / Do Not Flash" 2 "Reserved" 1 "Fast Flash" 0 "Slow Flash" ;
VAL_ 2566834737 FlashAmberWarningLamp 3 "Unavailable / Do Not Flash" 2 "Reserved" 1 "Fast Flash" 0 "Slow Flash" ;
VAL_ 2566834737 FlashProtectLamp 3 "Unavailable / Do Not Flash" 2 "Reserved" 1 "Fast Flash" 0 "Slow Flash" ;
VAL_ 2566834737 MalfunctionIndicatorLampStatus 3 "Not available" 2 "Reserved" 1 "Lamp on" 0 "Lamp off" ;
VAL_ 2566834737 RedStopLampState 3 "Not available" 2 "Reserved" 1 "Lamp on" 0 "Lamp off" ;
VAL_ 2566834737 AmberWarningLampStatus 3 "Not available" 2 "Reserved" 1 "Lamp on" 0 "Lamp off" ;
VAL_ 2566834737 ProtectLampStatus 3 "Not available" 2 "Reserved" 1 "Lamp on" 0 "Lamp off" ;
VAL_ 2566834760 FailureModeIdentifier5 31 "Not available" 19 "Received network data in error" 18 "Below normal (moderatels severe)" 17 "Below normal (least severe)" 16 "Above normal (moderately severe)" 15 "Above normal (least severe)" 14 "Special intstructions" 13 "Out of calibration" 12 "Bad intelligent device" 11 "Root cause not known" 10 "Abnormal rate of change" 9 "Abnormal update rate" 8 "Abnormal frequency" 7 "Mechanical system not responding" 6 "Current above normal" 5 "Current below normal" 4 "Voltage below normal" 3 "Voltage above normal" 2 "Data erratic" 1 "Below normal (most severe)" 0 "Above normal (most severe)" ;
VAL_ 2566834760 FailureModeIdentifier4 31 "Not available" 19 "Received network data in error" 18 "Below normal (moderatels severe)" 17 "Below normal (least severe)" 16 "Above normal (moderately severe)" 15 "Above normal (least severe)" 14 "Special intstructions" 13 "Out of calibration" 12 "Bad intelligent device" 11 "Root cause not known" 10 "Abnormal rate of change" 9 "Abnormal update rate" 8 "Abnormal frequency" 7 "Mechanical system not responding" 6 "Current above normal" 5 "Current below normal" 4 "Voltage below normal" 3 "Voltage above normal" 2 "Data erratic" 1 "Below normal (most severe)" 0 "Above normal (most severe)" ;
VAL_ 2566834760 FailureModeIdentifier3 31 "Not available" 19 "Received network data in error" 18 "Below normal (moderatels severe)" 17 "Below normal (least severe)" 16 "Above normal (moderately severe)" 15 "Above normal (least severe)" 14 "Special intstructions" 13 "Out of calibration" 12 "Bad intelligent device" 11 "Root cause not known" 10 "Abnormal rate of change" 9 "Abnormal update rate" 8 "Abnormal frequency" 7 "Mechanical system not responding" 6 "Current above normal" 5 "Current below normal" 4 "Voltage below normal" 3 "Voltage above normal" 2 "Data erratic" 1 "Below normal (most severe)" 0 "Above normal (most severe)" ;
VAL_ 2566834760 FailureModeIdentifier2 31 "Not available" 19 "Received network data in error" 18 "Below normal (moderatels severe)" 17 "Below normal (least severe)" 16 "Above normal (moderately severe)" 15 "Above normal (least severe)" 14 "Special intstructions" 13 "Out of calibration" 12 "Bad intelligent device" 11 "Root cause not known" 10 "Abnormal rate of change" 9 "Abnormal update rate" 8 "Abnormal frequency" 7 "Mechanical system not responding" 6 "Current above normal" 5 "Current below normal" 4 "Voltage below normal" 3 "Voltage above normal" 2 "Data erratic" 1 "Below normal (most severe)" 0 "Above normal (most severe)" ;
VAL_ 2566834760 FailureModeIdentifier1 31 "Not available" 19 "Received network data in error" 18 "Below normal (moderatels severe)" 17 "Below normal (least severe)" 16 "Above normal (moderately severe)" 15 "Above normal (least severe)" 14 "Special intstructions" 13 "Out of calibration" 12 "Bad intelligent device" 11 "Root cause not known" 10 "Abnormal rate of change" 9 "Abnormal update rate" 8 "Abnormal frequency" 7 "Mechanical system not responding" 6 "Current above normal" 5 "Current below normal" 4 "Voltage below normal" 3 "Voltage above normal" 2 "Data erratic" 1 "Below normal (most severe)" 0 "Above normal (most severe)" ;
VAL_ 2566834760 FlashMalfuncIndicatorLamp 3 "Unavailable / Do Not Flash" 2 "Reserved" 1 "Fast Flash" 0 "Slow Flash" ;
VAL_ 2566834760 FlashRedStopLamp 3 "Unavailable / Do Not Flash" 2 "Reserved" 1 "Fast Flash" 0 "Slow Flash" ;
VAL_ 2566834760 FlashAmberWarningLamp 3 "Unavailable / Do Not Flash" 2 "Reserved" 1 "Fast Flash" 0 "Slow Flash" ;
VAL_ 2566834760 FlashProtectLamp 3 "Unavailable / Do Not Flash" 2 "Reserved" 1 "Fast Flash" 0 "Slow Flash" ;
VAL_ 2566834760 MalfunctionIndicatorLampStatus 3 "Not available" 2 "Reserved" 1 "Lamp on" 0 "Lamp off" ;
VAL_ 2566834760 RedStopLampState 3 "Not available" 2 "Reserved" 1 "Lamp on" 0 "Lamp off" ;
VAL_ 2566834760 AmberWarningLampStatus 3 "Not available" 2 "Reserved" 1 "Lamp on" 0 "Lamp off" ;
VAL_ 2566834760 ProtectLampStatus 3 "Not available" 2 "Reserved" 1 "Lamp on" 0 "Lamp off" ;
VAL_ 2566834727 FailureModeIdentifier5 31 "Not available" 19 "Received network data in error" 18 "Below normal (moderatels severe)" 17 "Below normal (least severe)" 16 "Above normal (moderately severe)" 15 "Above normal (least severe)" 14 "Special intstructions" 13 "Out of calibration" 12 "Bad intelligent device" 11 "Root cause not known" 10 "Abnormal rate of change" 9 "Abnormal update rate" 8 "Abnormal frequency" 7 "Mechanical system not responding" 6 "Current above normal" 5 "Current below normal" 4 "Voltage below normal" 3 "Voltage above normal" 2 "Data erratic" 1 "Below normal (most severe)" 0 "Above normal (most severe)" ;
VAL_ 2566834727 FailureModeIdentifier4 31 "Not available" 19 "Received network data in error" 18 "Below normal (moderatels severe)" 17 "Below normal (least severe)" 16 "Above normal (moderately severe)" 15 "Above normal (least severe)" 14 "Special intstructions" 13 "Out of calibration" 12 "Bad intelligent device" 11 "Root cause not known" 10 "Abnormal rate of change" 9 "Abnormal update rate" 8 "Abnormal frequency" 7 "Mechanical system not responding" 6 "Current above normal" 5 "Current below normal" 4 "Voltage below normal" 3 "Voltage above normal" 2 "Data erratic" 1 "Below normal (most severe)" 0 "Above normal (most severe)" ;
VAL_ 2566834727 FailureModeIdentifier3 31 "Not available" 19 "Received network data in error" 18 "Below normal (moderatels severe)" 17 "Below normal (least severe)" 16 "Above normal (moderately severe)" 15 "Above normal (least severe)" 14 "Special intstructions" 13 "Out of calibration" 12 "Bad intelligent device" 11 "Root cause not known" 10 "Abnormal rate of change" 9 "Abnormal update rate" 8 "Abnormal frequency" 7 "Mechanical system not responding" 6 "Current above normal" 5 "Current below normal" 4 "Voltage below normal" 3 "Voltage above normal" 2 "Data erratic" 1 "Below normal (most severe)" 0 "Above normal (most severe)" ;
VAL_ 2566834727 FailureModeIdentifier2 31 "Not available" 19 "Received network data in error" 18 "Below normal (moderatels severe)" 17 "Below normal (least severe)" 16 "Above normal (moderately severe)" 15 "Above normal (least severe)" 14 "Special intstructions" 13 "Out of calibration" 12 "Bad intelligent device" 11 "Root cause not known" 10 "Abnormal rate of change" 9 "Abnormal update rate" 8 "Abnormal frequency" 7 "Mechanical system not responding" 6 "Current above normal" 5 "Current below normal" 4 "Voltage below normal" 3 "Voltage above normal" 2 "Data erratic" 1 "Below normal (most severe)" 0 "Above normal (most severe)" ;
VAL_ 2566834727 FailureModeIdentifier1 31 "Not available" 19 "Received network data in error" 18 "Below normal (moderatels severe)" 17 "Below normal (least severe)" 16 "Above normal (moderately severe)" 15 "Above normal (least severe)" 14 "Special intstructions" 13 "Out of calibration" 12 "Bad intelligent device" 11 "Root cause not known" 10 "Abnormal rate of change" 9 "Abnormal update rate" 8 "Abnormal frequency" 7 "Mechanical system not responding" 6 "Current above normal" 5 "Current below normal" 4 "Voltage below normal" 3 "Voltage above normal" 2 "Data erratic" 1 "Below normal (most severe)" 0 "Above normal (most severe)" ;
VAL_ 2566834727 FlashMalfuncIndicatorLamp 3 "Unavailable / Do Not Flash" 2 "Reserved" 1 "Fast Flash" 0 "Slow Flash" ;
VAL_ 2566834727 FlashRedStopLamp 3 "Unavailable / Do Not Flash" 2 "Reserved" 1 "Fast Flash" 0 "Slow Flash" ;
VAL_ 2566834727 FlashAmberWarningLamp 3 "Unavailable / Do Not Flash" 2 "Reserved" 1 "Fast Flash" 0 "Slow Flash" ;
VAL_ 2566834727 FlashProtectLamp 3 "Unavailable / Do Not Flash" 2 "Reserved" 1 "Fast Flash" 0 "Slow Flash" ;
VAL_ 2566834727 MalfunctionIndicatorLampStatus 3 "Not available" 2 "Reserved" 1 "Lamp on" 0 "Lamp off" ;
VAL_ 2566834727 RedStopLampState 3 "Not available" 2 "Reserved" 1 "Lamp on" 0 "Lamp off" ;
VAL_ 2566834727 AmberWarningLampStatus 3 "Not available" 2 "Reserved" 1 "Lamp on" 0 "Lamp off" ;
VAL_ 2566834727 ProtectLampStatus 3 "Not available" 2 "Reserved" 1 "Lamp on" 0 "Lamp off" ;
VAL_ 2566834926 FailureModeIdentifier5 31 "Not available" 19 "Received network data in error" 18 "Below normal (moderatels severe)" 17 "Below normal (least severe)" 16 "Above normal (moderately severe)" 15 "Above normal (least severe)" 14 "Special intstructions" 13 "Out of calibration" 12 "Bad intelligent device" 11 "Root cause not known" 10 "Abnormal rate of change" 9 "Abnormal update rate" 8 "Abnormal frequency" 7 "Mechanical system not responding" 6 "Current above normal" 5 "Current below normal" 4 "Voltage below normal" 3 "Voltage above normal" 2 "Data erratic" 1 "Below normal (most severe)" 0 "Above normal (most severe)" ;
VAL_ 2566834926 FailureModeIdentifier4 31 "Not available" 19 "Received network data in error" 18 "Below normal (moderatels severe)" 17 "Below normal (least severe)" 16 "Above normal (moderately severe)" 15 "Above normal (least severe)" 14 "Special intstructions" 13 "Out of calibration" 12 "Bad intelligent device" 11 "Root cause not known" 10 "Abnormal rate of change" 9 "Abnormal update rate" 8 "Abnormal frequency" 7 "Mechanical system not responding" 6 "Current above normal" 5 "Current below normal" 4 "Voltage below normal" 3 "Voltage above normal" 2 "Data erratic" 1 "Below normal (most severe)" 0 "Above normal (most severe)" ;
VAL_ 2566834926 FailureModeIdentifier3 31 "Not available" 19 "Received network data in error" 18 "Below normal (moderatels severe)" 17 "Below normal (least severe)" 16 "Above normal (moderately severe)" 15 "Above normal (least severe)" 14 "Special intstructions" 13 "Out of calibration" 12 "Bad intelligent device" 11 "Root cause not known" 10 "Abnormal rate of change" 9 "Abnormal update rate" 8 "Abnormal frequency" 7 "Mechanical system not responding" 6 "Current above normal" 5 "Current below normal" 4 "Voltage below normal" 3 "Voltage above normal" 2 "Data erratic" 1 "Below normal (most severe)" 0 "Above normal (most severe)" ;
VAL_ 2566834926 FailureModeIdentifier2 31 "Not available" 19 "Received network data in error" 18 "Below normal (moderatels severe)" 17 "Below normal (least severe)" 16 "Above normal (moderately severe)" 15 "Above normal (least severe)" 14 "Special intstructions" 13 "Out of calibration" 12 "Bad intelligent device" 11 "Root cause not known" 10 "Abnormal rate of change" 9 "Abnormal update rate" 8 "Abnormal frequency" 7 "Mechanical system not responding" 6 "Current above normal" 5 "Current below normal" 4 "Voltage below normal" 3 "Voltage above normal" 2 "Data erratic" 1 "Below normal (most severe)" 0 "Above normal (most severe)" ;
VAL_ 2566834926 FailureModeIdentifier1 31 "Not available" 19 "Received network data in error" 18 "Below normal (moderatels severe)" 17 "Below normal (least severe)" 16 "Above normal (moderately severe)" 15 "Above normal (least severe)" 14 "Special intstructions" 13 "Out of calibration" 12 "Bad intelligent device" 11 "Root cause not known" 10 "Abnormal rate of change" 9 "Abnormal update rate" 8 "Abnormal frequency" 7 "Mechanical system not responding" 6 "Current above normal" 5 "Current below normal" 4 "Voltage below normal" 3 "Voltage above normal" 2 "Data erratic" 1 "Below normal (most severe)" 0 "Above normal (most severe)" ;
VAL_ 2566834926 FlashMalfuncIndicatorLamp 3 "Unavailable / Do Not Flash" 2 "Reserved" 1 "Fast Flash" 0 "Slow Flash" ;
VAL_ 2566834926 FlashRedStopLamp 3 "Unavailable / Do Not Flash" 2 "Reserved" 1 "Fast Flash" 0 "Slow Flash" ;
VAL_ 2566834926 FlashAmberWarningLamp 3 "Unavailable / Do Not Flash" 2 "Reserved" 1 "Fast Flash" 0 "Slow Flash" ;
VAL_ 2566834926 FlashProtectLamp 3 "Unavailable / Do Not Flash" 2 "Reserved" 1 "Fast Flash" 0 "Slow Flash" ;
VAL_ 2566834926 MalfunctionIndicatorLampStatus 3 "Not available" 2 "Reserved" 1 "Lamp on" 0 "Lamp off" ;
VAL_ 2566834926 RedStopLampState 3 "Not available" 2 "Reserved" 1 "Lamp on" 0 "Lamp off" ;
VAL_ 2566834926 AmberWarningLampStatus 3 "Not available" 2 "Reserved" 1 "Lamp on" 0 "Lamp off" ;
VAL_ 2566834926 ProtectLampStatus 3 "Not available" 2 "Reserved" 1 "Lamp on" 0 "Lamp off" ;
VAL_ 2566834768 FailureModeIdentifier5 31 "Not available" 19 "Received network data in error" 18 "Below normal (moderatels severe)" 17 "Below normal (least severe)" 16 "Above normal (moderately severe)" 15 "Above normal (least severe)" 14 "Special intstructions" 13 "Out of calibration" 12 "Bad intelligent device" 11 "Root cause not known" 10 "Abnormal rate of change" 9 "Abnormal update rate" 8 "Abnormal frequency" 7 "Mechanical system not responding" 6 "Current above normal" 5 "Current below normal" 4 "Voltage below normal" 3 "Voltage above normal" 2 "Data erratic" 1 "Below normal (most severe)" 0 "Above normal (most severe)" ;
VAL_ 2566834768 FailureModeIdentifier4 31 "Not available" 19 "Received network data in error" 18 "Below normal (moderatels severe)" 17 "Below normal (least severe)" 16 "Above normal (moderately severe)" 15 "Above normal (least severe)" 14 "Special intstructions" 13 "Out of calibration" 12 "Bad intelligent device" 11 "Root cause not known" 10 "Abnormal rate of change" 9 "Abnormal update rate" 8 "Abnormal frequency" 7 "Mechanical system not responding" 6 "Current above normal" 5 "Current below normal" 4 "Voltage below normal" 3 "Voltage above normal" 2 "Data erratic" 1 "Below normal (most severe)" 0 "Above normal (most severe)" ;
VAL_ 2566834768 FailureModeIdentifier3 31 "Not available" 19 "Received network data in error" 18 "Below normal (moderatels severe)" 17 "Below normal (least severe)" 16 "Above normal (moderately severe)" 15 "Above normal (least severe)" 14 "Special intstructions" 13 "Out of calibration" 12 "Bad intelligent device" 11 "Root cause not known" 10 "Abnormal rate of change" 9 "Abnormal update rate" 8 "Abnormal frequency" 7 "Mechanical system not responding" 6 "Current above normal" 5 "Current below normal" 4 "Voltage below normal" 3 "Voltage above normal" 2 "Data erratic" 1 "Below normal (most severe)" 0 "Above normal (most severe)" ;
VAL_ 2566834768 FailureModeIdentifier2 31 "Not available" 19 "Received network data in error" 18 "Below normal (moderatels severe)" 17 "Below normal (least severe)" 16 "Above normal (moderately severe)" 15 "Above normal (least severe)" 14 "Special intstructions" 13 "Out of calibration" 12 "Bad intelligent device" 11 "Root cause not known" 10 "Abnormal rate of change" 9 "Abnormal update rate" 8 "Abnormal frequency" 7 "Mechanical system not responding" 6 "Current above normal" 5 "Current below normal" 4 "Voltage below normal" 3 "Voltage above normal" 2 "Data erratic" 1 "Below normal (most severe)" 0 "Above normal (most severe)" ;
VAL_ 2566834768 FailureModeIdentifier1 31 "Not available" 19 "Received network data in error" 18 "Below normal (moderatels severe)" 17 "Below normal (least severe)" 16 "Above normal (moderately severe)" 15 "Above normal (least severe)" 14 "Special intstructions" 13 "Out of calibration" 12 "Bad intelligent device" 11 "Root cause not known" 10 "Abnormal rate of change" 9 "Abnormal update rate" 8 "Abnormal frequency" 7 "Mechanical system not responding" 6 "Current above normal" 5 "Current below normal" 4 "Voltage below normal" 3 "Voltage above normal" 2 "Data erratic" 1 "Below normal (most severe)" 0 "Above normal (most severe)" ;
VAL_ 2566834768 FlashMalfuncIndicatorLamp 3 "Unavailable / Do Not Flash" 2 "Reserved" 1 "Fast Flash" 0 "Slow Flash" ;
VAL_ 2566834768 FlashRedStopLamp 3 "Unavailable / Do Not Flash" 2 "Reserved" 1 "Fast Flash" 0 "Slow Flash" ;
VAL_ 2566834768 FlashAmberWarningLamp 3 "Unavailable / Do Not Flash" 2 "Reserved" 1 "Fast Flash" 0 "Slow Flash" ;
VAL_ 2566834768 FlashProtectLamp 3 "Unavailable / Do Not Flash" 2 "Reserved" 1 "Fast Flash" 0 "Slow Flash" ;
VAL_ 2566834768 MalfunctionIndicatorLampStatus 3 "Not available" 2 "Reserved" 1 "Lamp on" 0 "Lamp off" ;
VAL_ 2566834768 RedStopLampState 3 "Not available" 2 "Reserved" 1 "Lamp on" 0 "Lamp off" ;
VAL_ 2566834768 AmberWarningLampStatus 3 "Not available" 2 "Reserved" 1 "Lamp on" 0 "Lamp off" ;
VAL_ 2566834768 ProtectLampStatus 3 "Not available" 2 "Reserved" 1 "Lamp on" 0 "Lamp off" ;
VAL_ 2566834931 FailureModeIdentifier5 31 "Not available" 19 "Received network data in error" 18 "Below normal (moderatels severe)" 17 "Below normal (least severe)" 16 "Above normal (moderately severe)" 15 "Above normal (least severe)" 14 "Special intstructions" 13 "Out of calibration" 12 "Bad intelligent device" 11 "Root cause not known" 10 "Abnormal rate of change" 9 "Abnormal update rate" 8 "Abnormal frequency" 7 "Mechanical system not responding" 6 "Current above normal" 5 "Current below normal" 4 "Voltage below normal" 3 "Voltage above normal" 2 "Data erratic" 1 "Below normal (most severe)" 0 "Above normal (most severe)" ;
VAL_ 2566834931 FailureModeIdentifier4 31 "Not available" 19 "Received network data in error" 18 "Below normal (moderatels severe)" 17 "Below normal (least severe)" 16 "Above normal (moderately severe)" 15 "Above normal (least severe)" 14 "Special intstructions" 13 "Out of calibration" 12 "Bad intelligent device" 11 "Root cause not known" 10 "Abnormal rate of change" 9 "Abnormal update rate" 8 "Abnormal frequency" 7 "Mechanical system not responding" 6 "Current above normal" 5 "Current below normal" 4 "Voltage below normal" 3 "Voltage above normal" 2 "Data erratic" 1 "Below normal (most severe)" 0 "Above normal (most severe)" ;
VAL_ 2566834931 FailureModeIdentifier3 31 "Not available" 19 "Received network data in error" 18 "Below normal (moderatels severe)" 17 "Below normal (least severe)" 16 "Above normal (moderately severe)" 15 "Above normal (least severe)" 14 "Special intstructions" 13 "Out of calibration" 12 "Bad intelligent device" 11 "Root cause not known" 10 "Abnormal rate of change" 9 "Abnormal update rate" 8 "Abnormal frequency" 7 "Mechanical system not responding" 6 "Current above normal" 5 "Current below normal" 4 "Voltage below normal" 3 "Voltage above normal" 2 "Data erratic" 1 "Below normal (most severe)" 0 "Above normal (most severe)" ;
VAL_ 2566834931 FailureModeIdentifier2 31 "Not available" 19 "Received network data in error" 18 "Below normal (moderatels severe)" 17 "Below normal (least severe)" 16 "Above normal (moderately severe)" 15 "Above normal (least severe)" 14 "Special intstructions" 13 "Out of calibration" 12 "Bad intelligent device" 11 "Root cause not known" 10 "Abnormal rate of change" 9 "Abnormal update rate" 8 "Abnormal frequency" 7 "Mechanical system not responding" 6 "Current above normal" 5 "Current below normal" 4 "Voltage below normal" 3 "Voltage above normal" 2 "Data erratic" 1 "Below normal (most severe)" 0 "Above normal (most severe)" ;
VAL_ 2566834931 FailureModeIdentifier1 31 "Not available" 19 "Received network data in error" 18 "Below normal (moderatels severe)" 17 "Below normal (least severe)" 16 "Above normal (moderately severe)" 15 "Above normal (least severe)" 14 "Special intstructions" 13 "Out of calibration" 12 "Bad intelligent device" 11 "Root cause not known" 10 "Abnormal rate of change" 9 "Abnormal update rate" 8 "Abnormal frequency" 7 "Mechanical system not responding" 6 "Current above normal" 5 "Current below normal" 4 "Voltage below normal" 3 "Voltage above normal" 2 "Data erratic" 1 "Below normal (most severe)" 0 "Above normal (most severe)" ;
VAL_ 2566834931 FlashMalfuncIndicatorLamp 3 "Unavailable / Do Not Flash" 2 "Reserved" 1 "Fast Flash" 0 "Slow Flash" ;
VAL_ 2566834931 FlashRedStopLamp 3 "Unavailable / Do Not Flash" 2 "Reserved" 1 "Fast Flash" 0 "Slow Flash" ;
VAL_ 2566834931 FlashAmberWarningLamp 3 "Unavailable / Do Not Flash" 2 "Reserved" 1 "Fast Flash" 0 "Slow Flash" ;
VAL_ 2566834931 FlashProtectLamp 3 "Unavailable / Do Not Flash" 2 "Reserved" 1 "Fast Flash" 0 "Slow Flash" ;
VAL_ 2566834931 MalfunctionIndicatorLampStatus 3 "Not available" 2 "Reserved" 1 "Lamp on" 0 "Lamp off" ;
VAL_ 2566834931 RedStopLampState 3 "Not available" 2 "Reserved" 1 "Lamp on" 0 "Lamp off" ;
VAL_ 2566834931 AmberWarningLampStatus 3 "Not available" 2 "Reserved" 1 "Lamp on" 0 "Lamp off" ;
VAL_ 2566834931 ProtectLampStatus 3 "Not available" 2 "Reserved" 1 "Lamp on" 0 "Lamp off" ;
VAL_ 2566719232 MalFncIndLmpCmd 3 "Not available" 2 "Reserved" 1 "Lamp on" 0 "Lamp off" ;
VAL_ 2566854216 PantographPosition 7 "CCDNotAvailable" 6 "CCDDriveMechanismError" 5 "CCDManuallyRemoved" 4 "ACDFailedToCon/HLCFailedToEst" 3 "Disconnecting/TerminatingHLC" 2 "Connected/HLCEstablished" 1 "Connecting/EstablishingHLC" 0 "NotConnected" ;
VAL_ 2566854216 ChargeState 10 "PlugPresent" 9 "Disconnected" 8 "ConnectionError" 7 "ChargingError" 6 "Disconnecting" 5 "ChargingFinished" 4 "Charging" 3 "Connected" 2 "Connecting" 1 "PreparingConnection" 0 "NoChargeSession" ;
VAL_ 2566854216 ChargeType 7 "NotAvailable" 6 "Reserved" 5 "Reserved" 4 "UMP" 3 "IMP" 2 "RMP" 1 "ComboPlug" 0 "Undefined" ;
VAL_ 2566803211 VDCFullyOperational 3 "DontCare_TakeNoAction" 2 "Reserved" 1 "FullyOperational" 0 "NotFullyOperational" ;
VAL_ 2566803211 VDCInformationSignal 3 "DontCare_TakeNoAction" 2 "Reserved" 1 "On" 0 "Off" ;
VAL_ 2566834942 FailureModeIdentifier5 31 "Not available" 19 "Received network data in error" 18 "Below normal (moderatels severe)" 17 "Below normal (least severe)" 16 "Above normal (moderately severe)" 15 "Above normal (least severe)" 14 "Special intstructions" 13 "Out of calibration" 12 "Bad intelligent device" 11 "Root cause not known" 10 "Abnormal rate of change" 9 "Abnormal update rate" 8 "Abnormal frequency" 7 "Mechanical system not responding" 6 "Current above normal" 5 "Current below normal" 4 "Voltage below normal" 3 "Voltage above normal" 2 "Data erratic" 1 "Below normal (most severe)" 0 "Above normal (most severe)" ;
VAL_ 2566834942 FailureModeIdentifier4 31 "Not available" 19 "Received network data in error" 18 "Below normal (moderatels severe)" 17 "Below normal (least severe)" 16 "Above normal (moderately severe)" 15 "Above normal (least severe)" 14 "Special intstructions" 13 "Out of calibration" 12 "Bad intelligent device" 11 "Root cause not known" 10 "Abnormal rate of change" 9 "Abnormal update rate" 8 "Abnormal frequency" 7 "Mechanical system not responding" 6 "Current above normal" 5 "Current below normal" 4 "Voltage below normal" 3 "Voltage above normal" 2 "Data erratic" 1 "Below normal (most severe)" 0 "Above normal (most severe)" ;
VAL_ 2566834942 FailureModeIdentifier3 31 "Not available" 19 "Received network data in error" 18 "Below normal (moderatels severe)" 17 "Below normal (least severe)" 16 "Above normal (moderately severe)" 15 "Above normal (least severe)" 14 "Special intstructions" 13 "Out of calibration" 12 "Bad intelligent device" 11 "Root cause not known" 10 "Abnormal rate of change" 9 "Abnormal update rate" 8 "Abnormal frequency" 7 "Mechanical system not responding" 6 "Current above normal" 5 "Current below normal" 4 "Voltage below normal" 3 "Voltage above normal" 2 "Data erratic" 1 "Below normal (most severe)" 0 "Above normal (most severe)" ;
VAL_ 2566834942 FailureModeIdentifier2 31 "Not available" 19 "Received network data in error" 18 "Below normal (moderatels severe)" 17 "Below normal (least severe)" 16 "Above normal (moderately severe)" 15 "Above normal (least severe)" 14 "Special intstructions" 13 "Out of calibration" 12 "Bad intelligent device" 11 "Root cause not known" 10 "Abnormal rate of change" 9 "Abnormal update rate" 8 "Abnormal frequency" 7 "Mechanical system not responding" 6 "Current above normal" 5 "Current below normal" 4 "Voltage below normal" 3 "Voltage above normal" 2 "Data erratic" 1 "Below normal (most severe)" 0 "Above normal (most severe)" ;
VAL_ 2566834942 FailureModeIdentifier1 31 "Not available" 19 "Received network data in error" 18 "Below normal (moderatels severe)" 17 "Below normal (least severe)" 16 "Above normal (moderately severe)" 15 "Above normal (least severe)" 14 "Special intstructions" 13 "Out of calibration" 12 "Bad intelligent device" 11 "Root cause not known" 10 "Abnormal rate of change" 9 "Abnormal update rate" 8 "Abnormal frequency" 7 "Mechanical system not responding" 6 "Current above normal" 5 "Current below normal" 4 "Voltage below normal" 3 "Voltage above normal" 2 "Data erratic" 1 "Below normal (most severe)" 0 "Above normal (most severe)" ;
VAL_ 2566834942 FlashMalfuncIndicatorLamp 3 "Unavailable / Do Not Flash" 2 "Reserved" 1 "Fast Flash" 0 "Slow Flash" ;
VAL_ 2566834942 FlashRedStopLamp 3 "Unavailable / Do Not Flash" 2 "Reserved" 1 "Fast Flash" 0 "Slow Flash" ;
VAL_ 2566834942 FlashAmberWarningLamp 3 "Unavailable / Do Not Flash" 2 "Reserved" 1 "Fast Flash" 0 "Slow Flash" ;
VAL_ 2566834942 FlashProtectLamp 3 "Unavailable / Do Not Flash" 2 "Reserved" 1 "Fast Flash" 0 "Slow Flash" ;
VAL_ 2566834942 MalfunctionIndicatorLampStatus 3 "Not available" 2 "Reserved" 1 "Lamp on" 0 "Lamp off" ;
VAL_ 2566834942 RedStopLampState 3 "Not available" 2 "Reserved" 1 "Lamp on" 0 "Lamp off" ;
VAL_ 2566834942 AmberWarningLampStatus 3 "Not available" 2 "Reserved" 1 "Lamp on" 0 "Lamp off" ;
VAL_ 2566834942 ProtectLampStatus 3 "Not available" 2 "Reserved" 1 "Lamp on" 0 "Lamp off" ;
VAL_ 2566880561 AutoKneelEnabled 3 "Not defined" 2 "Not defined" 1 "Active" 0 "Inactive" ;
VAL_ 2566880561 AutoKneelDisabled 3 "Not defined" 2 "Not defined" 1 "Active" 0 "Inactive" ;
VAL_ 2566880561 ECASTractionHelpRq 3 "Not defined" 2 "Not defined" 1 "Active" 0 "Inactive" ;
VAL_ 2566880561 ECASSystemFault 3 "Not defined" 2 "Not defined" 1 "Active" 0 "Inactive" ;
VAL_ 2566880561 ECASServiceMode 3 "Not defined" 2 "Not defined" 1 "Active" 0 "Inactive" ;
VAL_ 2566880561 VehicleHeightStatus 15 "Not Available" 14 "Error" 13 "SideToDrive" 12 "RAxleAtDown" 11 "RAxleToDown" 10 "RSideAtDown" 9 "RSideToDown" 8 "FAxleAtDown" 7 "FAxleToDown" 6 "VehAtUp" 5 "VehToUp" 4 "VehToDrive" 3 "VehAtDown" 2 "VehToDown" 1 "VehAtDrive" 0 "Unknown" ;
VAL_ 2566880049 OilFillerFlapOpen 1 "Open" 0 "Close" ;
VAL_ 2566880049 FuelFlapOpen 1 "Open" 0 "Close" ;
VAL_ 2566880049 On_boardComputerWarning_ITxPT 1 "On" 0 "Off" ;
VAL_ 2566880049 HaltBrakeBuzzerRequest 1 "ON" 0 "OFF" ;
VAL_ 2566880049 ChargeplugFlapOpen 1 "Open" 0 "Close" ;
VAL_ 2566880049 RearFlapOpen 1 "Open" 0 "Close" ;
VAL_ 2566880049 BatteryFlapOpen 1 "Open" 0 "Close" ;
VAL_ 2566880049 ForwardCollisonWarning 1 "ON" 0 "OFF" ;
VAL_ 2566880049 DoorSystemBuzzerRequest 1 "On" 0 "Off" ;
VAL_ 2566880049 ReverseGearBuzzerOff 1 "On" 0 "Off" ;
VAL_ 2566880049 HBOConfirmRequest 1 "On" 0 "Off" ;
VAL_ 2566880049 StopRequestDisabledPass 1 "On" 0 "Off" ;
VAL_ 2566880049 StopRequest 1 "On" 0 "Off" ;
VAL_ 2566880049 FrostWarning 1 "On" 0 "Off" ;
VAL_ 2566880049 EmergencyHammers 1 "On" 0 "Off" ;
VAL_ 2566880049 ASRSwitchActive 1 "On" 0 "Off" ;
VAL_ 2566880049 EBISwitchOff 1 "On" 0 "Off" ;
VAL_ 2566880049 HaltbrakeOverrule 1 "On" 0 "Off" ;
VAL_ 2566880049 HaltbrakeActive 1 "On" 0 "Off" ;
VAL_ 2566880049 HVHeaterActive 1 "On" 0 "Off" ;
VAL_ 2566880049 HillHolderState 1 "On" 0 "Off" ;
VAL_ 2566880049 AuxHeaterActive 1 "On" 0 "Off" ;
VAL_ 2566880049 AlarmPassengers 1 "On" 0 "Off" ;
VAL_ 2566880049 AEBSSwitchedOff 1 "On" 0 "Off" ;
VAL_ 2566880049 AutoWipersActive 1 "On" 0 "Off" ;
VAL_ 2566880049 DirectionIndicatorTrailer 1 "On" 0 "Off" ;
VAL_ 2566880049 DirectionIndicatorRe 1 "On" 0 "Off" ;
VAL_ 2566880049 DirectionIndicatorLe 1 "On" 0 "Off" ;
VAL_ 2566880049 FrontFogLight 1 "On" 0 "Off" ;
VAL_ 2566880049 RearFogLight 1 "On" 0 "Off" ;
VAL_ 2566880049 HighBeam 1 "On" 0 "Off" ;
VAL_ 2566880049 LowBeam 1 "On" 0 "Off" ;
VAL_ 2566880049 PositionLight 1 "On" 0 "Off" ;
VAL_ 2566880049 PressureCircuit3_4Low 1 "On" 0 "Off" ;
VAL_ 2566880049 PressureCircuit1_2Low 1 "On" 0 "Off" ;
VAL_ 2566880049 FuelLevelLow 1 "On" 0 "Off" ;
VAL_ 2566880049 ECASDisabled 1 "On" 0 "Off" ;
VAL_ 2566880049 SeatbeltBuzzerWarning 1 "On" 0 "Off" ;
VAL_ 2566880049 SeatBeltWarning 1 "On" 0 "Off" ;
VAL_ 2566880049 WiperFluidLevelLow 1 "On" 0 "Off" ;
VAL_ 2566880049 EASNotification 1 "On" 0 "Off" ;
VAL_ 2566880049 RegenerationImpossible 1 "On" 0 "Off" ;
VAL_ 2566880049 RegenerationInhibited 1 "On" 0 "Off" ;
VAL_ 2566880049 EmergencyDoorOpen 1 "On" 0 "Off" ;
VAL_ 2566880049 CoolantLevelToLow 1 "On" 0 "Off" ;
VAL_ 2566880049 CoolantLevelLow 1 "On" 0 "Off" ;
VAL_ 2566851111 RearFlapOpen 1 "Open" 0 "Close" ;
VAL_ 2566851111 BlindSpotDetectionIndication 3 "Not available" 2 "Level 2" 1 "Level 1" 0 "Inactive" ;
VAL_ 2566851111 HazardLightsRequest 3 "NotAvailable" 2 "Error" 1 "HazardLampsToBeFlashing" 0 "HazardLampsToBeOff" ;
VAL_ 2566851111 VoltageLow 3 "Voltage Low" 2 "Error" 1 "Not Available" 0 "No issue" ;
VAL_ 2566851111 PantographRaised 3 "NA" 2 "Error" 1 "Pantograph raised" 0 "No Pantrograph raised" ;
VAL_ 2566851111 TractionHelpRequest 3 "Na" 2 "Error" 1 "Traction help" 0 "No traction help" ;
VAL_ 2566851111 Axle3Present 3 "Not Available" 2 "Error" 1 "3rd axle present" 0 "No 3rd axle present" ;
VAL_ 2566851111 PowerLimitation 1 "Power Limitation" 0 "No Limitation" ;
VAL_ 2566851111 VehicleState 5 "Inhibit" 4 "Driving Reverse" 3 "Driving Forward" 2 "Stationary" 1 "Parked" 0 "Vehicle Off" ;
VAL_ 2566851111 PowerSupplyState 15 "NA" 14 "Reserved " 13 "Reserved " 12 "Reserved " 11 "Reserved " 10 "Reserved " 9 "Reserved " 8 "Reserved " 7 "Reserved " 6 "Reserved " 5 "Emergency Switch On" 4 "After run" 3 "Ignition switch" 2 "Accessory switch" 1 "Wake up" 0 "Vehicle Off" ;
VAL_ 2566880535 AQSSensorResponseError 3 "Not Available" 2 "Error" 1 "Error Active" 0 "No Error" ;
VAL_ 2566880535 AQSAirQuality 15 "Failure" 14 "Init" 13 "High Pollution" 9 "Air Quality 90%" 8 "Air Quality 80%" 7 "Air Quality 70%" 6 "Air Quality 60%" 5 "Air Quality 50%" 4 "Air Quality 40%" 3 "Air Quality 30%" 2 "Air Quality 20%" 1 "Air Quality 10%" 0 "Clean Air" ;
VAL_ 2566880535 CO2SensorResponseError 3 "Not Available" 2 "Error" 1 "Error Active" 0 "No Error" ;
VAL_ 2566880535 CO2SensorReady 3 "Not Available" 2 "Error" 1 "Ready" 0 "Not Ready" ;
VAL_ 2566880535 CO2SensorInternalError 3 "Not Available" 2 "Error" 1 "Error Active" 0 "No Error" ;
VAL_ 2566880535 ATCFunctionRequest 1 "On" 0 "Off" ;
VAL_ 2566880535 HBOFunctionRequest 1 "On" 0 "Off" ;
VAL_ 2566880535 EBIFunctionRequest 1 "On" 0 "Off" ;
VAL_ 2566880535 AutomaticBrightness 1 "On" 0 "Off" ;
VAL_ 2566880535 TPRSReset 1 "On" 0 "Off" ;
VAL_ 2566880535 ACCUserEnableReq 1 "On" 0 "Off" ;
VAL_ 2566880535 ACCScreenActive 1 "On" 0 "Off" ;
VAL_ 2566880535 EASPopupReset 1 "On" 0 "Off" ;
VAL_ 2365484270 DirectionIndicator 3 "NotAvailable" 2 "Error" 1 "Reverse" 0 "Forward" ;
VAL_ 2365484270 HandlingInformation 3 "NotAvailable" 2 "Error" 1 "HandlingInformation" 0 "NoHandlingInformation" ;
VAL_ 2365484270 SystemEvent 3 "NotAvailable" 2 "Error" 1 "TachographEvent" 0 "NoTachographEvent" ;
VAL_ 2365484270 Overspeed 3 "NotAvailable" 2 "Error" 1 "Overspeed" 0 "NoOverspeed" ;
VAL_ 2365484270 TachographPerformance 3 "NotAvailable" 2 "Error" 1 "PerformanceAnalysis" 0 "NormalPerformance" ;
VAL_ 2365484270 DriveRecognize 3 "NotAvailable" 2 "Error" 1 "VehicleMotionDetected" 0 "VehicleMotionNotDetected" ;
VAL_ 2365484270 DriverCardDriver2 3 "NotAvailable" 2 "Error" 1 "DriverCardPresent" 0 "DriverCardNotPresent" ;
VAL_ 2365484270 DriverCardDriver1 3 "NotAvailable" 2 "Error" 1 "DriverCardPresent" 0 "DriverCardNotPresent" ;
VAL_ 2365484270 Driver2WorkingState 7 "NotAvailable" 6 "Error" 4 "101Reserved" 3 "DriveBehindWheel" 2 "WrkLdngUnldingWorkingInAnOffice" 1 "DriverAvailableShortBreak" 0 "RestSleeping" ;
VAL_ 2365484270 Driver2TimeRelatedStates 15 "NotAvailable" 14 "Error" 13 "Other" 7 "1100Reserved" 6 "Limit616HReached" 5 "Limit515MinBefore16H" 4 "Limit49HReached" 3 "Limit315MinBefore9H" 2 "Limit24HReached" 1 "Limit115MinBefore4H" 0 "Normal_NoLimitsReached" ;
VAL_ 2365484270 Driver1WorkingState 7 "NotAvailable" 6 "Error" 4 "101Reserved" 3 "DriveBehindWheel" 2 "WrkLdngUnldingWorkingInAnOffice" 1 "DriverAvailableShortBreak" 0 "RestSleeping" ;
VAL_ 2365484270 Driver1TimeRelatedStates 15 "NotAvailable" 14 "Error" 13 "Other" 7 "1100Reserved" 6 "Limit616HReached" 5 "Limit515MinBefore16H" 4 "Limit49HReached" 3 "Limit315MinBefore9H" 2 "Limit24HReached" 1 "Limit115MinBefore4H" 0 "Normal_NoLimitsReached" ;
VAL_ 2566876209 DoorStatus4 9 "AllLocked" 8 "1WingOpen" 7 "1WingClosed" 6 "AllErrorOpen" 5 "AllPressurelessOpen" 4 "2WingBothOpen" 3 "2WingRearOpen" 2 "2WingFrontOpen" 1 "2WingBothClosed" 0 "NotAvailable" ;
VAL_ 2566876209 DoorStatus3 9 "AllLocked" 8 "1WingOpen" 7 "1WingClosed" 6 "AllErrorOpen" 5 "AllPressurelessOpen" 4 "2WingBothOpen" 3 "2WingRearOpen" 2 "2WingFrontOpen" 1 "2WingBothClosed" 0 "NotAvailable" ;
VAL_ 2566876209 DoorStatus2 9 "AllLocked" 8 "1WingOpen" 7 "1WingClosed" 6 "AllErrorOpen" 5 "AllPressurelessOpen" 4 "2WingBothOpen" 3 "2WingRearOpen" 2 "2WingFrontOpen" 1 "2WingBothClosed" 0 "NotAvailable" ;
VAL_ 2566876209 DoorStatus1 9 "AllLocked" 8 "1WingOpen" 7 "1WingClosed" 6 "AllErrorOpen" 5 "AllPressurelessOpen" 4 "2WingBothOpen" 3 "2WingRearOpen" 2 "2WingFrontOpen" 1 "2WingBothClosed" 0 "NotAvailable" ;
VAL_ 2566866737 TPMSOptionActivation 3 "Not Available" 2 "Error" 1 "Active" 0 "Inactive" ;
VAL_ 2566866737 Tire8StatusInformation 15 "Not Available" 14 "Error" 13 "Reserved" 12 "Reserved" 11 "Reserved" 10 "Reserved" 9 "Data not available" 8 "High Temperature" 7 "System Warning" 6 "Battery Low Warning" 5 "Pressure Difference Warning" 4 "Too Low PressureWarning" 3 "Low Pressure Warning" 2 "High Pressure Warning" 1 "Too High Pressure Warning" 0 "Tire OK" ;
VAL_ 2566866737 Tire8Pressure 255 "Not Available" 254 "Error" ;
VAL_ 2566866737 Tire7StatusInformation 15 "Not Available" 14 "Error" 13 "Reserved" 12 "Reserved" 11 "Reserved" 10 "Reserved" 9 "Data not available" 8 "High Temperature" 7 "System Warning" 6 "Battery Low Warning" 5 "Pressure Difference Warning" 4 "Too Low PressureWarning" 3 "Low Pressure Warning" 2 "High Pressure Warning" 1 "Too High Pressure Warning" 0 "Tire OK" ;
VAL_ 2566866737 Tire7Pressure 255 "Not Available" 254 "Error" ;
VAL_ 2566866737 Tire6StatusInformation 15 "Not Available" 14 "Error" 13 "Reserved" 12 "Reserved" 11 "Reserved" 10 "Reserved" 9 "Data not available" 8 "High Temperature" 7 "System Warning" 6 "Battery Low Warning" 5 "Pressure Difference Warning" 4 "Too Low PressureWarning" 3 "Low Pressure Warning" 2 "High Pressure Warning" 1 "Too High Pressure Warning" 0 "Tire OK" ;
VAL_ 2566866737 Tire5StatusInformation 15 "Not Available" 14 "Error" 13 "Reserved" 12 "Reserved" 11 "Reserved" 10 "Reserved" 9 "Data not available" 8 "High Temperature" 7 "System Warning" 6 "Battery Low Warning" 5 "Pressure Difference Warning" 4 "Too Low PressureWarning" 3 "Low Pressure Warning" 2 "High Pressure Warning" 1 "Too High Pressure Warning" 0 "Tire OK" ;
VAL_ 2566866481 Tire6Pressure 255 "Not Available" 254 "Error" ;
VAL_ 2566866481 Tire5Pressure 255 "Not Available" 254 "Error" ;
VAL_ 2566866481 Tire4StatusInformation 15 "Not Available" 14 "Error" 13 "Reserved" 12 "Reserved" 11 "Reserved" 10 "Reserved" 9 "Data not available" 8 "High Temperature" 7 "System Warning" 6 "Battery Low Warning" 5 "Pressure Difference Warning" 4 "Too Low PressureWarning" 3 "Low Pressure Warning" 2 "High Pressure Warning" 1 "Too High Pressure Warning" 0 "Tire OK" ;
VAL_ 2566866481 Tire4Pressure 255 "Not Available" 254 "Error" ;
VAL_ 2566866481 Tire3StatusInformation 15 "Not Available" 14 "Error" 13 "Reserved" 12 "Reserved" 11 "Reserved" 10 "Reserved" 9 "Data not available" 8 "High Temperature" 7 "System Warning" 6 "Battery Low Warning" 5 "Pressure Difference Warning" 4 "Too Low PressureWarning" 3 "Low Pressure Warning" 2 "High Pressure Warning" 1 "Too High Pressure Warning" 0 "Tire OK" ;
VAL_ 2566866481 Tire3Pressure 255 "Not Available" 254 "Error" ;
VAL_ 2566866481 Tire2StatusInformation 15 "Not Available" 14 "Error" 13 "Reserved" 12 "Reserved" 11 "Reserved" 10 "Reserved" 9 "Data not available" 8 "High Temperature" 7 "System Warning" 6 "Battery Low Warning" 5 "Pressure Difference Warning" 4 "Too Low PressureWarning" 3 "Low Pressure Warning" 2 "High Pressure Warning" 1 "Too High Pressure Warning" 0 "Tire OK" ;
VAL_ 2566866481 Tire2Pressure 255 "Not Available" 254 "Error" ;
VAL_ 2566866481 Tire1StatusInformation 15 "Not Available" 14 "Error" 13 "Reserved" 12 "Reserved" 11 "Reserved" 10 "Reserved" 9 "Data not available" 8 "High Temperature" 7 "System Warning" 6 "Battery Low Warning" 5 "Pressure Difference Warning" 4 "Too Low PressureWarning" 3 "Low Pressure Warning" 2 "High Pressure Warning" 1 "Too High Pressure Warning" 0 "Tire OK" ;
VAL_ 2566866481 Tire1Pressure 255 "Not Available" 254 "Error" ;
